VERSION ""

NS_ :

BS_:

BU_: PowertrainControlModule AtmosphericSensor SafetyRestraintSystem2 Aftertreatment_2_GasOutlet Aftertreatment_2_GasIntake DieselParticulateFilterControl Turbocharger SafetyRestraintSystem1 CabDisplay2 Aftertreatment_1_GasOutlet Aftertreatment_1_GasIntake OnBoardDataLogger OffBoardDiagnosticTool2 OffBoardDiagnosticTool1 FileServer ParkingBrakeController SeatController2 FanDriveController SteeringColumnUnit CommunicationUnitRadio CommunicationUnitSatellite CommunicationUnitCellular PropulsionBatteryCharger ChassisController2 ChassisController1 EngineValveControl AuxiliaryHeater2 AuxiliaryHeater1 ClutchUnit RampControl InformationSystem1 SuspensionSystemController2 OilSensor VehicleDynamicStability ExhaustEmissionController TransmissionDisplay2 TransmissionDisplay1 ClimateControl2 WaterPumpController RearAxleSteeringController LightingOperatorControl SeatController1 IgnitionController2 IgnitionController1 TirePressureController CabController2 CabController1 PneumaticSystemController SuspensionSystemController1 HydraulicPumpController EnduranceBrakingSystem RetarderExhaustEngine2 OnBoardDiagnosticUnit HeadwayController RetarderExhaustEngine1 CabDisplay1 ManagementComputer VirtualTerminal OffVehicleGateway PowerTakeOffFront HitchControl AuxiliaryValveControl BodyController TractorTrailerBridge1 StarterSystem ElectricalSystem VehicleSecurity VehicleNavigation AerodynamicControl ElectricalChargingSystem ClimateControl1 TripRecorder InstrumentCluster SuspensionDriveAxle2 SuspensionDriveAxle1 SuspensionSteerAxle SteeringController FuelSystem CruiseControl RetarderDriveline RetarderEngine BrakesDriveAxle2 BrakesDriveAxle1 BrakesSystemController BrakesSteerAxle AxleDrive2 AxleDrive1 AxleSteering PowerTakeOff ShiftConsoleSecondary ShiftConsolePrimary Transmission2 Transmission1 Engine2 Engine1

BO_ 2365402110 EJM6: 8 Vector__XXX
 SG_ Joystick6Button13PressedStatus : 62|2@1+ (1,0) [0|3] "" Vector__XXX
 SG_ Joystick6Button14PressedStatus : 60|2@1+ (1,0) [0|3] "" Vector__XXX
 SG_ Joystick6Button15PressedStatus : 58|2@1+ (1,0) [0|3] "" Vector__XXX
 SG_ Joystick6Button16PressedStatus : 56|2@1+ (1,0) [0|3] "" Vector__XXX
 SG_ Jystick6GripXAxisDetentPosStatus : 54|2@1+ (1,0) [0|3] "" Vector__XXX
 SG_ Jystick6GripYAxisDetentPosStatus : 52|2@1+ (1,0) [0|3] "" Vector__XXX
 SG_ Jystick6ThetaAxisDetentPosStatus : 50|2@1+ (1,0) [0|3] "" Vector__XXX
 SG_ Joystick6ThetaAxisPos : 38|10@1+ (0.1,0) [0|102] "%" Vector__XXX
 SG_ Jystck6ThtAxsClckwsPstvPosStatus : 36|2@1+ (1,0) [0|3] "" Vector__XXX
 SG_ Jystck6ThtAxsCntrClckwsNgtvPsStt : 34|2@1+ (1,0) [0|3] "" Vector__XXX
 SG_ Jystck6ThetaAxisNeutralPosStatus : 32|2@1+ (1,0) [0|3] "" Vector__XXX
 SG_ Joystick6GripYAxisPos : 22|10@1+ (0.1,0) [0|102] "%" Vector__XXX
 SG_ Jystck6GrpYAxsLvrFrwrdPstvPsStts : 20|2@1+ (1,0) [0|3] "" Vector__XXX
 SG_ Jystck6GrpYAxsLvrBckNgtvPsStatus : 18|2@1+ (1,0) [0|3] "" Vector__XXX
 SG_ Jystck6GripYAxisNeutralPosStatus : 16|2@1+ (1,0) [0|3] "" Vector__XXX
 SG_ Joystick6GripXAxisPos : 6|10@1+ (0.1,0) [0|102] "%" Vector__XXX
 SG_ Jystck6GrpXAxsLvrRghtPstvPsSttus : 4|2@1+ (1,0) [0|3] "" Vector__XXX
 SG_ Jystck6GrpXAxsLvrLftNgtvPsStatus : 2|2@1+ (1,0) [0|3] "" Vector__XXX
 SG_ Jystck6GripXAxisNeutralPosStatus : 0|2@1+ (1,0) [0|3] "" Vector__XXX

BO_ 2365402622 EJM5: 8 Vector__XXX
 SG_ Joystick5Button13PressedStatus : 62|2@1+ (1,0) [0|3] "" Vector__XXX
 SG_ Joystick5Button14PressedStatus : 60|2@1+ (1,0) [0|3] "" Vector__XXX
 SG_ Joystick5Button15PressedStatus : 58|2@1+ (1,0) [0|3] "" Vector__XXX
 SG_ Joystick5Button16PressedStatus : 56|2@1+ (1,0) [0|3] "" Vector__XXX
 SG_ Jystick5GripXAxisDetentPosStatus : 54|2@1+ (1,0) [0|3] "" Vector__XXX
 SG_ Jystick5GripYAxisDetentPosStatus : 52|2@1+ (1,0) [0|3] "" Vector__XXX
 SG_ Jystick5ThetaAxisDetentPosStatus : 50|2@1+ (1,0) [0|3] "" Vector__XXX
 SG_ Joystick5ThetaAxisPos : 38|10@1+ (0.1,0) [0|102] "%" Vector__XXX
 SG_ Jystck5ThtAxsClckwsPstvPosStatus : 36|2@1+ (1,0) [0|3] "" Vector__XXX
 SG_ Jystck5ThtAxsCntrClckwsNgtvPsStt : 34|2@1+ (1,0) [0|3] "" Vector__XXX
 SG_ Jystck5ThetaAxisNeutralPosStatus : 32|2@1+ (1,0) [0|3] "" Vector__XXX
 SG_ Joystick5GripYAxisPos : 22|10@1+ (0.1,0) [0|102] "%" Vector__XXX
 SG_ Jystck5GrpYAxsLvrFrwrdPstvPsStts : 20|2@1+ (1,0) [0|3] "" Vector__XXX
 SG_ Jystck5GrpYAxsLvrBckNgtvPsStatus : 18|2@1+ (1,0) [0|3] "" Vector__XXX
 SG_ Jystck5GripYAxisNeutralPosStatus : 16|2@1+ (1,0) [0|3] "" Vector__XXX
 SG_ Joystick5GripXAxisPos : 6|10@1+ (0.1,0) [0|102] "%" Vector__XXX
 SG_ Jystck5GrpXAxsLvrRghtPstvPsSttus : 4|2@1+ (1,0) [0|3] "" Vector__XXX
 SG_ Jystck5GrpXAxsLvrLftNgtvPsStatus : 2|2@1+ (1,0) [0|3] "" Vector__XXX
 SG_ Jystck5GripXAxisNeutralPosStatus : 0|2@1+ (1,0) [0|3] "" Vector__XXX

BO_ 2365403134 EJM4: 8 Vector__XXX
 SG_ Joystick4Button13PressedStatus : 62|2@1+ (1,0) [0|3] "" Vector__XXX
 SG_ Joystick4Button14PressedStatus : 60|2@1+ (1,0) [0|3] "" Vector__XXX
 SG_ Joystick4Button15PressedStatus : 58|2@1+ (1,0) [0|3] "" Vector__XXX
 SG_ Joystick4Button16PressedStatus : 56|2@1+ (1,0) [0|3] "" Vector__XXX
 SG_ Jystick4GripXAxisDetentPosStatus : 54|2@1+ (1,0) [0|3] "" Vector__XXX
 SG_ Jystick4GripYAxisDetentPosStatus : 52|2@1+ (1,0) [0|3] "" Vector__XXX
 SG_ Jystick4ThetaAxisDetentPosStatus : 50|2@1+ (1,0) [0|3] "" Vector__XXX
 SG_ Joystick4ThetaAxisPos : 38|10@1+ (0.1,0) [0|102] "%" Vector__XXX
 SG_ Jystck4ThtAxsClckwsPstvPosStatus : 36|2@1+ (1,0) [0|3] "" Vector__XXX
 SG_ Jystck4ThtAxsCntrClckwsNgtvPsStt : 34|2@1+ (1,0) [0|3] "" Vector__XXX
 SG_ Jystck4ThetaAxisNeutralPosStatus : 32|2@1+ (1,0) [0|3] "" Vector__XXX
 SG_ Joystick4GripYAxisPos : 22|10@1+ (0.1,0) [0|102] "%" Vector__XXX
 SG_ Jystck4GrpYAxsLvrFrwrdPstvPsStts : 20|2@1+ (1,0) [0|3] "" Vector__XXX
 SG_ Jystck4GrpYAxsLvrBckNgtvPsStatus : 18|2@1+ (1,0) [0|3] "" Vector__XXX
 SG_ Jystck4GripYAxisNeutralPosStatus : 16|2@1+ (1,0) [0|3] "" Vector__XXX
 SG_ Joystick4GripXAxisPos : 6|10@1+ (0.1,0) [0|102] "%" Vector__XXX
 SG_ Jystck4GrpXAxsLvrRghtPstvPsSttus : 4|2@1+ (1,0) [0|3] "" Vector__XXX
 SG_ Jystck4GrpXAxsLvrLftNgtvPsStatus : 2|2@1+ (1,0) [0|3] "" Vector__XXX
 SG_ Jystck4GripXAxisNeutralPosStatus : 0|2@1+ (1,0) [0|3] "" Vector__XXX

BO_ 2365400062 EJM10: 8 Vector__XXX
 SG_ Joystick10Button13PressedStatus : 62|2@1+ (1,0) [0|3] "" Vector__XXX
 SG_ Joystick10Button14PressedStatus : 60|2@1+ (1,0) [0|3] "" Vector__XXX
 SG_ Joystick10Button15PressedStatus : 58|2@1+ (1,0) [0|3] "" Vector__XXX
 SG_ Joystick10Button16PressedStatus : 56|2@1+ (1,0) [0|3] "" Vector__XXX
 SG_ Jystck10GripXAxisDetentPosStatus : 54|2@1+ (1,0) [0|3] "" Vector__XXX
 SG_ Jystck10GripYAxisDetentPosStatus : 52|2@1+ (1,0) [0|3] "" Vector__XXX
 SG_ Jystck10ThetaAxisDetentPosStatus : 50|2@1+ (1,0) [0|3] "" Vector__XXX
 SG_ Joystick10ThetaAxisPos : 38|10@1+ (0.1,0) [0|102] "%" Vector__XXX
 SG_ Jystck10ThtAxsClckwsPstvPsStatus : 36|2@1+ (1,0) [0|3] "" Vector__XXX
 SG_ Jystck10ThtAxsCntrClckwsNgtvPsSt : 34|2@1+ (1,0) [0|3] "" Vector__XXX
 SG_ Jystck10ThtaAxisNeutralPosStatus : 32|2@1+ (1,0) [0|3] "" Vector__XXX
 SG_ Joystick10GripYAxisPos : 22|10@1+ (0.1,0) [0|102] "%" Vector__XXX
 SG_ Jystck10GrpYAxsLvrFrwrdPstvPsStt : 20|2@1+ (1,0) [0|3] "" Vector__XXX
 SG_ Jystck10GrpYAxsLvrBckNgtvPsSttus : 18|2@1+ (1,0) [0|3] "" Vector__XXX
 SG_ Jystck10GrpYAxisNeutralPosStatus : 16|2@1+ (1,0) [0|3] "" Vector__XXX
 SG_ Joystick10GripXAxisPos : 6|10@1+ (0.1,0) [0|102] "%" Vector__XXX
 SG_ Jystck10GrpXAxsLvrRghtPstvPsStts : 4|2@1+ (1,0) [0|3] "" Vector__XXX
 SG_ Jystck10GrpXAxsLvrLftNgtvPsSttus : 2|2@1+ (1,0) [0|3] "" Vector__XXX
 SG_ Jystck10GrpXAxisNeutralPosStatus : 0|2@1+ (1,0) [0|3] "" Vector__XXX

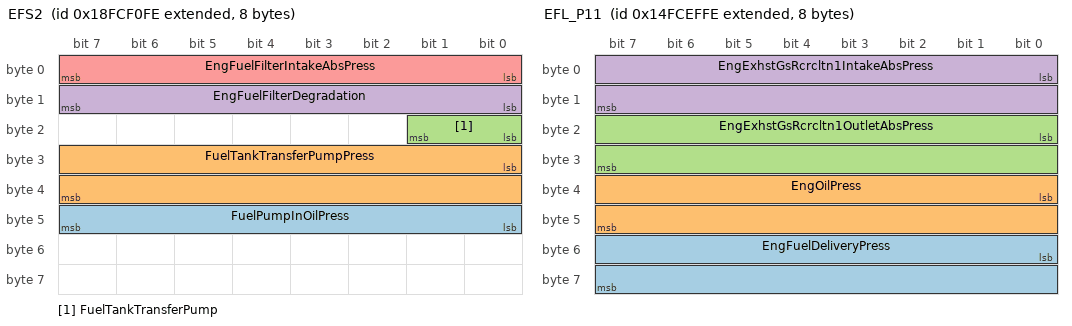
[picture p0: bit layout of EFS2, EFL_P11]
BO_ 2566713598 EFS2: 8 Vector__XXX
 SG_ FuelPumpInOilPress : 40|8@1+ (4,0) [0|1000] "kPa" Vector__XXX
 SG_ FuelTankTransferPumpPress : 24|16@1+ (0.1,0) [0|6425.5] "kPa" Vector__XXX
 SG_ FuelTankTransferPump : 16|2@1+ (1,0) [0|3] "" Vector__XXX
 SG_ EngFuelFilterDegradation : 8|8@1+ (1,0) [0|250] "%" Vector__XXX
 SG_ EngFuelFilterIntakeAbsPress : 0|8@1+ (2,0) [0|500] "kPa" Vector__XXX

BO_ 2499604478 EFL_P11: 8 Vector__XXX
 SG_ EngFuelDeliveryPress : 48|16@1+ (0.1,0) [0|6425.5] "kPa" Vector__XXX
 SG_ EngOilPress : 32|16@1+ (0.1,0) [0|6425.5] "kPa" Vector__XXX
 SG_ EngExhstGsRcrcltn1OutletAbsPress : 16|16@1+ (0.1,0) [0|6425.5] "kPa" Vector__XXX
 SG_ EngExhstGsRcrcltn1IntakeAbsPress : 0|16@1+ (0.1,0) [0|6425.5] "kPa" Vector__XXX

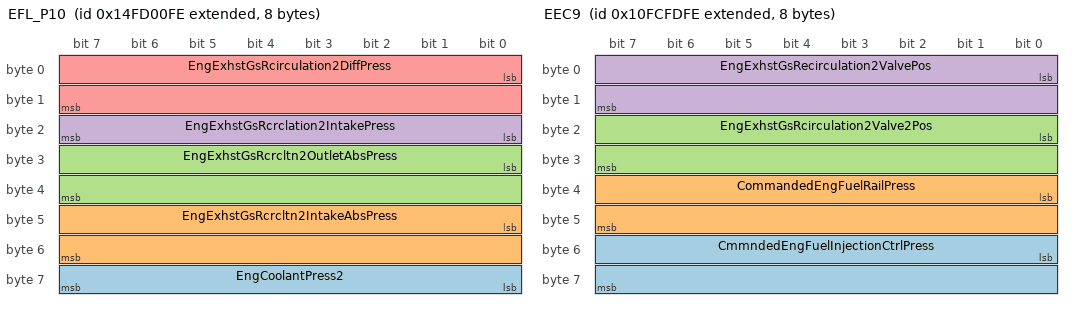
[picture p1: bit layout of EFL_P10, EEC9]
BO_ 2499608830 EFL_P10: 8 Vector__XXX
 SG_ EngCoolantPress2 : 56|8@1+ (2,0) [0|500] "kPa" Vector__XXX
 SG_ EngExhstGsRcrcltn2IntakeAbsPress : 40|16@1+ (0.1,0) [0|6425.5] "kPa" Vector__XXX
 SG_ EngExhstGsRcrcltn2OutletAbsPress : 24|16@1+ (0.1,0) [0|6425.5] "kPa" Vector__XXX
 SG_ EngExhstGsRcrclation2IntakePress : 16|8@1+ (2,0) [0|500] "kPa" Vector__XXX
 SG_ EngExhstGsRcirculation2DiffPress : 0|16@1+ (0.0078125,-250) [-250|251.99] "kPa" Vector__XXX

BO_ 2432499198 EEC9: 8 Vector__XXX
 SG_ CmmndedEngFuelInjectionCtrlPress : 48|16@1+ (0.00390625,0) [0|250.996] "MPa" Vector__XXX
 SG_ CommandedEngFuelRailPress : 32|16@1+ (0.00390625,0) [0|250.996] "MPa" Vector__XXX
 SG_ EngExhstGsRcirculation2Valve2Pos : 16|16@1+ (0.0025,0) [0|160.6375] "%" Vector__XXX
 SG_ EngExhstGsRecirculation2ValvePos : 0|16@1+ (0.0025,0) [0|160.6375] "%" Vector__XXX

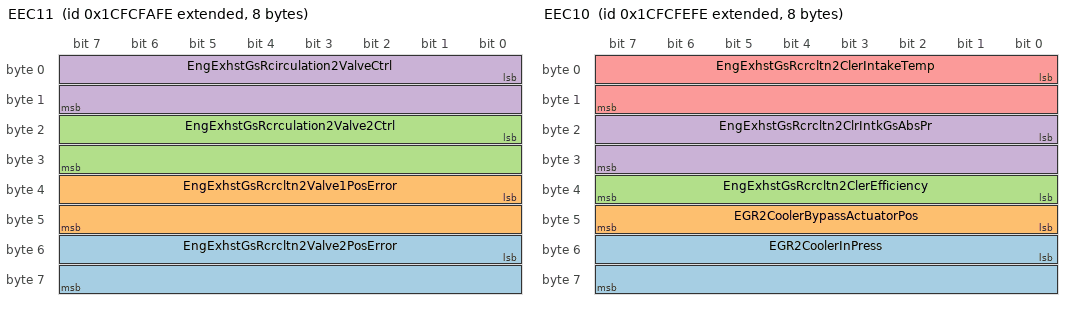
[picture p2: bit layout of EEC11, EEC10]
BO_ 2633825022 EEC11: 8 Vector__XXX
 SG_ EngExhstGsRcrcltn2Valve2PosError : 48|16@1+ (0.004,-125) [-125|132.02] "%" Vector__XXX
 SG_ EngExhstGsRcrcltn2Valve1PosError : 32|16@1+ (0.004,-125) [-125|132.02] "%" Vector__XXX
 SG_ EngExhstGsRcrculation2Valve2Ctrl : 16|16@1+ (0.0025,0) [0|160.6375] "%" Vector__XXX
 SG_ EngExhstGsRcirculation2ValveCtrl : 0|16@1+ (0.0025,0) [0|160.6375] "%" Vector__XXX

BO_ 2633826046 EEC10: 8 Vector__XXX
 SG_ EGR2CoolerInPress : 48|16@1+ (5,0) [0|321275] "kPa" Vector__XXX
 SG_ EGR2CoolerBypassActuatorPos : 40|8@1+ (0.4,0) [0|100] "%" Vector__XXX
 SG_ EngExhstGsRcrcltn2ClerEfficiency : 32|8@1+ (0.4,0) [0|100] "%" Vector__XXX
 SG_ EngExhstGsRcrcltn2ClrIntkGsAbsPr : 16|16@1+ (0.5,0) [0|32127.5] "kPa" Vector__XXX
 SG_ EngExhstGsRcrcltn2ClerIntakeTemp : 0|16@1+ (0.03125,-273) [-273|1734.96875] "캜" Vector__XXX

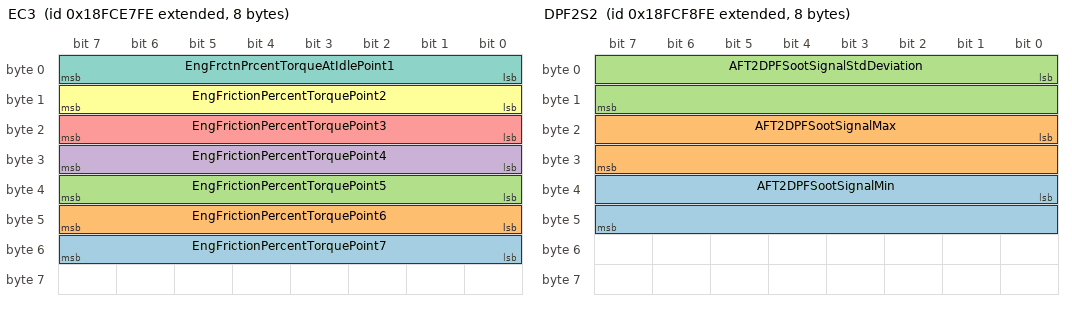
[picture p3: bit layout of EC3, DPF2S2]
BO_ 2566711294 EC3: 8 Vector__XXX
 SG_ EngFrictionPercentTorquePoint7 : 48|8@1+ (1,-125) [0|125] "%" Vector__XXX
 SG_ EngFrictionPercentTorquePoint6 : 40|8@1+ (1,-125) [0|125] "%" Vector__XXX
 SG_ EngFrictionPercentTorquePoint5 : 32|8@1+ (1,-125) [0|125] "%" Vector__XXX
 SG_ EngFrictionPercentTorquePoint4 : 24|8@1+ (1,-125) [0|125] "%" Vector__XXX
 SG_ EngFrictionPercentTorquePoint3 : 16|8@1+ (1,-125) [0|125] "%" Vector__XXX
 SG_ EngFrictionPercentTorquePoint2 : 8|8@1+ (1,-125) [0|125] "%" Vector__XXX
 SG_ EngFrctnPrcentTorqueAtIdlePoint1 : 0|8@1+ (1,-125) [0|125] "%" Vector__XXX

BO_ 2566749438 DPFC1: 8 Vector__XXX
 SG_ ActiveRegenAvailabilityStatus : 3|2@1+ (1,0) [0|3] "" Vector__XXX
 SG_ DslPrtcltFltrActvRgnrtnInhbt5629 : 58|2@1+ (1,0) [0|3] "" Vector__XXX
 SG_ AFT1DPFCondNotMetForActiveRegen : 60|2@1+ (1,0) [0|3] "" Vector__XXX
 SG_ HydrocarbonDoserPurgingEnable : 56|2@1+ (1,0) [0|3] "" Vector__XXX
 SG_ DslPrtcltFltrActvRgnrtnFrcdSttus : 53|3@1+ (1,0) [0|7] "" Vector__XXX
 SG_ ExhaustSystemHighTempLampCmd : 50|3@1+ (1,0) [0|7] "" Vector__XXX
 SG_ DslPrtcltFltrAtmtcActvRgnrtnIntt : 48|2@1+ (1,0) [0|3] "" Vector__XXX
 SG_ DslPrtcltFltrActvRgnrtnInhbt3717 : 46|2@1+ (1,0) [0|3] "" Vector__XXX
 SG_ DslPrtcltFltrActvRgnrtnInhbtdDTE : 44|2@1+ (1,0) [0|3] "" Vector__XXX
 SG_ DslPrtcltFltrActvRgnrtnInhbt3715 : 42|2@1+ (1,0) [0|3] "" Vector__XXX
 SG_ DslPrtcltFltrActvRgnrtnInhbtdDTT : 40|2@1+ (1,0) [0|3] "" Vector__XXX
 SG_ DslPrtcltFltrActvRgnrtnInhbt3713 : 38|2@1+ (1,0) [0|3] "" Vector__XXX
 SG_ DslPrtcltFltrActvRgnrtnInhbt3712 : 36|2@1+ (1,0) [0|3] "" Vector__XXX
 SG_ DslPrtcltFltrActvRgnrtnInhbtdDTL : 34|2@1+ (1,0) [0|3] "" Vector__XXX
 SG_ DslPrtcltFltrActvRgnrtnInhbt3710 : 32|2@1+ (1,0) [0|3] "" Vector__XXX
 SG_ DslPrtcltFltrActvRgnrtnInhbtdDTV : 30|2@1+ (1,0) [0|3] "" Vector__XXX
 SG_ DslPrtcltFltrActvRgnrtnInhbtdDTO : 28|2@1+ (1,0) [0|3] "" Vector__XXX
 SG_ DslPrtcltFltrActvRgnrtnInhbtdDTA : 26|2@1+ (1,0) [0|3] "" Vector__XXX
 SG_ DslPrtcltFltrActvRgnrtnInhbtdDTP : 24|2@1+ (1,0) [0|3] "" Vector__XXX
 SG_ DslPrtcltFltrActvRgnrtnInhbtdDTS : 22|2@1+ (1,0) [0|3] "" Vector__XXX
 SG_ DslPrtcltFltrActvRgnrtnInhbtdDTC : 20|2@1+ (1,0) [0|3] "" Vector__XXX
 SG_ DslPrtcltFltrActvRgnrtnInhbtdDTI : 18|2@1+ (1,0) [0|3] "" Vector__XXX
 SG_ DslPrtcltFltrActvRgnrtnInhbtdStt : 16|2@1+ (1,0) [0|3] "" Vector__XXX
 SG_ AFTDPFStatus : 12|3@1+ (1,0) [0|7] "" Vector__XXX
 SG_ AFTDPFActiveRegenStatus : 10|2@1+ (1,0) [0|3] "" Vector__XXX
 SG_ AFTDPFPassiveRegenStatus : 8|2@1+ (1,0) [0|3] "" Vector__XXX
 SG_ DieselParticulateFilterLampCmd : 0|3@1+ (1,0) [0|7] "" Vector__XXX

BO_ 2566715646 DPF2S2: 8 Vector__XXX
 SG_ AFT2DPFSootSignalMin : 32|16@1+ (0.0025,0) [0|160.6375] "%" Vector__XXX
 SG_ AFT2DPFSootSignalMax : 16|16@1+ (0.0025,0) [0|160.6375] "%" Vector__XXX
 SG_ AFT2DPFSootSignalStdDeviation : 0|16@1+ (0.0025,0) [0|160.6375] "%" Vector__XXX

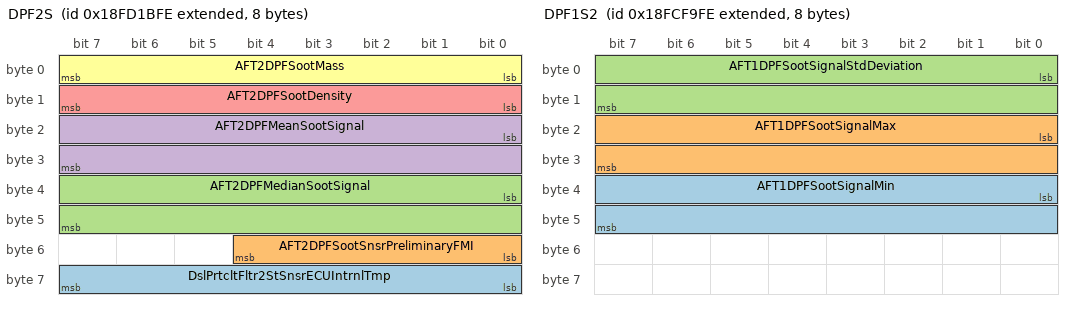
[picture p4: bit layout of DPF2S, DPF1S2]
BO_ 2566724606 DPF2S: 8 Vector__XXX
 SG_ DslPrtcltFltr2StSnsrECUIntrnlTmp : 56|8@1+ (1,-40) [-40|210] "캜" Vector__XXX
 SG_ AFT2DPFSootSnsrPreliminaryFMI : 48|5@1+ (1,0) [0|31] "" Vector__XXX
 SG_ AFT2DPFMedianSootSignal : 32|16@1+ (0.0025,0) [0|160.6375] "%" Vector__XXX
 SG_ AFT2DPFMeanSootSignal : 16|16@1+ (0.0025,0) [0|160.6375] "%" Vector__XXX
 SG_ AFT2DPFSootDensity : 8|8@1+ (0.08,0) [0|20] "g/L" Vector__XXX
 SG_ AFT2DPFSootMass : 0|8@1+ (4,0) [0|1000] "g" Vector__XXX

BO_ 2566715902 DPF1S2: 8 Vector__XXX
 SG_ AFT1DPFSootSignalMin : 32|16@1+ (0.0025,0) [0|160.6375] "%" Vector__XXX
 SG_ AFT1DPFSootSignalMax : 16|16@1+ (0.0025,0) [0|160.6375] "%" Vector__XXX
 SG_ AFT1DPFSootSignalStdDeviation : 0|16@1+ (0.0025,0) [0|160.6375] "%" Vector__XXX

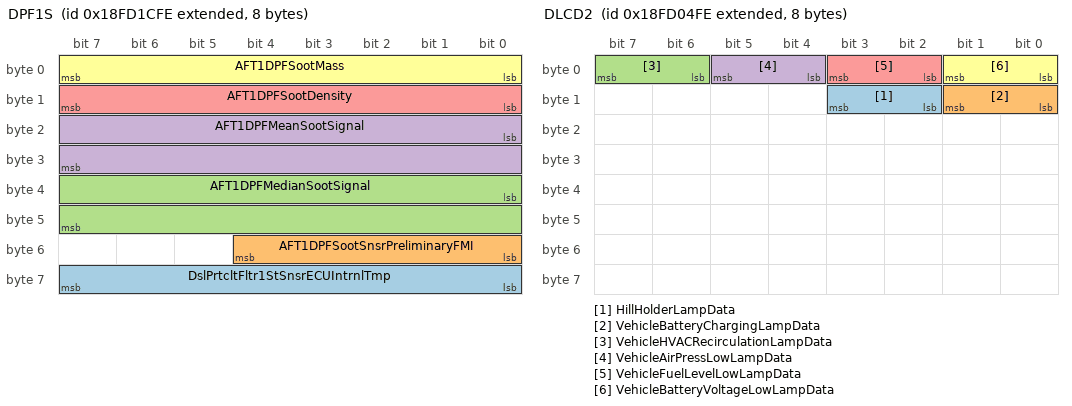
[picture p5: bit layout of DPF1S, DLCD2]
BO_ 2566724862 DPF1S: 8 Vector__XXX
 SG_ DslPrtcltFltr1StSnsrECUIntrnlTmp : 56|8@1+ (1,-40) [-40|210] "캜" Vector__XXX
 SG_ AFT1DPFSootSnsrPreliminaryFMI : 48|5@1+ (1,0) [0|31] "" Vector__XXX
 SG_ AFT1DPFMedianSootSignal : 32|16@1+ (0.0025,0) [0|160.6375] "%" Vector__XXX
 SG_ AFT1DPFMeanSootSignal : 16|16@1+ (0.0025,0) [0|160.6375] "%" Vector__XXX
 SG_ AFT1DPFSootDensity : 8|8@1+ (0.08,0) [0|20] "g/L" Vector__XXX
 SG_ AFT1DPFSootMass : 0|8@1+ (4,0) [0|1000] "g" Vector__XXX

BO_ 2566718718 DLCD2: 8 Vector__XXX
 SG_ HillHolderLampData : 10|2@1+ (1,0) [0|3] "" Vector__XXX
 SG_ VehicleBatteryChargingLampData : 8|2@1+ (1,0) [0|3] "" Vector__XXX
 SG_ VehicleHVACRecirculationLampData : 6|2@1+ (1,0) [0|3] "" Vector__XXX
 SG_ VehicleAirPressLowLampData : 4|2@1+ (1,0) [0|3] "" Vector__XXX
 SG_ VehicleFuelLevelLowLampData : 2|2@1+ (1,0) [0|3] "" Vector__XXX
 SG_ VehicleBatteryVoltageLowLampData : 0|2@1+ (1,0) [0|3] "" Vector__XXX

BO_ 2566718974 DLCD1: 8 Vector__XXX
 SG_ EngStopStartEnabledLamp : 42|2@1+ (1,0) [0|3] "" Vector__XXX
 SG_ EngStopStartAutoStartFailedLamp : 40|2@1+ (1,0) [0|3] "" Vector__XXX
 SG_ EngStopStartAutoStopActiveLamp : 38|2@1+ (1,0) [0|3] "" Vector__XXX
 SG_ VhclAcclerationRateLimitLampData : 34|2@1+ (1,0) [0|3] "" Vector__XXX
 SG_ EngSpeedVeryHighLampData : 32|2@1+ (1,0) [0|3] "" Vector__XXX
 SG_ EngSpeedHighLampData : 30|2@1+ (1,0) [0|3] "" Vector__XXX
 SG_ EngCtrlMdule3ReadyForUseLampData : 28|2@1+ (1,0) [0|3] "" Vector__XXX
 SG_ EngCtrlMdule2ReadyForUseLampData : 26|2@1+ (1,0) [0|3] "" Vector__XXX
 SG_ EngCtrlMdule1ReadyForUseLampData : 24|2@1+ (1,0) [0|3] "" Vector__XXX
 SG_ EngWaitToStartLampData : 62|2@1+ (1,0) [0|3] "" Vector__XXX
 SG_ EngFuelFilterRestrictedLampData : 22|2@1+ (1,0) [0|3] "" Vector__XXX
 SG_ EngAirFilterRestrictionLampData : 20|2@1+ (1,0) [0|3] "" Vector__XXX
 SG_ EngIdleManagementActiveLampData : 18|2@1+ (1,0) [0|3] "" Vector__XXX
 SG_ EngCoolantLevelLowLampData : 16|2@1+ (1,0) [0|3] "" Vector__XXX
 SG_ EngCoolantTempHighLampData : 14|2@1+ (1,0) [0|3] "" Vector__XXX
 SG_ EngOilPressLowLampData : 12|2@1+ (1,0) [0|3] "" Vector__XXX
 SG_ CmprssnBrkEnblSwtchIndctrLmpData : 10|2@1+ (1,0) [0|3] "" Vector__XXX
 SG_ EngBrakeActiveLampData : 8|2@1+ (1,0) [0|3] "" Vector__XXX
 SG_ OBDMalfunctionIndicatorLampData : 6|2@1+ (1,0) [0|3] "" Vector__XXX
 SG_ EngRedStopLampData : 4|2@1+ (1,0) [0|3] "" Vector__XXX
 SG_ EngAmberWarningLampData : 2|2@1+ (1,0) [0|3] "" Vector__XXX
 SG_ EngProtectLampData : 0|2@1+ (1,0) [0|3] "" Vector__XXX

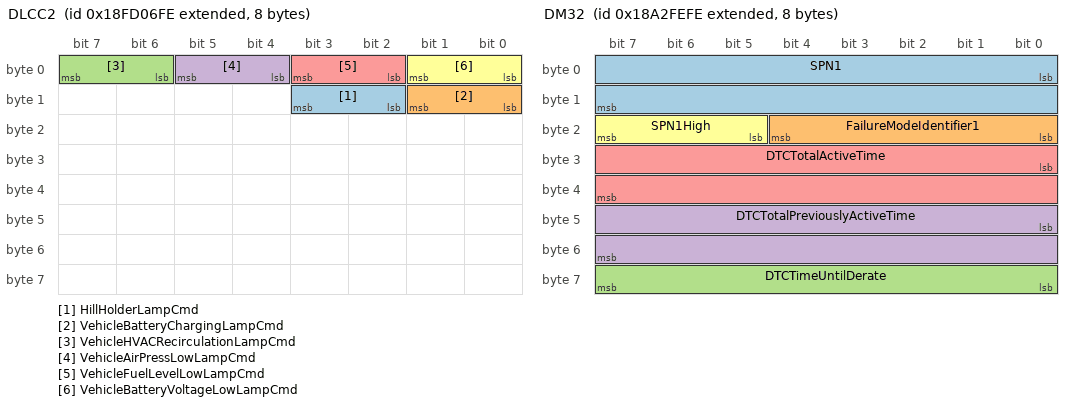
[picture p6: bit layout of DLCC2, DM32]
BO_ 2566719230 DLCC2: 8 Vector__XXX
 SG_ HillHolderLampCmd : 10|2@1+ (1,0) [0|3] "" Vector__XXX
 SG_ VehicleBatteryChargingLampCmd : 8|2@1+ (1,0) [0|3] "" Vector__XXX
 SG_ VehicleHVACRecirculationLampCmd : 6|2@1+ (1,0) [0|3] "" Vector__XXX
 SG_ VehicleAirPressLowLampCmd : 4|2@1+ (1,0) [0|3] "" Vector__XXX
 SG_ VehicleFuelLevelLowLampCmd : 2|2@1+ (1,0) [0|3] "" Vector__XXX
 SG_ VehicleBatteryVoltageLowLampCmd : 0|2@1+ (1,0) [0|3] "" Vector__XXX

BO_ 2560818942 DM32: 8 Vector__XXX
 SG_ SPN1 : 0|16@1+ (1,0) [0|65536] "" Vector__XXX
 SG_ FailureModeIdentifier1 : 16|5@1+ (1,0) [0|0] "" Vector__XXX
 SG_ DTCTimeUntilDerate : 56|8@1+ (0.25,0) [0|62.5] "hr" Vector__XXX
 SG_ DTCTotalPreviouslyActiveTime : 40|16@1+ (0.2,0) [0|12851] "hr" Vector__XXX
 SG_ DTCTotalActiveTime : 24|16@1+ (0.2,0) [0|12851] "hr" Vector__XXX
 SG_ SPN1High : 21|3@1+ (1,0) [0|7] "" Vector__XXX

BO_ 2561212158 DISP1: 8 Vector__XXX
 SG_ TextDisplayIndex : 16|8@1+ (1,0) [0|200] "" Vector__XXX
 SG_ TextDisplayInstructions : 0|4@1+ (1,0) [0|15] "" Vector__XXX

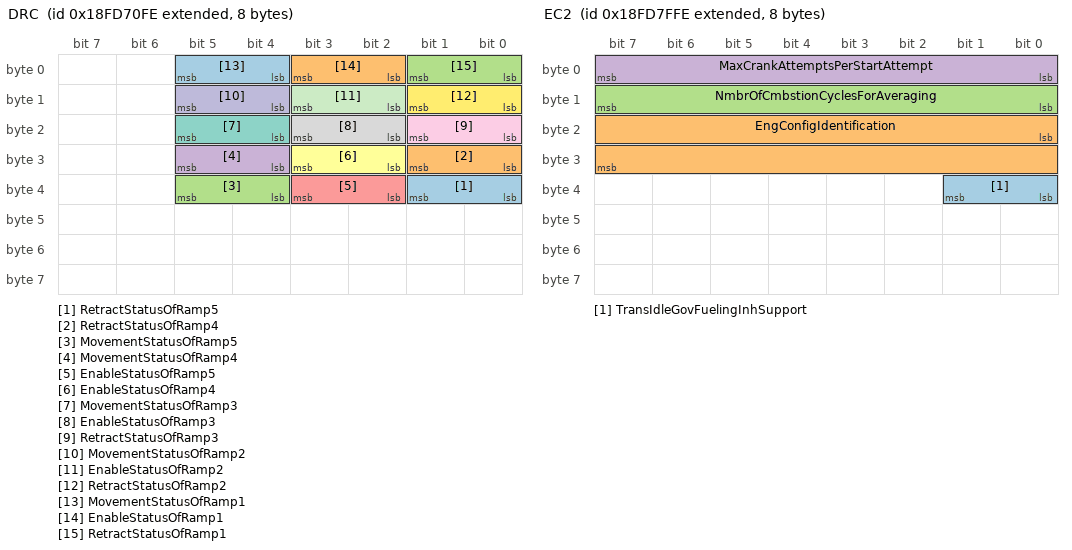
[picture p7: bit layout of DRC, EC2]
BO_ 2566746366 DRC: 8 Vector__XXX
 SG_ RetractStatusOfRamp5 : 32|2@1+ (1,0) [0|3] "" Vector__XXX
 SG_ RetractStatusOfRamp4 : 24|2@1+ (1,0) [0|3] "" Vector__XXX
 SG_ MovementStatusOfRamp5 : 36|2@1+ (1,0) [0|3] "" Vector__XXX
 SG_ MovementStatusOfRamp4 : 28|2@1+ (1,0) [0|3] "" Vector__XXX
 SG_ EnableStatusOfRamp5 : 34|2@1+ (1,0) [0|3] "" Vector__XXX
 SG_ EnableStatusOfRamp4 : 26|2@1+ (1,0) [0|3] "" Vector__XXX
 SG_ MovementStatusOfRamp3 : 20|2@1+ (1,0) [0|3] "" Vector__XXX
 SG_ EnableStatusOfRamp3 : 18|2@1+ (1,0) [0|3] "" Vector__XXX
 SG_ RetractStatusOfRamp3 : 16|2@1+ (1,0) [0|3] "" Vector__XXX
 SG_ MovementStatusOfRamp2 : 12|2@1+ (1,0) [0|3] "" Vector__XXX
 SG_ EnableStatusOfRamp2 : 10|2@1+ (1,0) [0|3] "" Vector__XXX
 SG_ RetractStatusOfRamp2 : 8|2@1+ (1,0) [0|3] "" Vector__XXX
 SG_ MovementStatusOfRamp1 : 4|2@1+ (1,0) [0|3] "" Vector__XXX
 SG_ EnableStatusOfRamp1 : 2|2@1+ (1,0) [0|3] "" Vector__XXX
 SG_ RetractStatusOfRamp1 : 0|2@1+ (1,0) [0|3] "" Vector__XXX

BO_ 2566750206 EC2: 8 Vector__XXX
 SG_ TransIdleGovFuelingInhSupport : 32|2@1+ (1,0) [0|3] "" Vector__XXX
 SG_ EngConfigIdentification : 16|16@1+ (1,0) [0|64255] "" Vector__XXX
 SG_ NmbrOfCmbstionCyclesForAveraging : 8|8@1+ (1,0) [1|250] "" Vector__XXX
 SG_ MaxCrankAttemptsPerStartAttempt : 0|8@1+ (1,0) [0|250] "" Vector__XXX

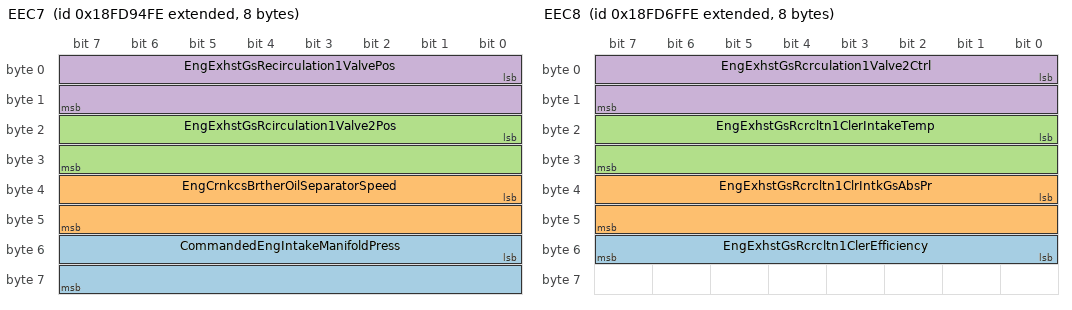
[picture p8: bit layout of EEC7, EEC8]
BO_ 2566755582 EEC7: 8 Vector__XXX
 SG_ CommandedEngIntakeManifoldPress : 48|16@1+ (0.125,0) [0|8031.875] "kPa" Vector__XXX
 SG_ EngCrnkcsBrtherOilSeparatorSpeed : 32|16@1+ (1,0) [0|64255] "rpm" Vector__XXX
 SG_ EngExhstGsRcirculation1Valve2Pos : 16|16@1+ (0.0025,0) [0|160.6375] "%" Vector__XXX
 SG_ EngExhstGsRecirculation1ValvePos : 0|16@1+ (0.0025,0) [0|160.6375] "%" Vector__XXX

BO_ 2566746110 EEC8: 8 Vector__XXX
 SG_ EngExhstGsRcrcltn1ClerEfficiency : 48|8@1+ (0.4,0) [0|100] "%" Vector__XXX
 SG_ EngExhstGsRcrcltn1ClrIntkGsAbsPr : 32|16@1+ (0.5,0) [0|32127.5] "kPa" Vector__XXX
 SG_ EngExhstGsRcrcltn1ClerIntakeTemp : 16|16@1+ (0.03125,-273) [-273|1734.96875] "캜" Vector__XXX
 SG_ EngExhstGsRcrculation1Valve2Ctrl : 0|16@1+ (0.0025,0) [0|160.6375] "%" Vector__XXX

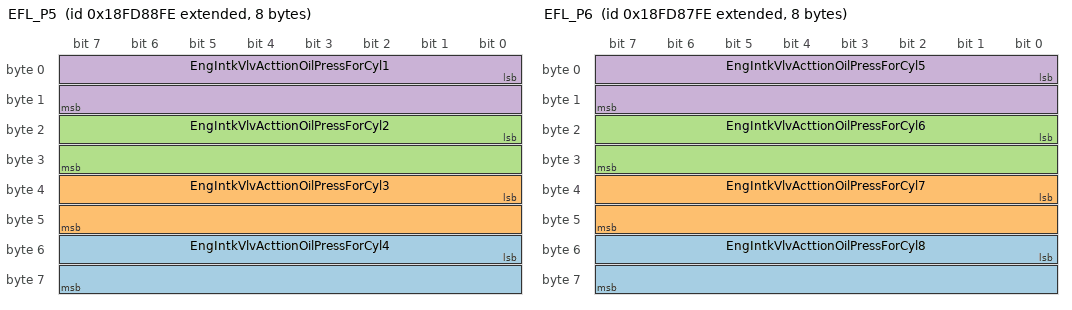
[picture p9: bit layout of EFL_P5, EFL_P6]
BO_ 2566752510 EFL_P5: 8 Vector__XXX
 SG_ EngIntkVlvActtionOilPressForCyl4 : 48|16@1+ (0.1,0) [0|6425.5] "kPa" Vector__XXX
 SG_ EngIntkVlvActtionOilPressForCyl3 : 32|16@1+ (0.1,0) [0|6425.5] "kPa" Vector__XXX
 SG_ EngIntkVlvActtionOilPressForCyl2 : 16|16@1+ (0.1,0) [0|6425.5] "kPa" Vector__XXX
 SG_ EngIntkVlvActtionOilPressForCyl1 : 0|16@1+ (0.1,0) [0|6425.5] "kPa" Vector__XXX

BO_ 2566752254 EFL_P6: 8 Vector__XXX
 SG_ EngIntkVlvActtionOilPressForCyl8 : 48|16@1+ (0.1,0) [0|6425.5] "kPa" Vector__XXX
 SG_ EngIntkVlvActtionOilPressForCyl7 : 32|16@1+ (0.1,0) [0|6425.5] "kPa" Vector__XXX
 SG_ EngIntkVlvActtionOilPressForCyl6 : 16|16@1+ (0.1,0) [0|6425.5] "kPa" Vector__XXX
 SG_ EngIntkVlvActtionOilPressForCyl5 : 0|16@1+ (0.1,0) [0|6425.5] "kPa" Vector__XXX

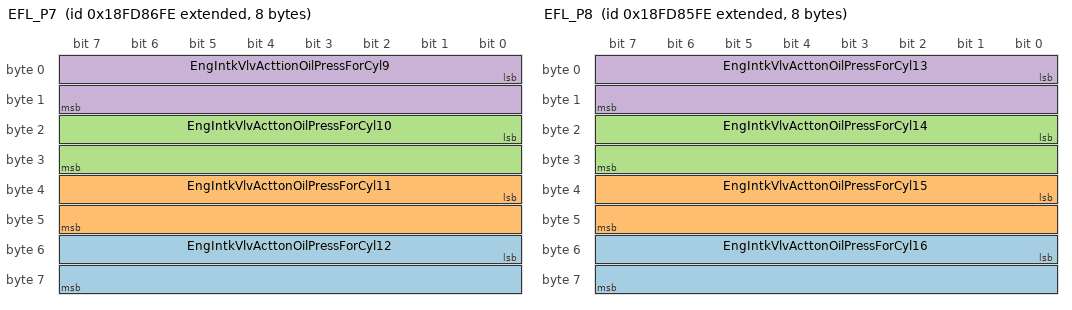
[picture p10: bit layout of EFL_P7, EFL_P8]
BO_ 2566751998 EFL_P7: 8 Vector__XXX
 SG_ EngIntkVlvActtonOilPressForCyl12 : 48|16@1+ (0.1,0) [0|6425.5] "kPa" Vector__XXX
 SG_ EngIntkVlvActtonOilPressForCyl11 : 32|16@1+ (0.1,0) [0|6425.5] "kPa" Vector__XXX
 SG_ EngIntkVlvActtonOilPressForCyl10 : 16|16@1+ (0.1,0) [0|6425.5] "kPa" Vector__XXX
 SG_ EngIntkVlvActtionOilPressForCyl9 : 0|16@1+ (0.1,0) [0|6425.5] "kPa" Vector__XXX

BO_ 2566751742 EFL_P8: 8 Vector__XXX
 SG_ EngIntkVlvActtonOilPressForCyl16 : 48|16@1+ (0.1,0) [0|6425.5] "kPa" Vector__XXX
 SG_ EngIntkVlvActtonOilPressForCyl15 : 32|16@1+ (0.1,0) [0|6425.5] "kPa" Vector__XXX
 SG_ EngIntkVlvActtonOilPressForCyl14 : 16|16@1+ (0.1,0) [0|6425.5] "kPa" Vector__XXX
 SG_ EngIntkVlvActtonOilPressForCyl13 : 0|16@1+ (0.1,0) [0|6425.5] "kPa" Vector__XXX

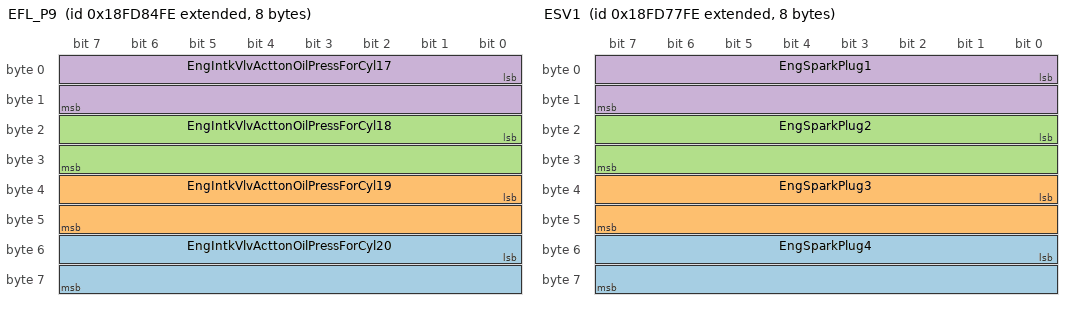
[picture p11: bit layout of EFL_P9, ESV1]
BO_ 2566751486 EFL_P9: 8 Vector__XXX
 SG_ EngIntkVlvActtonOilPressForCyl20 : 48|16@1+ (0.1,0) [0|6425.5] "kPa" Vector__XXX
 SG_ EngIntkVlvActtonOilPressForCyl19 : 32|16@1+ (0.1,0) [0|6425.5] "kPa" Vector__XXX
 SG_ EngIntkVlvActtonOilPressForCyl18 : 16|16@1+ (0.1,0) [0|6425.5] "kPa" Vector__XXX
 SG_ EngIntkVlvActtonOilPressForCyl17 : 0|16@1+ (0.1,0) [0|6425.5] "kPa" Vector__XXX

BO_ 2499641854 EGRBV: 8 Vector__XXX
 SG_ EGR1CoolerBypassActuatorPostion : 0|8@1+ (0.4,0) [0|100] "%" Vector__XXX

BO_ 2566748158 ESV1: 8 Vector__XXX
 SG_ EngSparkPlug4 : 48|16@1+ (1,0) [0|64255] "V" Vector__XXX
 SG_ EngSparkPlug3 : 32|16@1+ (1,0) [0|64255] "V" Vector__XXX
 SG_ EngSparkPlug2 : 16|16@1+ (1,0) [0|64255] "V" Vector__XXX
 SG_ EngSparkPlug1 : 0|16@1+ (1,0) [0|64255] "V" Vector__XXX

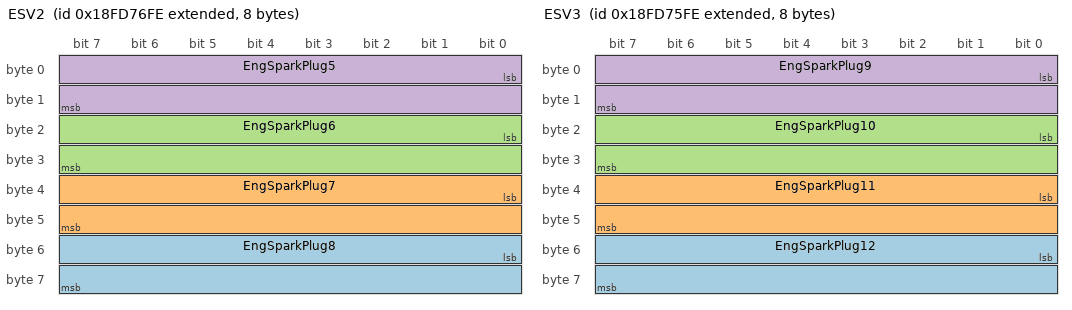
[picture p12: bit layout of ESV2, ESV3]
BO_ 2566747902 ESV2: 8 Vector__XXX
 SG_ EngSparkPlug8 : 48|16@1+ (1,0) [0|64255] "V" Vector__XXX
 SG_ EngSparkPlug7 : 32|16@1+ (1,0) [0|64255] "V" Vector__XXX
 SG_ EngSparkPlug6 : 16|16@1+ (1,0) [0|64255] "V" Vector__XXX
 SG_ EngSparkPlug5 : 0|16@1+ (1,0) [0|64255] "V" Vector__XXX

BO_ 2566747646 ESV3: 8 Vector__XXX
 SG_ EngSparkPlug12 : 48|16@1+ (1,0) [0|64255] "V" Vector__XXX
 SG_ EngSparkPlug11 : 32|16@1+ (1,0) [0|64255] "V" Vector__XXX
 SG_ EngSparkPlug10 : 16|16@1+ (1,0) [0|64255] "V" Vector__XXX
 SG_ EngSparkPlug9 : 0|16@1+ (1,0) [0|64255] "V" Vector__XXX

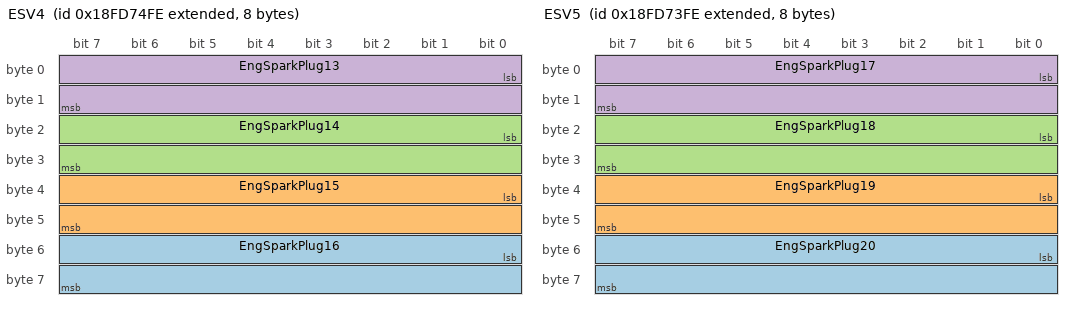
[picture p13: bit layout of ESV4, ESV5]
BO_ 2566747390 ESV4: 8 Vector__XXX
 SG_ EngSparkPlug16 : 48|16@1+ (1,0) [0|64255] "V" Vector__XXX
 SG_ EngSparkPlug15 : 32|16@1+ (1,0) [0|64255] "V" Vector__XXX
 SG_ EngSparkPlug14 : 16|16@1+ (1,0) [0|64255] "V" Vector__XXX
 SG_ EngSparkPlug13 : 0|16@1+ (1,0) [0|64255] "V" Vector__XXX

BO_ 2566747134 ESV5: 8 Vector__XXX
 SG_ EngSparkPlug20 : 48|16@1+ (1,0) [0|64255] "V" Vector__XXX
 SG_ EngSparkPlug19 : 32|16@1+ (1,0) [0|64255] "V" Vector__XXX
 SG_ EngSparkPlug18 : 16|16@1+ (1,0) [0|64255] "V" Vector__XXX
 SG_ EngSparkPlug17 : 0|16@1+ (1,0) [0|64255] "V" Vector__XXX

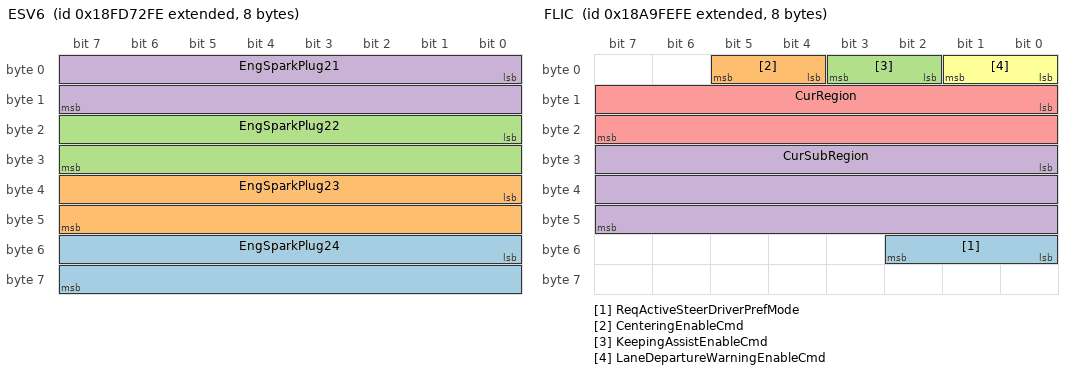
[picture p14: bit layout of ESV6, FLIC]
BO_ 2566746878 ESV6: 8 Vector__XXX
 SG_ EngSparkPlug24 : 48|16@1+ (1,0) [0|64255] "V" Vector__XXX
 SG_ EngSparkPlug23 : 32|16@1+ (1,0) [0|64255] "V" Vector__XXX
 SG_ EngSparkPlug22 : 16|16@1+ (1,0) [0|64255] "V" Vector__XXX
 SG_ EngSparkPlug21 : 0|16@1+ (1,0) [0|64255] "V" Vector__XXX

BO_ 2561277694 FLIC: 8 Vector__XXX
 SG_ ReqActiveSteerDriverPrefMode : 48|3@1+ (1,0) [0|7] "" Vector__XXX
 SG_ CenteringEnableCmd : 4|2@1+ (1,0) [0|3] "" Vector__XXX
 SG_ KeepingAssistEnableCmd : 2|2@1+ (1,0) [0|3] "" Vector__XXX
 SG_ CurSubRegion : 24|24@1+ (1,0) [0|255] "" Vector__XXX
 SG_ CurRegion : 8|16@1+ (1,0) [0|255] "" Vector__XXX
 SG_ LaneDepartureWarningEnableCmd : 0|2@1+ (1,0) [0|3] "" Vector__XXX

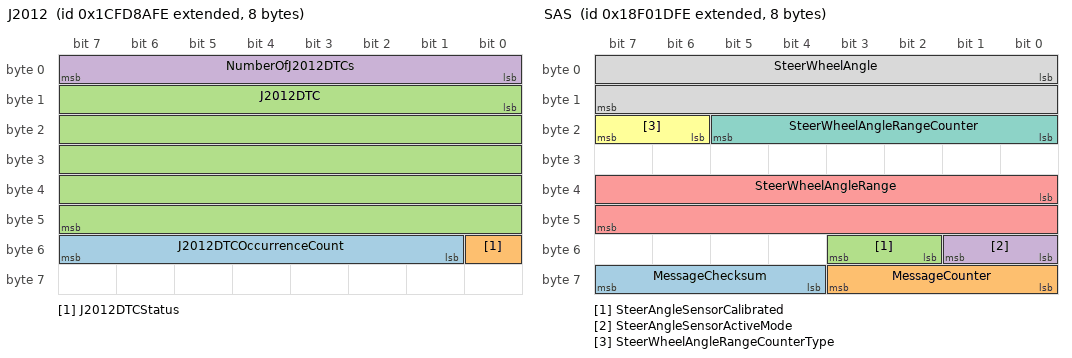
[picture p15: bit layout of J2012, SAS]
BO_ 2633861886 J2012: 8 Vector__XXX
 SG_ J2012DTCOccurrenceCount : 49|7@1+ (1,0) [0|126] "" Vector__XXX
 SG_ J2012DTCStatus : 48|1@1+ (1,0) [0|1] "" Vector__XXX
 SG_ J2012DTC : 8|40@1+ (1,0) [0|255] "" Vector__XXX
 SG_ NumberOfJ2012DTCs : 0|8@1+ (1,0) [0|250] "" Vector__XXX

BO_ 2565873150 SAS: 8 Vector__XXX
 SG_ MessageChecksum : 60|4@1+ (1,0) [0|15] "" Vector__XXX
 SG_ MessageCounter : 56|4@1+ (1,0) [0|15] "" Vector__XXX
 SG_ SteerAngleSensorCalibrated : 50|2@1+ (1,0) [0|3] "" Vector__XXX
 SG_ SteerAngleSensorActiveMode : 48|2@1+ (1,0) [0|3] "" Vector__XXX
 SG_ SteerWheelAngleRange : 32|16@1+ (0.0009765625,-31.374) [0|31.374] "rad" Vector__XXX
 SG_ SteerWheelAngleRangeCounterType : 22|2@1+ (1,0) [0|3] "" Vector__XXX
 SG_ SteerWheelAngleRangeCounter : 16|6@1+ (1,-32) [-32|29] "ranges" Vector__XXX
 SG_ SteerWheelAngle : 0|16@1+ (0.0009765625,-31.374) [-31.374|31.374] "rad" Vector__XXX

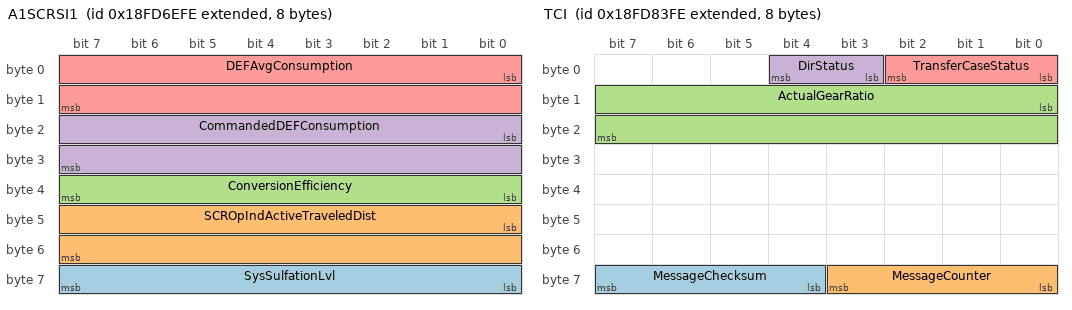
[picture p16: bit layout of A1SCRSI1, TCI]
BO_ 2566745854 A1SCRSI1: 8 Vector__XXX
 SG_ SysSulfationLvl : 56|8@1+ (1,0) [0|250] "%" Vector__XXX
 SG_ SCROpIndActiveTraveledDist : 40|16@1+ (1,0) [0|64255] "km" Vector__XXX
 SG_ ConversionEfficiency : 32|8@1+ (0.4,0) [0|100] "%" Vector__XXX
 SG_ CommandedDEFConsumption : 16|16@1+ (0.05,0) [0|3212.75] "l/h" Vector__XXX
 SG_ DEFAvgConsumption : 0|16@1+ (0.05,0) [0|3212.75] "l/h" Vector__XXX

BO_ 2566751230 TCI: 8 Vector__XXX
 SG_ MessageChecksum : 60|4@1+ (1,0) [0|15] "" Vector__XXX
 SG_ MessageCounter : 56|4@1+ (1,0) [0|15] "" Vector__XXX
 SG_ ActualGearRatio : 8|16@1+ (0.01,0) [0|642.55] "" Vector__XXX
 SG_ DirStatus : 3|2@1+ (1,0) [0|3] "" Vector__XXX
 SG_ TransferCaseStatus : 0|3@1+ (1,0) [0|7] "" Vector__XXX

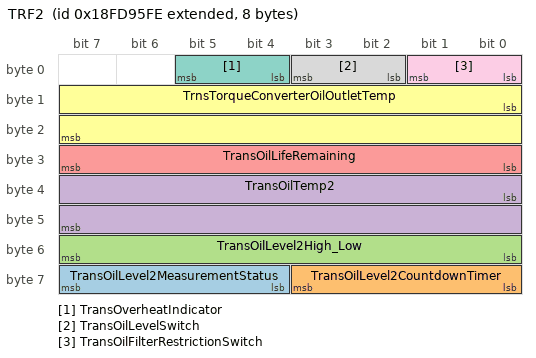
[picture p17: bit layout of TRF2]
BO_ 2566755838 TRF2: 8 Vector__XXX
 SG_ TransOilLevel2MeasurementStatus : 60|4@1+ (1,0) [0|15] "" Vector__XXX
 SG_ TransOilLevel2CountdownTimer : 56|4@1+ (1,0) [0|13] "" Vector__XXX
 SG_ TransOilLevel2High_Low : 48|8@1+ (0.5,-62.5) [-62.5|62.5] "l" Vector__XXX
 SG_ TransOilTemp2 : 32|16@1+ (0.03125,-273) [-273|1734.96875] "캜" Vector__XXX
 SG_ TransOilLifeRemaining : 24|8@1+ (0.4,0) [0|100] "%" Vector__XXX
 SG_ TrnsTorqueConverterOilOutletTemp : 8|16@1+ (0.03125,-273) [-273|1734.96875] "캜" Vector__XXX
 SG_ TransOverheatIndicator : 4|2@1+ (1,0) [0|3] "" Vector__XXX
 SG_ TransOilLevelSwitch : 2|2@1+ (1,0) [0|3] "" Vector__XXX
 SG_ TransOilFilterRestrictionSwitch : 0|2@1+ (1,0) [0|3] "" Vector__XXX

BO_ 2566752766 VDS2: 8 Vector__XXX
 SG_ VehicleRoll : 0|16@1+ (0.0078125,-200) [-90|90] "deg" Vector__XXX

BO_ 2633938942 LF: 10 Vector__XXX
 SG_ TotalEngCruiseTime : 48|32@1+ (0.05,0) [0|210554060.75] "h" Vector__XXX
 SG_ TotalDriveAverageLoadFactor : 40|8@1+ (0.4,0) [0|100] "%" Vector__XXX
 SG_ TripDriveAverageLoadFactor : 32|8@1+ (0.4,0) [0|100] "%" Vector__XXX
 SG_ TripAverageEngSpeed : 16|16@1+ (0.125,0) [0|8031.875] "rpm" Vector__XXX
 SG_ TripMaxEngSpeed : 0|16@1+ (0.125,0) [0|8031.875] "rpm" Vector__XXX

BO_ 2566799614 LD: 8 Vector__XXX
 SG_ ImplementRearWorkLight : 62|2@1+ (1,0) [0|3] "" Vector__XXX
 SG_ ImplementLeftFacingWorkLight : 60|2@1+ (1,0) [0|3] "" Vector__XXX
 SG_ ImplementRightForwardWorkLight : 58|2@1+ (1,0) [0|3] "" Vector__XXX
 SG_ ImplementLeftForwardWorkLight : 54|2@1+ (1,0) [0|3] "" Vector__XXX
 SG_ ImplementRightFacingWorkLight : 52|2@1+ (1,0) [0|3] "" Vector__XXX
 SG_ ImplementOEMOption1Light : 50|2@1+ (1,0) [0|3] "" Vector__XXX
 SG_ ImplementOEMOption2Light : 48|2@1+ (1,0) [0|3] "" Vector__XXX
 SG_ TrctorFrontHighMountedWorkLights : 46|2@1+ (1,0) [0|3] "" Vector__XXX
 SG_ TractorFrontLowMountedWorkLights : 44|2@1+ (1,0) [0|3] "" Vector__XXX
 SG_ TractorSideHighMountedWorkLights : 42|2@1+ (1,0) [0|3] "" Vector__XXX
 SG_ TractorSideLowMountedWorkLights : 40|2@1+ (1,0) [0|3] "" Vector__XXX
 SG_ TractorRearHighMountedWorkLights : 38|2@1+ (1,0) [0|3] "" Vector__XXX
 SG_ TractorRearLowMountedWorkLights : 36|2@1+ (1,0) [0|3] "" Vector__XXX
 SG_ TrctorUndersideMountedWorkLights : 34|2@1+ (1,0) [0|3] "" Vector__XXX
 SG_ RearFogLights : 32|2@1+ (1,0) [0|3] "" Vector__XXX
 SG_ TractorMarkerLight : 30|2@1+ (1,0) [0|3] "" Vector__XXX
 SG_ ImplementMarkerLight : 28|2@1+ (1,0) [0|3] "" Vector__XXX
 SG_ TractorClearanceLight : 26|2@1+ (1,0) [0|3] "" Vector__XXX
 SG_ ImplementClearanceLight : 24|2@1+ (1,0) [0|3] "" Vector__XXX
 SG_ LeftStopLight : 22|2@1+ (1,0) [0|3] "" Vector__XXX
 SG_ RightStopLight : 20|2@1+ (1,0) [0|3] "" Vector__XXX
 SG_ CenterStopLight : 18|2@1+ (1,0) [0|3] "" Vector__XXX
 SG_ BackUpLightAndAlarmHorn : 16|2@1+ (1,0) [0|3] "" Vector__XXX
 SG_ LeftTurnSignalLights : 14|2@1+ (1,0) [0|3] "" Vector__XXX
 SG_ RightTurnSignalLights : 12|2@1+ (1,0) [0|3] "" Vector__XXX
 SG_ RotatingBeaconLight : 10|2@1+ (1,0) [0|3] "" Vector__XXX
 SG_ TractorFrontFogLights : 8|2@1+ (1,0) [0|3] "" Vector__XXX
 SG_ HighBeamHeadLightData : 6|2@1+ (1,0) [0|3] "" Vector__XXX
 SG_ LowBeamHeadLightData : 4|2@1+ (1,0) [0|3] "" Vector__XXX
 SG_ AltBeamHeadLightData : 2|2@1+ (1,0) [0|3] "" Vector__XXX
 SG_ RunningLight : 0|2@1+ (1,0) [0|3] "" Vector__XXX

BO_ 2365473278 LCMD: 8 Vector__XXX
 SG_ ImplementRearWorkLightCmd : 62|2@1+ (1,0) [0|3] "" Vector__XXX
 SG_ ImplementLeftFacingWorkLightCmd : 60|2@1+ (1,0) [0|3] "" Vector__XXX
 SG_ ImplmentRightForwardWorkLightCmd : 58|2@1+ (1,0) [0|3] "" Vector__XXX
 SG_ LightingDataRqCmd : 56|2@1+ (1,0) [0|3] "" Vector__XXX
 SG_ ImplementLeftForwardWorkLightCmd : 54|2@1+ (1,0) [0|3] "" Vector__XXX
 SG_ ImplementRightFacingWorkLightCmd : 52|2@1+ (1,0) [0|3] "" Vector__XXX
 SG_ ImplementOEMOption1LightCmd : 50|2@1+ (1,0) [0|3] "" Vector__XXX
 SG_ ImplementOEMOption2LightCmd : 48|2@1+ (1,0) [0|3] "" Vector__XXX
 SG_ TrctrFrntHghMountedWorkLightsCmd : 46|2@1+ (1,0) [0|3] "" Vector__XXX
 SG_ TrctrFrntLowMountedWorkLightsCmd : 44|2@1+ (1,0) [0|3] "" Vector__XXX
 SG_ TrctrSdeHighMountedWorkLightsCmd : 42|2@1+ (1,0) [0|3] "" Vector__XXX
 SG_ TrctrSideLowMountedWorkLightsCmd : 40|2@1+ (1,0) [0|3] "" Vector__XXX
 SG_ TrctrRarHighMountedWorkLightsCmd : 38|2@1+ (1,0) [0|3] "" Vector__XXX
 SG_ TrctrRearLowMountedWorkLightsCmd : 36|2@1+ (1,0) [0|3] "" Vector__XXX
 SG_ TrctrUndrsdeMountedWorkLightsCmd : 34|2@1+ (1,0) [0|3] "" Vector__XXX
 SG_ RearFogLightCmd : 32|2@1+ (1,0) [0|3] "" Vector__XXX
 SG_ TractorMarkerLightCmd : 30|2@1+ (1,0) [0|3] "" Vector__XXX
 SG_ ImplementMarkerLightCmd : 28|2@1+ (1,0) [0|3] "" Vector__XXX
 SG_ TractorClearanceLightCmd : 26|2@1+ (1,0) [0|3] "" Vector__XXX
 SG_ ImplementClearanceLightCmd : 24|2@1+ (1,0) [0|3] "" Vector__XXX
 SG_ LeftStopLightCmd : 22|2@1+ (1,0) [0|3] "" Vector__XXX
 SG_ RightStopLightCmd : 20|2@1+ (1,0) [0|3] "" Vector__XXX
 SG_ CenterStopLightCmd : 18|2@1+ (1,0) [0|3] "" Vector__XXX
 SG_ BackUpLightAndAlarmHornCmd : 16|2@1+ (1,0) [0|3] "" Vector__XXX
 SG_ LeftTurnSignalLightsCmd : 14|2@1+ (1,0) [0|3] "" Vector__XXX
 SG_ RightTurnSignalLightsCmd : 12|2@1+ (1,0) [0|3] "" Vector__XXX
 SG_ RotatingBeaconLightCmd : 10|2@1+ (1,0) [0|3] "" Vector__XXX
 SG_ TractorFrontFogLightsCmd : 8|2@1+ (1,0) [0|3] "" Vector__XXX
 SG_ HighBeamHeadLightCmd : 6|2@1+ (1,0) [0|3] "" Vector__XXX
 SG_ LowBeamHeadLightCmd : 4|2@1+ (1,0) [0|3] "" Vector__XXX
 SG_ AltBeamHeadLightCmd : 2|2@1+ (1,0) [0|3] "" Vector__XXX
 SG_ RunningLightCmd : 0|2@1+ (1,0) [0|3] "" Vector__XXX

CM_ BO_ 2365402110 "Extended Joystick Message 6
Used to transfer information about the measured status of three additional axes of a joystick and switches of the joystick grip or handle.  The joystick axial motion information is available in the Basic Joystick ...";
CM_ SG_ 2365402110 Joystick6Button13PressedStatus "Reports when the joystick button has been pressed.

00 Button not pressed
01 Button pressed
10 Error Indicator
11 Not Available";
CM_ SG_ 2365402110 Joystick6Button14PressedStatus "Reports when the joystick button has been pressed.

00 Button not pressed
01 Button pressed
10 Error Indicator
11 Not Available";
CM_ SG_ 2365402110 Joystick6Button15PressedStatus "Reports when the joystick button has been pressed.

00 Button not pressed
01 Button pressed
10 Error Indicator
11 Not Available";
CM_ SG_ 2365402110 Joystick6Button16PressedStatus "Reports when the joystick button has been pressed.

00 Button not pressed
01 Button pressed
10 Error Indicator
11 Not Available";
CM_ SG_ 2365402110 Jystick6GripXAxisDetentPosStatus "Reports when the current joystick grip position is in the detent position for that axis of travel.

00 Not in the Detent Position
01 In the Detent Position
10 Error Indicator
11 Not Available";
CM_ SG_ 2365402110 Jystick6GripYAxisDetentPosStatus "Reports when the current joystick grip position is in the detent position for that axis of travel.

00 Not in the Detent Position
01 In the Detent Position
10 Error Indicator
11 Not Available";
CM_ SG_ 2365402110 Jystick6ThetaAxisDetentPosStatus "Reports when the current joystick position is in the detent position for that axis of travel.

00 Not in the Detent Position
01 In the Detent Position
10 Error Indicator
11 Not Available";
CM_ SG_ 2365402110 Joystick6ThetaAxisPos "The position of the joystick in the relative motion of travel from the neutral position.  Position value of 0 is Neutral and position value 1000 (100%) is the end of linear zone.  Value of 1022 indicates an error has occurred.";
CM_ SG_ 2365402110 Jystck6ThtAxsClckwsPstvPosStatus "Reports when the current joystick position is on the positive travel side (forward, right, clockwise, up) relative to the neutral position for that axis of travel.
00 Not on Positive side of Neutral
01 On positive side of Neutral
10 Error ...";
CM_ SG_ 2365402110 Jystck6ThtAxsCntrClckwsNgtvPsStt "Reports when the current joystick position is on the negative travel side (back, left, counterclockwise, down) relative to the neutral position for that axis of travel.
00 Not on negative side of Neutral
01 On negative side of Neutral
10 Error ...";
CM_ SG_ 2365402110 Jystck6ThetaAxisNeutralPosStatus "Reports when the current joystick position is in the neutral position for that axis of travel.  The neutral position measurement must be determined from some mechanism other than the axis position measurement device.
00 Not in Neutral Position
01 ...";
CM_ SG_ 2365402110 Joystick6GripYAxisPos "The position of the joystick grip in the relative motion of travel from the neutral position.  Position value of 0 is Neutral and position value 1000 (100%) is the end of linear zone.  Value of 1022 indicates an error has occurred.";
CM_ SG_ 2365402110 Jystck6GrpYAxsLvrFrwrdPstvPsStts "Reports when the current joystick grip position is on the positive travel side (forward, right, clockwise, up) relative to the neutral position for that axis of travel.
00 Not on Positive side of Neutral
01 On positive side of Neutral
10 Error ...";
CM_ SG_ 2365402110 Jystck6GrpYAxsLvrBckNgtvPsStatus "Reports when the current joystick grip position is on the negative travel side (back, left, counterclockwise, down) relative to the neutral position for that axis of travel.
00 Not on negative side of Neutral
01 On negative side of Neutral
10 ...";
CM_ SG_ 2365402110 Jystck6GripYAxisNeutralPosStatus "Reports when the current joystick grip position is in the neutral position for that axis of travel.  The neutral position measurement must be determined from some mechanism other than the axis position measurement device.
00 Not in Neutral Position
 ...";
CM_ SG_ 2365402110 Joystick6GripXAxisPos "The position of the joystick grip in the relative motion of travel from the neutral position.  Position value of 0 is Neutral and position value 1000 (100%) is the end of linear zone.  Value of 1022 indicates an error has occurred.";
CM_ SG_ 2365402110 Jystck6GrpXAxsLvrRghtPstvPsSttus "Reports when the current joystick grip position is on the positive travel side (forward, right, clockwise, up) relative to the neutral position for that axis of travel.
00 Not on Positive side of Neutral
01 On positive side of Neutral
10 Error ...";
CM_ SG_ 2365402110 Jystck6GrpXAxsLvrLftNgtvPsStatus "Reports when the current joystick grip position is on the negative travel side (back, left, counterclockwise, down) relative to the neutral position for that axis of travel.
00 Not on negative side of Neutral
01 On negative side of Neutral
10 ...";
CM_ SG_ 2365402110 Jystck6GripXAxisNeutralPosStatus "Reports when the current joystick grip position is in the neutral position for that axis of travel.  The neutral position measurement must be determined from some mechanism other than the axis position measurement device.
00 Not in Neutral Position
 ...";
CM_ BO_ 2365402622 "Extended Joystick Message 5
Used to transfer information about the measured status of three additional axes of a joystick and switches of the joystick grip or handle.  The joystick axial motion information is available in the Basic Joystick ...";
CM_ SG_ 2365402622 Joystick5Button13PressedStatus "Reports when the joystick button has been pressed.

00 Button not pressed
01 Button pressed
10 Error Indicator
11 Not Available";
CM_ SG_ 2365402622 Joystick5Button14PressedStatus "Reports when the joystick button has been pressed.

00 Button not pressed
01 Button pressed
10 Error Indicator
11 Not Available";
CM_ SG_ 2365402622 Joystick5Button15PressedStatus "Reports when the joystick button has been pressed.

00 Button not pressed
01 Button pressed
10 Error Indicator
11 Not Available";
CM_ SG_ 2365402622 Joystick5Button16PressedStatus "Reports when the joystick button has been pressed.

00 Button not pressed
01 Button pressed
10 Error Indicator
11 Not Available";
CM_ SG_ 2365402622 Jystick5GripXAxisDetentPosStatus "Reports when the current joystick grip position is in the detent position for that axis of travel.

00 Not in the Detent Position
01 In the Detent Position
10 Error Indicator
11 Not Available";
CM_ SG_ 2365402622 Jystick5GripYAxisDetentPosStatus "Reports when the current joystick grip position is in the detent position for that axis of travel.

00 Not in the Detent Position
01 In the Detent Position
10 Error Indicator
11 Not Available";
CM_ SG_ 2365402622 Jystick5ThetaAxisDetentPosStatus "Reports when the current joystick position is in the detent position for that axis of travel.

00 Not in the Detent Position
01 In the Detent Position
10 Error Indicator
11 Not Available";
CM_ SG_ 2365402622 Joystick5ThetaAxisPos "The position of the joystick in the relative motion of travel from the neutral position.  Position value of 0 is Neutral and position value 1000 (100%) is the end of linear zone.  Value of 1022 indicates an error has occurred.";
CM_ SG_ 2365402622 Jystck5ThtAxsClckwsPstvPosStatus "Reports when the current joystick position is on the positive travel side (forward, right, clockwise, up) relative to the neutral position for that axis of travel.
00 Not on Positive side of Neutral
01 On positive side of Neutral
10 Error ...";
CM_ SG_ 2365402622 Jystck5ThtAxsCntrClckwsNgtvPsStt "Reports when the current joystick position is on the negative travel side (back, left, counterclockwise, down) relative to the neutral position for that axis of travel.
00 Not on negative side of Neutral
01 On negative side of Neutral
10 Error ...";
CM_ SG_ 2365402622 Jystck5ThetaAxisNeutralPosStatus "Reports when the current joystick position is in the neutral position for that axis of travel.  The neutral position measurement must be determined from some mechanism other than the axis position measurement device.
00 Not in Neutral Position
01 ...";
CM_ SG_ 2365402622 Joystick5GripYAxisPos "The position of the joystick grip in the relative motion of travel from the neutral position.  Position value of 0 is Neutral and position value 1000 (100%) is the end of linear zone.  Value of 1022 indicates an error has occurred.";
CM_ SG_ 2365402622 Jystck5GrpYAxsLvrFrwrdPstvPsStts "Reports when the current joystick grip position is on the positive travel side (forward, right, clockwise, up) relative to the neutral position for that axis of travel.
00 Not on Positive side of Neutral
01 On positive side of Neutral
10 Error ...";
CM_ SG_ 2365402622 Jystck5GrpYAxsLvrBckNgtvPsStatus "Reports when the current joystick grip position is on the negative travel side (back, left, counterclockwise, down) relative to the neutral position for that axis of travel.
00 Not on negative side of Neutral
01 On negative side of Neutral
10 ...";
CM_ SG_ 2365402622 Jystck5GripYAxisNeutralPosStatus "Reports when the current joystick grip position is in the neutral position for that axis of travel.  The neutral position measurement must be determined from some mechanism other than the axis position measurement device.
00 Not in Neutral Position
 ...";
CM_ SG_ 2365402622 Joystick5GripXAxisPos "The position of the joystick grip in the relative motion of travel from the neutral position.  Position value of 0 is Neutral and position value 1000 (100%) is the end of linear zone.  Value of 1022 indicates an error has occurred.";
CM_ SG_ 2365402622 Jystck5GrpXAxsLvrRghtPstvPsSttus "Reports when the current joystick grip position is on the positive travel side (forward, right, clockwise, up) relative to the neutral position for that axis of travel.
00 Not on Positive side of Neutral
01 On positive side of Neutral
10 Error ...";
CM_ SG_ 2365402622 Jystck5GrpXAxsLvrLftNgtvPsStatus "Reports when the current joystick grip position is on the negative travel side (back, left, counterclockwise, down) relative to the neutral position for that axis of travel.
00 Not on negative side of Neutral
01 On negative side of Neutral
10 ...";
CM_ SG_ 2365402622 Jystck5GripXAxisNeutralPosStatus "Reports when the current joystick grip position is in the neutral position for that axis of travel.  The neutral position measurement must be determined from some mechanism other than the axis position measurement device.
00 Not in Neutral Position
 ...";
CM_ BO_ 2365403134 "Extended Joystick Message 4
Used to transfer information about the measured status of three additional axes of a joystick and switches of the joystick grip or handle.  The joystick axial motion information is available in the Basic Joystick ...";
CM_ SG_ 2365403134 Joystick4Button13PressedStatus "Reports when the joystick button has been pressed.

00 Button not pressed
01 Button pressed
10 Error Indicator
11 Not Available";
CM_ SG_ 2365403134 Joystick4Button14PressedStatus "Reports when the joystick button has been pressed.

00 Button not pressed
01 Button pressed
10 Error Indicator
11 Not Available";
CM_ SG_ 2365403134 Joystick4Button15PressedStatus "Reports when the joystick button has been pressed.

00 Button not pressed
01 Button pressed
10 Error Indicator
11 Not Available";
CM_ SG_ 2365403134 Joystick4Button16PressedStatus "Reports when the joystick button has been pressed.

00 Button not pressed
01 Button pressed
10 Error Indicator
11 Not Available";
CM_ SG_ 2365403134 Jystick4GripXAxisDetentPosStatus "Reports when the current joystick grip position is in the detent position for that axis of travel.

00 Not in the Detent Position
01 In the Detent Position
10 Error Indicator
11 Not Available";
CM_ SG_ 2365403134 Jystick4GripYAxisDetentPosStatus "Reports when the current joystick grip position is in the detent position for that axis of travel.

00 Not in the Detent Position
01 In the Detent Position
10 Error Indicator
11 Not Available";
CM_ SG_ 2365403134 Jystick4ThetaAxisDetentPosStatus "Reports when the current joystick position is in the detent position for that axis of travel.

00 Not in the Detent Position
01 In the Detent Position
10 Error Indicator
11 Not Available";
CM_ SG_ 2365403134 Joystick4ThetaAxisPos "The position of the joystick in the relative motion of travel from the neutral position.  Position value of 0 is Neutral and position value 1000 (100%) is the end of linear zone.  Value of 1022 indicates an error has occurred.";
CM_ SG_ 2365403134 Jystck4ThtAxsClckwsPstvPosStatus "Reports when the current joystick position is on the positive travel side (forward, right, clockwise, up) relative to the neutral position for that axis of travel.
00 Not on Positive side of Neutral
01 On positive side of Neutral
10 Error ...";
CM_ SG_ 2365403134 Jystck4ThtAxsCntrClckwsNgtvPsStt "Reports when the current joystick position is on the negative travel side (back, left, counterclockwise, down) relative to the neutral position for that axis of travel.
00 Not on negative side of Neutral
01 On negative side of Neutral
10 Error ...";
CM_ SG_ 2365403134 Jystck4ThetaAxisNeutralPosStatus "Reports when the current joystick position is in the neutral position for that axis of travel.  The neutral position measurement must be determined from some mechanism other than the axis position measurement device.
00 Not in Neutral Position
01 ...";
CM_ SG_ 2365403134 Joystick4GripYAxisPos "The position of the joystick grip in the relative motion of travel from the neutral position.  Position value of 0 is Neutral and position value 1000 (100%) is the end of linear zone.  Value of 1022 indicates an error has occurred.";
CM_ SG_ 2365403134 Jystck4GrpYAxsLvrFrwrdPstvPsStts "Reports when the current joystick grip position is on the positive travel side (forward, right, clockwise, up) relative to the neutral position for that axis of travel.
00 Not on Positive side of Neutral
01 On positive side of Neutral
10 Error ...";
CM_ SG_ 2365403134 Jystck4GrpYAxsLvrBckNgtvPsStatus "Reports when the current joystick grip position is on the negative travel side (back, left, counterclockwise, down) relative to the neutral position for that axis of travel.
00 Not on negative side of Neutral
01 On negative side of Neutral
10 ...";
CM_ SG_ 2365403134 Jystck4GripYAxisNeutralPosStatus "Reports when the current joystick grip position is in the neutral position for that axis of travel.  The neutral position measurement must be determined from some mechanism other than the axis position measurement device.
00 Not in Neutral Position
 ...";
CM_ SG_ 2365403134 Joystick4GripXAxisPos "The position of the joystick grip in the relative motion of travel from the neutral position.  Position value of 0 is Neutral and position value 1000 (100%) is the end of linear zone.  Value of 1022 indicates an error has occurred.";
CM_ SG_ 2365403134 Jystck4GrpXAxsLvrRghtPstvPsSttus "Reports when the current joystick grip position is on the positive travel side (forward, right, clockwise, up) relative to the neutral position for that axis of travel.
00 Not on Positive side of Neutral
01 On positive side of Neutral
10 Error ...";
CM_ SG_ 2365403134 Jystck4GrpXAxsLvrLftNgtvPsStatus "Reports when the current joystick grip position is on the negative travel side (back, left, counterclockwise, down) relative to the neutral position for that axis of travel.
00 Not on negative side of Neutral
01 On negative side of Neutral
10 ...";
CM_ SG_ 2365403134 Jystck4GripXAxisNeutralPosStatus "Reports when the current joystick grip position is in the neutral position for that axis of travel.  The neutral position measurement must be determined from some mechanism other than the axis position measurement device.
00 Not in Neutral Position
 ...";
CM_ BO_ 2365400062 "Extended Joystick Message 10
Used to transfer information about the measured status of three additional axes of a joystick and switches of the joystick grip or handle.  The joystick axial motion information is available in the Basic Joystick ...";
CM_ SG_ 2365400062 Joystick10Button13PressedStatus "Reports when the joystick button has been pressed.

00 Button not pressed
01 Button pressed
10 Error Indicator
11 Not Available";
CM_ SG_ 2365400062 Joystick10Button14PressedStatus "Reports when the joystick button has been pressed.

00 Button not pressed
01 Button pressed
10 Error Indicator
11 Not Available";
CM_ SG_ 2365400062 Joystick10Button15PressedStatus "Reports when the joystick button has been pressed.

00 Button not pressed
01 Button pressed
10 Error Indicator
11 Not Available";
CM_ SG_ 2365400062 Joystick10Button16PressedStatus "Reports when the joystick button has been pressed.

00 Button not pressed
01 Button pressed
10 Error Indicator
11 Not Available";
CM_ SG_ 2365400062 Jystck10GripXAxisDetentPosStatus "Reports when the current joystick grip position is in the detent position for that axis of travel.

00 Not in the Detent Position
01 In the Detent Position
10 Error Indicator
11 Not Available";
CM_ SG_ 2365400062 Jystck10GripYAxisDetentPosStatus "Reports when the current joystick grip position is in the detent position for that axis of travel.

00 Not in the Detent Position
01 In the Detent Position
10 Error Indicator
11 Not Available";
CM_ SG_ 2365400062 Jystck10ThetaAxisDetentPosStatus "Reports when the current joystick position is in the detent position for that axis of travel.

00 Not in the Detent Position
01 In the Detent Position
10 Error Indicator
11 Not Available";
CM_ SG_ 2365400062 Joystick10ThetaAxisPos "The position of the joystick in the relative motion of travel from the neutral position.  Position value of 0 is Neutral and position value 1000 (100%) is the end of linear zone.  Value of 1022 indicates an error has occurred.";
CM_ SG_ 2365400062 Jystck10ThtAxsClckwsPstvPsStatus "Reports when the current joystick position is on the positive travel side (forward, right, clockwise, up) relative to the neutral position for that axis of travel.
00 Not on Positive side of Neutral
01 On positive side of Neutral
10 Error ...";
CM_ SG_ 2365400062 Jystck10ThtAxsCntrClckwsNgtvPsSt "Reports when the current joystick position is on the negative travel side (back, left, counterclockwise, down) relative to the neutral position for that axis of travel.
00 Not on negative side of Neutral
01 On negative side of Neutral
10 Error ...";
CM_ SG_ 2365400062 Jystck10ThtaAxisNeutralPosStatus "Reports when the current joystick position is in the neutral position for that axis of travel.  The neutral position measurement must be determined from some mechanism other than the axis position measurement device.
00 Not in Neutral Position
01 ...";
CM_ SG_ 2365400062 Joystick10GripYAxisPos "The position of the joystick grip in the relative motion of travel from the neutral position.  Position value of 0 is Neutral and position value 1000 (100%) is the end of linear zone.  Value of 1022 indicates an error has occurred.";
CM_ SG_ 2365400062 Jystck10GrpYAxsLvrFrwrdPstvPsStt "Reports when the current joystick grip position is on the positive travel side (forward, right, clockwise, up) relative to the neutral position for that axis of travel.
00 Not on Positive side of Neutral
01 On positive side of Neutral
10 Error ...";
CM_ SG_ 2365400062 Jystck10GrpYAxsLvrBckNgtvPsSttus "Reports when the current joystick grip position is on the negative travel side (back, left, counterclockwise, down) relative to the neutral position for that axis of travel.
00 Not on negative side of Neutral
01 On negative side of Neutral
10 ...";
CM_ SG_ 2365400062 Jystck10GrpYAxisNeutralPosStatus "Reports when the current joystick grip position is in the neutral position for that axis of travel.  The neutral position measurement must be determined from some mechanism other than the axis position measurement device.
00 Not in Neutral Position
 ...";
CM_ SG_ 2365400062 Joystick10GripXAxisPos "The position of the joystick grip in the relative motion of travel from the neutral position.  Position value of 0 is Neutral and position value 1000 (100%) is the end of linear zone.  Value of 1022 indicates an error has occurred.";
CM_ SG_ 2365400062 Jystck10GrpXAxsLvrRghtPstvPsStts "Reports when the current joystick grip position is on the positive travel side (forward, right, clockwise, up) relative to the neutral position for that axis of travel.
00 Not on Positive side of Neutral
01 On positive side of Neutral
10 Error ...";
CM_ SG_ 2365400062 Jystck10GrpXAxsLvrLftNgtvPsSttus "Reports when the current joystick grip position is on the negative travel side (back, left, counterclockwise, down) relative to the neutral position for that axis of travel.
00 Not on negative side of Neutral
01 On negative side of Neutral
10 ...";
CM_ SG_ 2365400062 Jystck10GrpXAxisNeutralPosStatus "Reports when the current joystick grip position is in the neutral position for that axis of travel.  The neutral position measurement must be determined from some mechanism other than the axis position measurement device.
00 Not in Neutral Position
 ...";
CM_ BO_ 2566713598 "Engine Fuel/Lube 
Systems 2
Contains information on the engine fuel and lube system";
CM_ SG_ 2566713598 FuelPumpInOilPress "Oil pressure at the intake of the engine fuel pump.";
CM_ SG_ 2566713598 FuelTankTransferPumpPress "Gage pressure of the fuel in the system as delivered by the transfer pump.";
CM_ SG_ 2566713598 FuelTankTransferPump "Operating state of the fuel tank transfer pump. The fuel tank transfer pump transfers fuel from the secondary fuel tank to the primary fuel tank.

00 = Off
01 = On
10 = Error
11 = Not available";
CM_ SG_ 2566713598 EngFuelFilterDegradation "The estimated percentage relative to the useful life of the engine fuel filter on the suction side which is located betwee the fuel tank and the fuel supply pump.
Note:  This is not a calculation of the physical restriction of the filter. 0% is ...";
CM_ SG_ 2566713598 EngFuelFilterIntakeAbsPress "Absolute pressure of fuel at the intake of the fuel filter (suction side) located between the fuel tank and the fuel supply pump.  See Figures SPN16_A & SPN16_B.";
CM_ BO_ 2499604478 "Engine Fluid Level/Pressure 11
Engine related parameters.";
CM_ SG_ 2499604478 EngFuelDeliveryPress "Gage pressure of fuel in system as delivered from supply pump to the injection pump. See SPN 94 for alternate resolution.

See also SPN 5578 for Engine Fuel Delivery Absolute Pressure.";
CM_ SG_ 2499604478 EngOilPress "Gage pressure of oil in engine lubrication system as provided by oil pump. See SPN 100 for alternate resolution.";
CM_ SG_ 2499604478 EngExhstGsRcrcltn1OutletAbsPress "EGR outlet absolute pressure is measured after the EGR 1 valve. See SPN 5019 for 1 byte resolution.";
CM_ SG_ 2499604478 EngExhstGsRcrcltn1IntakeAbsPress "EGR intake absolute pressure measured before the EGR 1 valve.";
CM_ BO_ 2499608830 "Engine Fluid Level/Pressure 10
Engine related parameters";
CM_ SG_ 2499608830 EngCoolantPress2 "Gage pressure of liquid found in the engine coolant system - second instance.

See SPN 7313 for alternate range and resolution.";
CM_ SG_ 2499608830 EngExhstGsRcrcltn2IntakeAbsPress "EGR intake absolute pressure measured before the EGR 2 valve.";
CM_ SG_ 2499608830 EngExhstGsRcrcltn2OutletAbsPress "Absolute Pressure immediately after the EGR2 valve";
CM_ SG_ 2499608830 EngExhstGsRcrclation2IntakePress "EGR2 intake gauge pressure is measured after EGR2 cooler and before EGR2 valve";
CM_ SG_ 2499608830 EngExhstGsRcirculation2DiffPress "Differential Pressure across the Exhaust Gas Recirculation 2 (EGR2) system.";
CM_ BO_ 2432499198 "Electronic Engine Controller 9
Engine related parameters";
CM_ SG_ 2432499198 CmmndedEngFuelInjectionCtrlPress "Provides the commanded set point value for the engine fuel injection control pressure.";
CM_ SG_ 2432499198 CommandedEngFuelRailPress "Provides the commanded set point value for the engine fuel rail gage pressure";
CM_ SG_ 2432499198 EngExhstGsRcirculation2Valve2Pos "The position of the second exhaust gas recirculation valve of EGR 2 expressed as a percentage of full travel. 0% means the valve is closed and no exhaust gas is flowing into the air stream. 100% means the valve is fully opened.";
CM_ SG_ 2432499198 EngExhstGsRecirculation2ValvePos "Position of EGR2 valve expressed as a percentage of full travel. 0% means the valve is closed and no exhaust gas is flowing into the air stream. 100% means the valve is fully opened.";
CM_ BO_ 2633825022 "Electronic Engine Controller 11
Engine related parameters";
CM_ SG_ 2633825022 EngExhstGsRcrcltn2Valve2PosError "The position error of the Exhaust Gas Recirculation 2 valve 2, determined as the actual position (SPN 5265) minus the commanded position (SPN 5263).";
CM_ SG_ 2633825022 EngExhstGsRcrcltn2Valve1PosError "The position error of the Exhaust Gas Recirculation 2 valve, determined as the actual position (SPN 5264) minus the commanded position (SPN 5262).";
CM_ SG_ 2633825022 EngExhstGsRcrculation2Valve2Ctrl "Desired percentage of maximum Exhaust Gas Recirculation 2 (EGR2) valve 2 opening. 0% means the valve is closed. 100% means maximum opening (full gas flow).";
CM_ SG_ 2633825022 EngExhstGsRcirculation2ValveCtrl "Desired percentage of maximum Exhaust Gas Recirculation 2 (EGR2) valve opening. 0% means the valve is closed. 100% means maximum opening (full gas flow).";
CM_ BO_ 2633826046 "Electronic Engine Controller 10
Engine related parameters";
CM_ SG_ 2633826046 EGR2CoolerInPress "Exhaust gas recirculation 2 (EGR2) gage pressure is measured at the EGR2 cooler intake.";
CM_ SG_ 2633826046 EGR2CoolerBypassActuatorPos "EGR2 Cooler Bypass Actuator position, where 0% = Fully Closed (no gas flowing through the bypass), and 100% = Fully Open..";
CM_ SG_ 2633826046 EngExhstGsRcrcltn2ClerEfficiency "Exhaust Gas Recirculation 2 cooler efficiency is an indication of the cooler뭩 ability to reduce the temperature of the exhaust gas that is being recirculated back to the intake. 0% = no reduction in temperature, 100% = maximum cooling. The EGR 2 ...";
CM_ SG_ 2633826046 EngExhstGsRcrcltn2ClrIntkGsAbsPr "Exhaust Gas Recirculation 2 gas absolute pressure is measured at EGR2 cooler intake. See SPN 5253 for EGR2 pressure measured at the EGR2 cooler outlet before the valve.";
CM_ SG_ 2633826046 EngExhstGsRcrcltn2ClerIntakeTemp "Exhaust Gas Recirculation 2 (EGR2) Temperature measured at EGR2 cooler intake. See SPN 5255 for Engine EGR2 temperature.";
CM_ BO_ 2566711294 "Engine Configuration 3
The EC3 message contains a static engine friction torque map consisting of torque points that correspond to the speed points in the EC1 message.  A net brake torque map for the engine can be calculated by subtracting the ...";
CM_ SG_ 2566711294 EngFrictionPercentTorquePoint7 "The static portion of the friction torque at speed point 7 (SPN 533) of the engine torque map in the engine configuration message.  This parameter does not include Estimated Pumping - Percent Torque (SPN 5398) and is expected to change with ...";
CM_ SG_ 2566711294 EngFrictionPercentTorquePoint6 "For engine configuration map modes 1 and 2, this is the static portion of the friction torque at speed point 6 (SPN 532) of the engine torque map.  For engine configuration map mode 3, this parameter is the static portion of the friction torque at ...";
CM_ SG_ 2566711294 EngFrictionPercentTorquePoint5 "The static portion of the friction torque at speed point 5 (SPN 531) of the engine torque map in the engine configuration message.  This parameter does not include Estimated Pumping - Percent Torque (SPN 5398) and is expected to change with ...";
CM_ SG_ 2566711294 EngFrictionPercentTorquePoint4 "The static portion of the friction torque at speed point 4 (SPN 530) of the engine torque map in the engine configuration message.  This parameter does not include Estimated Pumping - Percent Torque (SPN 5398) and is expected to change with ...";
CM_ SG_ 2566711294 EngFrictionPercentTorquePoint3 "The static portion of the friction torque at speed point 3 (SPN 529) of the engine torque map in the engine configuration message.  This parameter does not include Estimated Pumping - Percent Torque (SPN 5398) and is expected to change with ...";
CM_ SG_ 2566711294 EngFrictionPercentTorquePoint2 "The static portion of the friction torque at speed point 2 (SPN 528) of the engine torque map in the engine configuration message.  This parameter does not include Estimated Pumping - Percent Torque (SPN 5398) and is expected to change with ...";
CM_ SG_ 2566711294 EngFrctnPrcentTorqueAtIdlePoint1 "The static portion of the friction torque at speed point 1 (SPN 188) of the engine torque map in the engine configuration message.  This parameter does not include Estimated Pumping - Percent Torque (SPN 5398) and is expected to change with ...";
CM_ BO_ 2566749438 "Diesel Particulate Filter Control 1
This PGN contains information about the diesel particulate filter regeneration control.
If there are aftertreatment systems on two banks, this PGN represents the composite information from both banks.
NOTE ...";
CM_ SG_ 2566749438 ActiveRegenAvailabilityStatus "Indicates that diesel particulate filter active regeneration is available for initiation through Aftertreatment Regeneration Force Switch (SPN 3696).

00 - Not ready for initiation
01 - Ready for initiation
10 - Reserved
11 - Not Available";
CM_ SG_ 2566749438 DslPrtcltFltrActvRgnrtnInhbt5629 "Indicates the state of diesel particulate filter active regeneration inhibition due to low exhaust pressure.
00 not inhibited
01 inhibited
10 reserved for SAE assignment
11 not available
This SPN indicates the reason for the diesel particulate ...";
CM_ SG_ 2566749438 AFT1DPFCondNotMetForActiveRegen "Indicates that diesel particulate filter 1 is not able to begin or continue an active regenerate event at the current engine operating conditions.
00 active DPF regeneration not inhibited
01 active DPF regeneration inhibited
10 reserved for SAE ...";
CM_ SG_ 2566749438 HydrocarbonDoserPurgingEnable "Purging enable of the Hydrocarbon Doser (HCD).

00 Purging not enabled
01 Purging enabled - less urgent
10 Purging enabled - urgent
11 Not available";
CM_ SG_ 2566749438 DslPrtcltFltrActvRgnrtnFrcdSttus "Indicates the forced execution status of diesel particulate filter regeneration.
000 Not Active
001 Active - Forced by Switch (See SPN 3696)
010 Active - Forced by Service Tool
011 Reserved for SAE Assignment
100 Reserved for SAE Assignment
 ...";
CM_ SG_ 2566749438 ExhaustSystemHighTempLampCmd "Command to control the exhaust system high temperature lamp.  This lamp indicates that the exhaust system temperature is high.
000 Off
001 On - solid
010 reserved for SAE assignment
011 reserved for SAE assignment
100 reserved for SAE ...";
CM_ SG_ 2566749438 DslPrtcltFltrAtmtcActvRgnrtnIntt "Indicates the configuration of diesel particulate filter active regeneration automatic initiation.

00 not enabled
01 enabled
10 reserved for SAE assignment
11 not available";
CM_ SG_ 2566749438 DslPrtcltFltrActvRgnrtnInhbt3717 "Indicates the state of diesel particulate filter active regeneration inhibition due to vehicle speed being less than the allowed vehicle speed.
00 not inhibited
01 inhibited
10 reserved for SAE assignment
11 not available
This SPN indicates the ...";
CM_ SG_ 2566749438 DslPrtcltFltrActvRgnrtnInhbtdDTE "Indicates the state of diesel particulate filter active regeneration inhibition due to the engine not being warmed up.
00 not inhibited
01 inhibited
10 reserved for SAE assignment
11 not available
This SPN indicates the reason for the diesel ...";
CM_ SG_ 2566749438 DslPrtcltFltrActvRgnrtnInhbt3715 "Indicates the state of diesel particulate filter active regeneration inhibition due to a permanent system lockout.
00 not inhibited
01 inhibited
10 reserved for SAE assignment
11 not available
This SPN indicates the reason for the diesel ...";
CM_ SG_ 2566749438 DslPrtcltFltrActvRgnrtnInhbtdDTT "Indicates the state of diesel particulate filter active regeneration inhibition due to a temporary system lockout.
00 not inhibited
01 inhibited
10 reserved for SAE assignment
11 not available
This SPN indicates the reason for the diesel ...";
CM_ SG_ 2566749438 DslPrtcltFltrActvRgnrtnInhbt3713 "Indicates the state of diesel particulate filter active regeneration inhibition due to a system timeout.
00 not inhibited
01 inhibited
10 reserved for SAE assignment
11 not available
This SPN indicates the reason for the diesel particulate ...";
CM_ SG_ 2566749438 DslPrtcltFltrActvRgnrtnInhbt3712 "Indicates the state of diesel particulate filter active regeneration inhibition due to a system fault being active.
00 not inhibited
01 inhibited
10 reserved for SAE assignment
11 not available
This SPN indicates the reason for the diesel ...";
CM_ SG_ 2566749438 DslPrtcltFltrActvRgnrtnInhbtdDTL "Indicates the state of diesel particulate filter active regeneration inhibition due to the exhaust temperature being too low.  This implies that the diesel particulate filter and/or oxidation catalyst are likewise too cold for active regeneration.
 ...";
CM_ SG_ 2566749438 DslPrtcltFltrActvRgnrtnInhbt3710 "Indicates the state of diesel particulate filter active regeneration inhibition due to the parking brake being not set.
00 not inhibited
01 inhibited
10 reserved for SAE assignment
11 not available
This SPN indicates the reason for the diesel ...";
CM_ SG_ 2566749438 DslPrtcltFltrActvRgnrtnInhbtdDTV "Indicates the state of diesel particulate filter active regeneration inhibition due to the vehicle speed being above an allowed limit.
00 not inhibited
01 inhibited
10 reserved for SAE assignment
11 not available
This SPN indicates the reason ...";
CM_ SG_ 2566749438 DslPrtcltFltrActvRgnrtnInhbtdDTO "Indicates the state of diesel particulate filter active regeneration inhibition due to the transmission being out of neutral.
00 not inhibited
01 inhibited
10 reserved for SAE assignment
11 not available
This SPN indicates the reason for the ...";
CM_ SG_ 2566749438 DslPrtcltFltrActvRgnrtnInhbtdDTA "Indicates the state of diesel particulate filter active regeneration inhibition due to the accelerator pedal being off idle.
00 not inhibited
01 inhibited
10 reserved for SAE assignment
11 not available
This SPN indicates the reason for the ...";
CM_ SG_ 2566749438 DslPrtcltFltrActvRgnrtnInhbtdDTP "Indicates the state of diesel particulate filter active regeneration inhibition due to the PTO being active.
00 not inhibited
01 inhibited
10 reserved for SAE assignment
11 not available
This SPN indicates the reason for the diesel particulate ...";
CM_ SG_ 2566749438 DslPrtcltFltrActvRgnrtnInhbtdDTS "Indicates the state of diesel particulate filter active regeneration inhibition due to the service brake being active.
00 not inhibited
01 inhibited
10 reserved for SAE assignment
11 not available
This SPN indicates the reason for the diesel ...";
CM_ SG_ 2566749438 DslPrtcltFltrActvRgnrtnInhbtdDTC "Indicates the state of diesel particulate filter active regeneration inhibition due to the clutch being disengaged.
00 not inhibited
01 inhibited
10 reserved for SAE assignment
11 not available
This SPN indicates the reason for the diesel ...";
CM_ SG_ 2566749438 DslPrtcltFltrActvRgnrtnInhbtdDTI "Indicates the state of diesel particulate filter active regeneration inhibition due to the Diesel Particulate Filter Regeneration Inhibit Switch.
00 not inhibited
01 inhibited
10 reserved for SAE assignment
11 not available
This SPN indicates ...";
CM_ SG_ 2566749438 DslPrtcltFltrActvRgnrtnInhbtdStt "Indicates the state of diesel particulate filter active regeneration inhibition.
00 not inhibited
01 inhibited
10 reserved for SAE assignment
11 not available
This SPN indicates the reason for the diesel particulate filter regeneration not ...";
CM_ SG_ 2566749438 AFTDPFStatus "Indicates the state of the diesel particulate filter regeneration need and urgency.  This is an aggregate of bank 1 and bank 2.  It is a system status and not individual bank status.
000 Regeneration not needed
001 Regeneration needed - lowest ...";
CM_ SG_ 2566749438 AFTDPFActiveRegenStatus "Indicates the state of diesel particulate filter active regeneration.  This is an aggregate of bank 1 and bank 2.  It is a system status and not individual bank status.
00 not active
01 active
10 regeneration needed - automatically initiated ...";
CM_ SG_ 2566749438 AFTDPFPassiveRegenStatus "Indicates the state of diesel particulate filter passive regeneration.  This is an aggregate of bank 1 and bank 2.  It is a system status and not individual bank status.


00 not active
01 active
10 reserved for SAE assignment
11 not available";
CM_ SG_ 2566749438 DieselParticulateFilterLampCmd "Command to control the diesel particulate filter lamp.
000 Off
001 On - solid
010 reserved for SAE assignment
011 reserved for SAE assignment
100 On - fast blink (1 HZ)
101 reserved for SAE assignment
110 reserved for SAE assignment
111 not ...";
CM_ BO_ 2566715646 "Diesel Particulate Filter 2 Soot 2
Additional diesel particulate filter soot parameters for diesel particulate filter 2.";
CM_ SG_ 2566715646 AFT2DPFSootSignalMin "Minimum output signal level of the current soot measurement from diesel particulate filter 2 soot sensor.  This is a statistical value, not the minimum sensing capability of the sensor.";
CM_ SG_ 2566715646 AFT2DPFSootSignalMax "Maximum output signal level of the current soot measurement from diesel particulate filter 2 soot sensor.  This is a statistical value, not the maximum sensing capability of the sensor.";
CM_ SG_ 2566715646 AFT2DPFSootSignalStdDeviation "Standard deviation of the soot measurement from diesel particulate filter 2 soot sensor.";
CM_ BO_ 2566724606 "Diesel Particulate Filter 2 Soot
Diesel particulate filter soot parameters for diesel particulate filter 2.";
CM_ SG_ 2566724606 DslPrtcltFltr2StSnsrECUIntrnlTmp "Internal temperature of the diesel particulate filter 2 soot sensor ECU.";
CM_ SG_ 2566724606 AFT2DPFSootSnsrPreliminaryFMI "Used to identify the applicable J1939-73 FMI detected in the soot sensor signal by the manufacturer뭩 sensor control software in diesel particulate filter 2.  In the case of multiple failures the most severe is communicated.
A value of 31 is sent ...";
CM_ SG_ 2566724606 AFT2DPFMedianSootSignal "Median output signal level from diesel particulate filter 2 soot sensor.";
CM_ SG_ 2566724606 AFT2DPFMeanSootSignal "Mean output signal level from diesel particulate filter 2 soot sensor.";
CM_ SG_ 2566724606 AFT2DPFSootDensity "Soot density in diesel particulate filter 2.";
CM_ SG_ 2566724606 AFT2DPFSootMass "Soot mass in diesel particulate filter 2.";
CM_ BO_ 2566715902 "Diesel Particulate Filter 1 Soot 2
Additional diesel particulate filter soot parameters for diesel particulate filter 1.";
CM_ SG_ 2566715902 AFT1DPFSootSignalMin "Minimum output signal level of the current soot measurement from diesel particulate filter 1 soot sensor.  This is a statistical value, not the minimum sensing capability of the sensor.";
CM_ SG_ 2566715902 AFT1DPFSootSignalMax "Maximum output signal level of the current soot measurement from diesel particulate filter 1 soot sensor.  This is a statistical value, not the maximum sensing capability of the sensor.";
CM_ SG_ 2566715902 AFT1DPFSootSignalStdDeviation "Standard deviation of the soot measurement from diesel particulate filter 1 soot sensor.";
CM_ BO_ 2566724862 "Diesel Particulate Filter 1 Soot
Diesel particulate filter soot parameters for diesel particulate filter 1.";
CM_ SG_ 2566724862 DslPrtcltFltr1StSnsrECUIntrnlTmp "Internal temperature of the diesel particulate filter 1 soot sensor ECU.";
CM_ SG_ 2566724862 AFT1DPFSootSnsrPreliminaryFMI "Used to identify the applicable J1939-73 FMI detected in the soot sensor signal by the manufacturer뭩 sensor control software in diesel particulate filter 1. In the case of multiple failures the most severe is communicated.
A value of 31 is sent to ...";
CM_ SG_ 2566724862 AFT1DPFMedianSootSignal "Median output signal level from diesel particulate filter 1 soot sensor.";
CM_ SG_ 2566724862 AFT1DPFMeanSootSignal "Mean output signal level from diesel particulate filter 1 soot sensor.";
CM_ SG_ 2566724862 AFT1DPFSootDensity "Soot density in diesel particulate filter 1.";
CM_ SG_ 2566724862 AFT1DPFSootMass "Soot mass in diesel particulate filter 1.";
CM_ BO_ 2566718718 "Direct Lamp Control Data 2
This message will be transmitted by the controller that is illuminating the lamps.

It is not required to be used with PGN 64774.";
CM_ SG_ 2566718718 HillHolderLampData "This message will be transmitted by the controller that is illuminating the lamps.

00 - Lamp deactivated (Off)
01 - Lamp activated (On)
10 - Error
11 - Not Available";
CM_ SG_ 2566718718 VehicleBatteryChargingLampData "This parameter provides measured data from the Vehicle Battery Charging Lamp.

00 - Lamp deactivated (Off)
01 - Lamp activated (On)
10 - Error
11 - Not available";
CM_ SG_ 2566718718 VehicleHVACRecirculationLampData "This parameter provides measured data from the Vehicle HVAC Recirculation Lamp.

00 - Lamp deactivated (Off)
01 - Lamp activated (On)
10 - Error
11 - Not available";
CM_ SG_ 2566718718 VehicleAirPressLowLampData "This parameter provides measured data from the Vehicle Air Pressure Low Lamp.

00 - Lamp deactivated (Off)
01 - Lamp activated (On)
10 - Error
11 - Not available";
CM_ SG_ 2566718718 VehicleFuelLevelLowLampData "This parameter provides measured data from the Vehicle Fuel Level Low Lamp.

00 - Lamp deactivated (Off)
01 - Lamp activated (On)
10 - Error
11 - Not available";
CM_ SG_ 2566718718 VehicleBatteryVoltageLowLampData "This parameter provides measured data from the Vehicle Battery Voltage Low Lamp.

00 - Lamp deactivated (Off)
01 - Lamp activated (On)
10 - Error
11 - Not available";
CM_ BO_ 2566718974 "Direct Lamp Control Data 1
This message will be transmitted by the controller that is illuminating the lamps.

It is not required to be used with PGN 64775.";
CM_ SG_ 2566718974 EngStopStartEnabledLamp "Provides measured data from the engine stop-start enabled lamp.

00b - Lamp deactivated (Off)
01b - Lamp activated (On)
10b - Error
11b - Not available";
CM_ SG_ 2566718974 EngStopStartAutoStartFailedLamp "Provides measured data from the engine stop-start automatic start failed lamp.

00b - Lamp deactivated (Off)
01b - Lamp activated (On)
10b - Error
11b - Not available";
CM_ SG_ 2566718974 EngStopStartAutoStopActiveLamp "Provides measured data from the engine stop-start automatic stop active lamp.

00b - Lamp deactivated (Off)
01b - Lamp activated (On)
10b - Error
11b - Not available";
CM_ SG_ 2566718974 VhclAcclerationRateLimitLampData "This parameter provides measured data from the Vehicle Acceleration Rate Limit Lamp.

00 - Lamp deactivated (Off)
01 - Lamp activated (On)
10 - Error
11 - Not available";
CM_ SG_ 2566718974 EngSpeedVeryHighLampData "This parameter provides measured data from the Engine Speed Very High Warning Lamp.

00 - Lamp Deactivated (Off)
01 - Lamp Activated (On)
10 - Error
11 - Not available";
CM_ SG_ 2566718974 EngSpeedHighLampData "This parameter provides measured data from the Engine Speed High Warning Lamp.

00 - Lamp Deactivated (Off)
01 - Lamp Activated (On)
10 - Error
11 - Not available";
CM_ SG_ 2566718974 EngCtrlMdule3ReadyForUseLampData "This parameter provides measured data from the Engine Control Module 3 Ready for Use Lamp.

00 - Lamp deactivated (Off)
01 - Lamp activated (On)
10 - Error
11 - Not Available";
CM_ SG_ 2566718974 EngCtrlMdule2ReadyForUseLampData "This parameter provides measured data from the Engine Control Module 2 Ready for Use Lamp.

00 - Lamp deactivated (Off)
01 - Lamp activated (On)
10 - Error
11 - Not Available";
CM_ SG_ 2566718974 EngCtrlMdule1ReadyForUseLampData "This parameter provides measured data from the Engine Control Module 1 Ready for Use Lamp.

00 - Lamp deactivated (Off)
01 - Lamp activated (On)
10 - Error
11 - Not Available";
CM_ SG_ 2566718974 EngWaitToStartLampData "This parameter provides measured data from the Engine Wait To Start Lamp.  See SPN 1081 for the command.

00 - Lamp deactived (off)
01 - Lamp actived (on)
10 - Error
11 - Not available";
CM_ SG_ 2566718974 EngFuelFilterRestrictedLampData "This parameter provides measured data from the Engine Fuel Filter Restricted Lamp.

00 - Lamp deactivated (Off)
01 - Lamp activated (On)
10 - Error
11 - Not available";
CM_ SG_ 2566718974 EngAirFilterRestrictionLampData "This parameter provides measured data from the Engine Air Filter Restriction Lamp.

00 - Lamp deactivated (Off)
01 - Lamp activated (On)
10 - Error
11 - Not available";
CM_ SG_ 2566718974 EngIdleManagementActiveLampData "This parameter provides measured data from the Engine Idle Management Active Lamp.

00 - Lamp deactivated (Off)
01 - Lamp activated (On)
10 - Error
11 - Not available";
CM_ SG_ 2566718974 EngCoolantLevelLowLampData "This parameter provides measured data from the Engine Coolant Level Low Lamp.

00 - Lamp deactivated (Off)
01 - Lamp activated (On)
10 - Error
11 - Not available";
CM_ SG_ 2566718974 EngCoolantTempHighLampData "This parameter provides measured data from the Engine Coolant Temperature High Lamp.

00 - Lamp deactivated (Off)
01 - Lamp activated (On)
10 - Error
11 - Not available";
CM_ SG_ 2566718974 EngOilPressLowLampData "This parameter provides measured data from the Engine Oil Pressure Low Lamp.

00 - Lamp deactivated (Off)
01 - Lamp activated (On)
10 - Error
11 - Not available";
CM_ SG_ 2566718974 CmprssnBrkEnblSwtchIndctrLmpData "This parameter provides measured data from the Compression Brake Enable Switch Indicator Lamp.

00 - Lamp deactivated (Off)
01 - Lamp activated (On)
10 - Error
11 - Not available";
CM_ SG_ 2566718974 EngBrakeActiveLampData "This parameter provides measured data from the Engine Brake Active Lamp.

00 - Lamp deactivated (Off)
01 - Lamp activated (On)
10 - Error
11 - Not available";
CM_ SG_ 2566718974 OBDMalfunctionIndicatorLampData "This parameter provides measured data from the OBD Malfunction Indicator Lamp.

00 - Lamp deactivated (Off)
01 - Lamp activated (On)
10 - Error
11 - Not available";
CM_ SG_ 2566718974 EngRedStopLampData "This parameter provides measured data from the Engine Red Stop Lamp.

00 - Lamp deactivated (Off)
01 - Lamp activated (On)
10 - Error
11 - Not available";
CM_ SG_ 2566718974 EngAmberWarningLampData "This parameter provides measured data from the Engine Amber Warning Lamp.

00 - Lamp deactivated (Off)
01 - Lamp activated (On)
10 - Error
11 - Not available";
CM_ SG_ 2566718974 EngProtectLampData "This parameter provides measured data from the Engine Protect Lamp.

00 - Lamp deactivated (Off)
01 - Lamp activated (On)
10 - Error
11 - Not available";
CM_ BO_ 2566719230 "Direct Lamp Control Command 2
Message that directly controls the driver indicator lamps.   See also PGN 64775 for additional lamps and PGN 64772 for the feedback information about these lamps.
Note: Since this message is direct lamp control, it is ...";
CM_ SG_ 2566719230 HillHolderLampCmd "Command signal directly controlling Hill Holder Lamp.

00 - Lamp Off
01 - Lamp On
10 - Lamp Flash (1 Hz)
11 - Not available";
CM_ SG_ 2566719230 VehicleBatteryChargingLampCmd "Command signal directly controlling the Vehicle Battery Charging Lamp.

00 - Lamp Off
01 - Lamp On
10 - Reserved
11 - Not available";
CM_ SG_ 2566719230 VehicleHVACRecirculationLampCmd "Command signal directly controlling the Vehicle HVAC Recirculation Lamp.

00 - Lamp Off
01 - Lamp On
10 - Reserved
11 - Not available";
CM_ SG_ 2566719230 VehicleAirPressLowLampCmd "Command signal directly controlling the Vehicle Air Pressure Low Lamp.

00 - Lamp Off
01 - Lamp On
10 - Reserved
11 - Not available";
CM_ SG_ 2566719230 VehicleFuelLevelLowLampCmd "Command signal directly controlling the Vehicle Fuel Level Low Lamp.

00 - Lamp Off
01 - Lamp On
10 - Reserved
11 - Not available";
CM_ SG_ 2566719230 VehicleBatteryVoltageLowLampCmd "Command signal directly controlling the Vehicle Battery Voltage Low Lamp.

00 - Lamp Off
01 - Lamp On
10 - Reserved
11 - Not available";
CM_ BO_ 2560818942 "Regulated Exhaust Emission Level Exceedance
Provides the DTCs and associated timers related to a regulated exhaust emission level exceedance due to an emission control system malfunction.";
CM_ SG_ 2560818942 SPN1 "This 19-bit number is used to identify the item for which diagnostics are being reported.";
CM_ SG_ 2560818942 FailureModeIdentifier1 "The FMI defines the type of failure detected in the subsystem identified by an SPN.";
CM_ SG_ 2560818942 DTCTimeUntilDerate "This timer provides the number of hours the malfunction has until the OBD required derate will occur";
CM_ SG_ 2560818942 DTCTotalPreviouslyActiveTime "This timer provides the number of hours the NOx malfunction has been confirmed and previously active";
CM_ SG_ 2560818942 DTCTotalActiveTime "This timer provides the total number of hours the DTC has been confirmed and active";
CM_ SG_ 2560818942 SPN1High "SPN #1 (Conversion Version 4)";
CM_ BO_ 2561212158 "Text Display
This provides ASCII text information, for example to an display instrument.  Broadcast rate should be on event and 1-5 seconds due to variable character length.  This message is to convey information from an ecu to a display.  In its ...";
CM_ SG_ 2561212158 TextDisplayIndex "Used for overwriting consecutive bytes of a displayed string when byte 1 \"Text Display Instructions\" state is set for \"overwrite substring\" mode.  When used, this byte declares where in the text string that the new text will start overwriting, this ...";
CM_ SG_ 2561212158 TextDisplayInstructions "This parameter describes the status for the display how to show the information.
0000 Clear display - The displayed information should be deleted or not displayed any more.
0001 Hold display - The presently displayed information should be retained
 ...";
CM_ BO_ 2566746366 "Door ramp control
This message reports the current status of door ramps";
CM_ SG_ 2566746366 RetractStatusOfRamp5 "Retract status of ramp at doorway 5, counting from front to back on the vehicle.
 
00 ramp retracted
01 ramp extended
10 error
11 not available";
CM_ SG_ 2566746366 RetractStatusOfRamp4 "Retract status of ramp at doorway 4, counting from front to back on the vehicle.
 
00 ramp retracted
01 ramp extended
10 error
11 not available";
CM_ SG_ 2566746366 MovementStatusOfRamp5 "Movement status of ramp at doorway 5, counting from front to back on the vehicle.

00 ramp not being moved
01 ramp being moved
10 error
11 not available";
CM_ SG_ 2566746366 MovementStatusOfRamp4 "Movement status of ramp at doorway 4, counting from front to back on the vehicle.

00 ramp not being moved
01 ramp being moved
10 error
11 not available";
CM_ SG_ 2566746366 EnableStatusOfRamp5 "Enable status of ramp at doorway 5, counting from front to back on the vehicle.

00 ramp disabled
01 ramp enabled 
10 error 
11 not available";
CM_ SG_ 2566746366 EnableStatusOfRamp4 "Enable status of ramp at doorway 4, counting from front to back on the vehicle.

00 ramp disabled
01 ramp enabled 
10 error 
11 not available";
CM_ SG_ 2566746366 MovementStatusOfRamp3 "Movement status of ramp at doorway 3, counting from front to back on the vehicle.

00 ramp not being moved
01 ramp being moved
10 error
11 not available";
CM_ SG_ 2566746366 EnableStatusOfRamp3 "Enable status of ramp at doorway 3, counting from front to back on the vehicle.

00 ramp disabled
01 ramp enabled 
10 error 
11 not available";
CM_ SG_ 2566746366 RetractStatusOfRamp3 "Retract status of ramp at doorway 3, counting from front to back on the vehicle.

00 ramp retracted
01 ramp extended
10 error
11 not available";
CM_ SG_ 2566746366 MovementStatusOfRamp2 "Movement status of ramp at doorway 2, counting from front to back on the vehicle.

00 ramp not being moved
01 ramp being moved
10 error
11 not available";
CM_ SG_ 2566746366 EnableStatusOfRamp2 "Enable status of ramp at doorway 2, counting from front to back on the vehicle.

00 ramp disabled
01 ramp enabled 
10 error 
11 not available";
CM_ SG_ 2566746366 RetractStatusOfRamp2 "Retract status of ramp at doorway 2, counting from front to back on the vehicle.

00 ramp retracted
01 ramp extended
10 error
11 not available";
CM_ SG_ 2566746366 MovementStatusOfRamp1 "Movement status of ramp at doorway 1, counting from front to back on the vehicle.

00 ramp not being moved
01 ramp being moved
10 error
11 not available";
CM_ SG_ 2566746366 EnableStatusOfRamp1 "Enable status of ramp at doorway 1, counting from front to back on the vehicle.

        00 ramp disabled
        01 ramp enabled 
       10 error 
       11 not available";
CM_ SG_ 2566746366 RetractStatusOfRamp1 "Retract status of ramp at doorway 1, counting from front to back on the vehicle.
 
00 ramp retracted
01 ramp extended
10 error
11 not available";
CM_ BO_ 2566750206 "Engine Configuration 2
Contains static information about the engine.  To be used with data that will not change during vehicle operation.
.";
CM_ SG_ 2566750206 TransIdleGovFuelingInhSupport "Companion parameter to 밫ransmission Idle Governor Fueling Inhibit� (SPN 7829). This 밹onfiguration� parameter provides confirmation to the Transmission that the engine supports the 밫ransmission Idle Governor Fueling Inhibit� feature.
00 - ...";
CM_ SG_ 2566750206 EngConfigIdentification "Used to identify the hardware configuration of engine family. Each number will have a reference to set of parameters such as, but not limited to, number of cylinders, piston displacement, bore size and firing angles.";
CM_ SG_ 2566750206 NmbrOfCmbstionCyclesForAveraging "Defined number of combustion cycles used for calculating average parameters of combustion in each cylinder.";
CM_ SG_ 2566750206 MaxCrankAttemptsPerStartAttempt "The number of cranking cycles that will be performed before ending the start attempt.  This is intended to be used in conjunction with Crank Attempt Count on Present Start Attempt, in order to give a FMI 0 diagnostic on the latter.";
CM_ BO_ 2566755582 "Electronic Engine Controller 7
Engine related parameters";
CM_ SG_ 2566755582 CommandedEngIntakeManifoldPress "Provides the commanded set point value for the engine intake manifold pressure.";
CM_ SG_ 2566755582 EngCrnkcsBrtherOilSeparatorSpeed "The speed of a rotating (centrifugal) crankcase oil separator.";
CM_ SG_ 2566755582 EngExhstGsRcirculation1Valve2Pos "The position of the second exhaust gas recirculation valve expressed as a percentage of full travel. Zero percent means the valve is closed and no exhaust gas is flowing into the intake air stream. One hundred percent means the valve is fully ...";
CM_ SG_ 2566755582 EngExhstGsRecirculation1ValvePos "The position of the exhaust gas recirculation valve expressed as a percentage of full travel. Zero percent means the valve is closed and no exhaust gas is flowing into the intake air stream. One hundred percent means the valve is fully opened.";
CM_ BO_ 2566746110 "Electronic Engine Controller 8
Engine related parameters";
CM_ SG_ 2566746110 EngExhstGsRcrcltn1ClerEfficiency "Exhaust Gas Recirculation cooler efficiency is an indication of the cooler뭩 ability to reduce the temperature of the exhaust gas that is being recirculated back to the intake. 0% = no reduction in temperature, 100% = maximum cooling.  The EGR ...";
CM_ SG_ 2566746110 EngExhstGsRcrcltn1ClrIntkGsAbsPr "Exhaust gas recirculation absolute pressure is measured at the EGR cooler intake. See SPN 3358 for EGR pressure measured at the EGR cooler outlet before the valve.";
CM_ SG_ 2566746110 EngExhstGsRcrcltn1ClerIntakeTemp "Exhaust Gas Recirculation (EGR) Temperature measured at the EGR cooler intake.  See SPN 412 for Engine EGR temperature which is typically measured at the EGR cooler outlet.";
CM_ SG_ 2566746110 EngExhstGsRcrculation1Valve2Ctrl "Desired percentage of maximum Exhaust Gas Recirculation (EGR) valve opening for valve 2.  0% means valve is closed. 100% means maximum valve opening (full gas flow).";
CM_ BO_ 2566752510 "Engine Fluid Level/Pressure 5
This message contains Engine Intake Valve Actuation Oil Pressure information.";
CM_ SG_ 2566752510 EngIntkVlvActtionOilPressForCyl4 "The gage pressure of the oil in the hydraulic accumulator that powers the engine intake valve for cylinder #4.";
CM_ SG_ 2566752510 EngIntkVlvActtionOilPressForCyl3 "The gage pressure of the oil in the hydraulic accumulator that powers the engine intake valve for cylinder #3.";
CM_ SG_ 2566752510 EngIntkVlvActtionOilPressForCyl2 "The gage pressure of the oil in the hydraulic accumulator that powers the engine intake valve for cylinder #2.";
CM_ SG_ 2566752510 EngIntkVlvActtionOilPressForCyl1 "The gage pressure of the oil in the hydraulic accumulator that powers the engine intake valve for cylinder #1.
This intake valve pressure is at the first cylinder in the engine, while SPN 2948 reflects the intake valve pressure of the entire engine ...";
CM_ BO_ 2566752254 "Engine Fluid Level/Pressure 6
This message contains Engine Intake Valve Actuation Oil Pressure information.";
CM_ SG_ 2566752254 EngIntkVlvActtionOilPressForCyl8 "The gage pressure of the oil in the hydraulic accumulator that powers the engine intake valve for cylinder #8.";
CM_ SG_ 2566752254 EngIntkVlvActtionOilPressForCyl7 "The gage pressure of the oil in the hydraulic accumulator that powers the engine intake valve for cylinder #7.";
CM_ SG_ 2566752254 EngIntkVlvActtionOilPressForCyl6 "The gage pressure of the oil in the hydraulic accumulator that powers the engine intake valve for cylinder #6.";
CM_ SG_ 2566752254 EngIntkVlvActtionOilPressForCyl5 "The gage pressure of the oil in the hydraulic accumulator that powers the engine intake valve for cylinder #5.";
CM_ BO_ 2566751998 "Engine Fluid Level/Pressure 7
This message contains Engine Intake Valve Actuation Oil Pressure information.";
CM_ SG_ 2566751998 EngIntkVlvActtonOilPressForCyl12 "The gage pressure of the oil in the hydraulic accumulator that powers the engine intake valve for cylinder #12.";
CM_ SG_ 2566751998 EngIntkVlvActtonOilPressForCyl11 "The gage pressure of the oil in the hydraulic accumulator that powers the engine intake valve for cylinder #11.";
CM_ SG_ 2566751998 EngIntkVlvActtonOilPressForCyl10 "The gage pressure of the oil in the hydraulic accumulator that powers the engine intake valve for cylinder #10.";
CM_ SG_ 2566751998 EngIntkVlvActtionOilPressForCyl9 "The gage pressure of the oil in the hydraulic accumulator that powers the engine intake valve for cylinder #9.";
CM_ BO_ 2566751742 "Engine Fluid Level/Pressure 8
This message contains Engine Intake Valve Actuation Oil Pressure information.";
CM_ SG_ 2566751742 EngIntkVlvActtonOilPressForCyl16 "The gage pressure of the oil in the hydraulic accumulator that powers the engine intake valve for cylinder #16.";
CM_ SG_ 2566751742 EngIntkVlvActtonOilPressForCyl15 "The gage pressure of the oil in the hydraulic accumulator that powers the engine intake valve for cylinder #15.";
CM_ SG_ 2566751742 EngIntkVlvActtonOilPressForCyl14 "The gage pressure of the oil in the hydraulic accumulator that powers the engine intake valve for cylinder #14.";
CM_ SG_ 2566751742 EngIntkVlvActtonOilPressForCyl13 "The gage pressure of the oil in the hydraulic accumulator that powers the engine intake valve for cylinder #13.";
CM_ BO_ 2566751486 "Engine Fluid Level/Pressure 9
This message contains Engine Intake Valve Actuation Oil Pressure information.";
CM_ SG_ 2566751486 EngIntkVlvActtonOilPressForCyl20 "The gage pressure of the oil in the hydraulic accumulator that powers the engine intake valve for cylinder #20.";
CM_ SG_ 2566751486 EngIntkVlvActtonOilPressForCyl19 "The gage pressure of the oil in the hydraulic accumulator that powers the engine intake valve for cylinder #19.";
CM_ SG_ 2566751486 EngIntkVlvActtonOilPressForCyl18 "The gage pressure of the oil in the hydraulic accumulator that powers the engine intake valve for cylinder #18.";
CM_ SG_ 2566751486 EngIntkVlvActtonOilPressForCyl17 "The gage pressure of the oil in the hydraulic accumulator that powers the engine intake valve for cylinder #17.";
CM_ BO_ 2499641854 "EGR Cooler Bypass
Contains information about the EGR Cooler Bypass";
CM_ SG_ 2499641854 EGR1CoolerBypassActuatorPostion "The parameter gives the % open of the exhaust gas recirculation cooler bypass actuator, where 0% = Fully Closed (no gas flowing through the bypass), and 100% = Fully Open.";
CM_ BO_ 2566748158 "Engine Spark Voltage 1
The PGN contains information about spark voltage values for cylinders 1 through 4.  This is the secondary voltage of the combustion event.";
CM_ SG_ 2566748158 EngSparkPlug4 "The measured voltage of the spark event on Cylinder #4";
CM_ SG_ 2566748158 EngSparkPlug3 "The measured voltage of the spark event on Cylinder #3";
CM_ SG_ 2566748158 EngSparkPlug2 "The measured voltage of the spark event on Cylinder #2";
CM_ SG_ 2566748158 EngSparkPlug1 "The measured voltage of the spark event on Cylinder #1";
CM_ BO_ 2566747902 "Engine Spark Voltage 2
The PGN contains information about spark voltage values for cylinders 5 through 8.  This is the secondary voltage of the combustion event.";
CM_ SG_ 2566747902 EngSparkPlug8 "The measured voltage of the spark event on Cylinder #8";
CM_ SG_ 2566747902 EngSparkPlug7 "The measured voltage of the spark event on Cylinder #7";
CM_ SG_ 2566747902 EngSparkPlug6 "The measured voltage of the spark event on Cylinder #6";
CM_ SG_ 2566747902 EngSparkPlug5 "The measured voltage of the spark event on Cylinder #5";
CM_ BO_ 2566747646 "Engine Spark Voltage 3
The PGN contains information about spark voltage values for cylinders 9 through 12.  This is the secondary voltage of the combustion event.";
CM_ SG_ 2566747646 EngSparkPlug12 "The measured voltage of the spark event on Cylinder #12";
CM_ SG_ 2566747646 EngSparkPlug11 "The measured voltage of the spark event on Cylinder #11";
CM_ SG_ 2566747646 EngSparkPlug10 "The measured voltage of the spark event on Cylinder #10";
CM_ SG_ 2566747646 EngSparkPlug9 "The measured voltage of the spark event on Cylinder #9";
CM_ BO_ 2566747390 "Engine Spark Voltage 4
The PGN contains information about spark voltage values for cylinders 13 through 16.  This is the secondary voltage of the combustion event.";
CM_ SG_ 2566747390 EngSparkPlug16 "The measured voltage of the spark event on Cylinder #16";
CM_ SG_ 2566747390 EngSparkPlug15 "The measured voltage of the spark event on Cylinder #15";
CM_ SG_ 2566747390 EngSparkPlug14 "The measured voltage of the spark event on Cylinder #14";
CM_ SG_ 2566747390 EngSparkPlug13 "The measured voltage of the spark event on Cylinder #13";
CM_ BO_ 2566747134 "Engine Spark Voltage 5
The PGN contains information about spark voltage values for cylinders 17 through 20.  This is the secondary voltage of the combustion event.";
CM_ SG_ 2566747134 EngSparkPlug20 "The measured voltage of the spark event on Cylinder #20";
CM_ SG_ 2566747134 EngSparkPlug19 "The measured voltage of the spark event on Cylinder #19";
CM_ SG_ 2566747134 EngSparkPlug18 "The measured voltage of the spark event on Cylinder #18";
CM_ SG_ 2566747134 EngSparkPlug17 "The measured voltage of the spark event on Cylinder #17";
CM_ BO_ 2566746878 "Engine Spark Voltage 6
The PGN contains information about spark voltage values for cylinders 21 through 24.  This is the secondary voltage of the combustion event.";
CM_ SG_ 2566746878 EngSparkPlug24 "The measured voltage of the spark event on Cylinder #24";
CM_ SG_ 2566746878 EngSparkPlug23 "The measured voltage of the spark event on Cylinder #23";
CM_ SG_ 2566746878 EngSparkPlug22 "The measured voltage of the spark event on Cylinder #22";
CM_ SG_ 2566746878 EngSparkPlug21 "The measured voltage of the spark event on Cylinder #21";
CM_ BO_ 2561277694 "Forward Lane Image Command
Message containing commands, sent to the forward image controller";
CM_ SG_ 2561277694 ReqActiveSteerDriverPrefMode "The requested active steering mode to the active steering system from the operators interface. This parameter is the driver's request, the state is shown in SPN 9757.
000b - Requested Active Steering Mode #1
001b - Requested Active Steering Mode ...";
CM_ SG_ 2561277694 CenteringEnableCmd "Command to enable/disable lane centering system.

00b - Disable lane centering
01b - Enable lane centering
10b - Reserved
11b - Don큧 care";
CM_ SG_ 2561277694 KeepingAssistEnableCmd "Command to enable/disable lane keeping assist system.

00b - Disable lane keeping assist
01b - Enable lane keeping assist
10b - Reserved
11b - Don큧 care";
CM_ SG_ 2561277694 CurSubRegion "Command sent to all Forward Imager which specifies the operator뭩 desired sub-region to assist with object recognition.
This signal will be dependent on Current Region and shall use the 3-character string subdivision codes in ISO 3166-2 standard.
 ...";
CM_ SG_ 2561277694 CurRegion "Command sent to forward imager which specifies the operator뭩 desired region to assist with object recognition.
Message shall use the 2-character string country codes in ISO 3166-1 alpha-2.
Typical examples from ISO 3166-1 alpha-2 are:
France: FR
 ...";
CM_ SG_ 2561277694 LaneDepartureWarningEnableCmd "Command to enable/disable Lane Departure Indication

00   Disable Lane Departure Warning
01   Enable Lane Departure Warning
10   Reserved
11   Don큧 care";
CM_ BO_ 2633861886 "SAE J2012 DTC Display
Conveys basic SAE J2012 DTC information for on-board or service tool displays.
If PGN 64906 is requested and a supporting device has no active or inactive J2012 DTCs, PGN 64906 shall be sent with the first data byte ( Number ...";
CM_ SG_ 2633861886 J2012DTCOccurrenceCount "Number of occurrences of the respective SAE J2012 DTC being conveyed.
If more than 126 occurrences happen the value shall be set to 126.
If the occurrence count is not available to be sent then this value shall be set to 127.";
CM_ SG_ 2633861886 J2012DTCStatus "Indicates if the respective SAE J2012 DTC is active or previously active.

0 - DTC is previously active
1 - DTC is active";
CM_ SG_ 2633861886 J2012DTC "Five character ASCII SAE J2012 DTC, sent most significant byte first.";
CM_ SG_ 2633861886 NumberOfJ2012DTCs "The number J2012 DTCs being conveyed in PGN 64906.  If the value of this parameter is zero, the device broadcasting PGN 64906 has no active or previously active J2012 DTCs.";
CM_ BO_ 2565873150 "Steering Angle Sensor Information
Contains information which relates to a steering angle sensor.";
CM_ SG_ 2565873150 MessageChecksum "The message checksum is used to verify the signal path from the demanding device to the steering controller.  The support of this parameter is mandatory if PGN 61469 is supported as there is no means to indicate 뱊ot available�.
The 4 bit checksum ...";
CM_ SG_ 2565873150 MessageCounter "The message counter is to verify the signal path from the demanding device to the steering controller.  The support of this parameter is mandatory.
Note:  The initial value of the 4 bit message counter for the first message during a driving cycle ...";
CM_ SG_ 2565873150 SteerAngleSensorCalibrated "This signal indicates the calibration status of the steering angle sensor.

00 - SAS not calibrated
01 - SAS calibrated
10 - Reserved
11 - Not available";
CM_ SG_ 2565873150 SteerAngleSensorActiveMode "This signal indicates the operational mode of the steering angle sensor.

00 - Programming mode active
01 - Normal mode active
10 - Reserved
11 - Not available";
CM_ SG_ 2565873150 SteerWheelAngleRange "The signal indicates the range of  the steering wheel angle the sensor element is capable to measure. The steering wheel angle signal ranges between the negative and the positive value of the steering wheel angle range.
For example, a steering ...";
CM_ SG_ 2565873150 SteerWheelAngleRangeCounterType "The signal indicates whether the steering wheel angle sensor is capable of absolute measuring of the number of steering wheel angle ranges or not.  Absolute measuring means that the steering wheel angle range counter signal indicates the real ...";
CM_ SG_ 2565873150 SteerWheelAngleRangeCounter "The signal indicates the number of steering wheel angle range overflows if the operating range of steering wheel is greater than the measuring range of sensor element. Positive values indicate left turns (counterclockwise). If the steering wheel ...";
CM_ SG_ 2565873150 SteerWheelAngle "The main operator`s steering wheel angle (on the steering column, not the actual wheel angle). The vehicle being steered to the left (counterclockwise) results in a positive steering wheel angle.  This is the yaw angle of the steering wheel with the ...";
CM_ BO_ 2566745854 "Aftertreatment 1 SCR Service Information 1
This message contains SCR service information for aftertreatment system 1 (or bank 1).";
CM_ SG_ 2566745854 SysSulfationLvl "Indicates the sulfur level in the SCR system for aftertreatment 1.
.
100% level could be the regeneration trigger level (and if conditions are not favorable for regeneration, sulfation loading can continue beyond 100%). During normal operation and ...";
CM_ SG_ 2566745854 SCROpIndActiveTraveledDist "The distance traveled while SCR inducement (SPN 5246 is equal to level 1 to 5) is active.  Distance is reset once inducement is no longer active for SCR (SPN 5246 = 0).
Emission Control System Operator Inducement Severity, SPN 5826, may be active ...";
CM_ SG_ 2566745854 ConversionEfficiency "The SCR conversion efficiency percentage.  Calculated as 100 times the catalyst intake NOx minus the catalyst outlet NOx divided by the catalyst intake NOx.  The catalyst conversion efficiency number in itself does not imply emissions compliance or ...";
CM_ SG_ 2566745854 CommandedDEFConsumption "This parameter transmits the amount of diesel exhaust fluid that the emissions control system has requested to be used, averaged over the past 15 hours of engine operation.
Used to determine whether the SCR system is using an appropriate amount of ...";
CM_ SG_ 2566745854 DEFAvgConsumption "Measured use of diesel exhaust fluid by a Selective Catalytic Reduction system for exhaust emission control, averaged over the previous 15 hours of engine operation.
Used to determine whether the SCR system is using an appropriate amount of diesel ...";
CM_ BO_ 2566751230 "Transfer Case Information
Transfer Case Information";
CM_ SG_ 2566751230 MessageChecksum "The message checksum is used to verify the signal path from the transmitting device to the receiving device.
The message checksum is calculated using the first 7 data bytes, the message counter and the bytes of the message identifier. It is ...";
CM_ SG_ 2566751230 MessageCounter "The message counter is used to detect situations where the transmitting ECU malfunction repeats the same frame all the time.  The receiver of the information may use the counter parameter to detect this situation.  The transmitting device will ...";
CM_ SG_ 2566751230 ActualGearRatio "Actual ratio of input shaft speed to output shaft speed of the transfer case.";
CM_ SG_ 2566751230 DirStatus "Indicates the vehicle direction capability based on the current transfer case or 뱎ower shuttle� state.  Such devices are typically downstream of the traditional powertrain, and simply change the rotational direction of the powertrain output. They ...";
CM_ SG_ 2566751230 TransferCaseStatus "This parameter describes the feedback from the  transfer case controller . Used by instrument clusters,  tachographs, PTOs , etc.
000 2 wheel high (normal or `'On Highway' Range)
001 4 wheel high (normal or  'On Highway' Range
010 neutral
011 2 ...";
CM_ BO_ 2566755838 "Transmission Fluids 2";
CM_ SG_ 2566755838 TransOilLevel2MeasurementStatus "Measurement status for the second instance of a transmission oil level indicator. Indicates if conditions are acceptable to obtain a valid transmission oil level measurement as conveyed in SPN 5914 Transmission Oil Level 2 High / Low. If conditions ...";
CM_ SG_ 2566755838 TransOilLevel2CountdownTimer "Countdown timer for the second instance of a transmission oil level indicator. Once all vehicle conditions (such as vehicle stopped, etc) are met, some transmissions may require a 몊ettling time� to allow the fluid level to normalize. This parameter ...";
CM_ SG_ 2566755838 TransOilLevel2High_Low "Second instance of a transmission oil level indicator. Conveys the current volume of transmission sump oil compared to recommended volume. Positive values indicate overfill. Zero means the transmission fluid is filled to the recommended level. If ...";
CM_ SG_ 2566755838 TransOilTemp2 "Second instance of transmission lubricant temperature. This parameter may reflect the temperature of a second sump or oil supply. If only one instance of transmission lubricant temperature measurement exists, SPN 177 Transmission Oil Temperature 1 ...";
CM_ SG_ 2566755838 TransOilLifeRemaining "Signal which indicates the actual oil life remaining in percent.  100% means the transmission oil is brand new, and 0% means the transmission oil is at the end of its life.";
CM_ SG_ 2566755838 TrnsTorqueConverterOilOutletTemp "Temperature of transmission torque converter outlet oil.";
CM_ SG_ 2566755838 TransOverheatIndicator "Signal from transmission indicating that its fluid temperature is above normal acceptable limits, and as a result, transmission operation may be altered or restricted.  The indicator is typically a lamp.  Distinctions in meaning between the ...";
CM_ SG_ 2566755838 TransOilLevelSwitch "This switch indicates whether transmission oil level is full or empty.

00 - Empty
01 - Full or not empty
10 - Error
11 - Not available";
CM_ SG_ 2566755838 TransOilFilterRestrictionSwitch "This switch indicates whether the transmission oil filter is clogged.

00 - No restriction
01 - Restriction exists on oil filter
10 - Error
11 - Not available";
CM_ BO_ 2566752766 "Vehicle Direction/Speed 2
Vehicle Direction/Speed 2 PGN contains the vehicle roll data.";
CM_ SG_ 2566752766 VehicleRoll "This parameter indicates the roll in degrees from level.  Facing the direction of travel a tip to the left would be indicated by a negative number and a tip to the right would be indicated by a positive number.";
CM_ BO_ 2633938942 "Engine Speed/Load Factor Information";
CM_ SG_ 2633938942 TotalEngCruiseTime "Total time that the engine has operated in the cruise hold state, excluding time in accelerator override, over the life of the engine.";
CM_ SG_ 2633938942 TotalDriveAverageLoadFactor "Average engine load factor while engine speed is greater than zero, vehicle speed is greater than or equal to 2 km/h, and both the PTO (moving/non-moving) and remote PTO governors are not in the hold state, over the life of the engine.  Engine ...";
CM_ SG_ 2633938942 TripDriveAverageLoadFactor "Average engine load factor while engine speed is greater than zero, vehicle speed is greater than or equal to 2 km/h, and both the PTO (moving/non-moving) and remote PTO governors are not in the hold state, since the last trip reset.  Engine ...";
CM_ SG_ 2633938942 TripAverageEngSpeed "Average speed of the engine since the last trip reset.

NOTE � Excludes ignition-on time without the engine speed above zero.  Includes idle, engine PTO governor (moving and non-moving), and drive operation.";
CM_ SG_ 2633938942 TripMaxEngSpeed "Maximum engine speed achieved since the last trip reset.";
CM_ BO_ 2566799614 "Lighting Data
This lighting message is a response to the request for lighting data in the lighting command message.  Each lighting controller on the tractor and attached implements must transmit this message to the Tractor ECU when requested.  The ...";
CM_ SG_ 2566799614 ImplementRearWorkLight "This parameter provides measured data from the implement rear work lamps.

00 De-activated
01 Activated
10 Fault Detected
11 Not Available";
CM_ SG_ 2566799614 ImplementLeftFacingWorkLight "This parameter provides measured data from the left facing work lights toward the left end of the implement.

00 De-activated
01 Activated
10 Fault Detected
11 Not Available";
CM_ SG_ 2566799614 ImplementRightForwardWorkLight "This parameter provides measured data from the forward facing work lights toward the right end of the implement.

00 De-activated
01 Activated
10 Fault Detected
11 Not Available";
CM_ SG_ 2566799614 ImplementLeftForwardWorkLight "This parameter provides measured data from the work lights mounted on an implement to illuminate the forward left end of the implement.

00 De-activate
01 Activate
10 Fault Detected
11 Not Available";
CM_ SG_ 2566799614 ImplementRightFacingWorkLight "This parameter provides measured data from the work lights mounted on an implement to illuminate beyond right end of the implement.

00 De-activated
01 Activated
10 Fault Detected
11 Not Available";
CM_ SG_ 2566799614 ImplementOEMOption1Light "This parameter provides measured data from the implement OEM option 1 light.

00 De-activated
01 Activated
10 Fault Detected
11 Not Available";
CM_ SG_ 2566799614 ImplementOEMOption2Light "This parameter provides measured data from the implement OEM option 2 light.

00 De-activated
01 Activated
10 Fault Detected
11 Not Available";
CM_ SG_ 2566799614 TrctorFrontHighMountedWorkLights "This parameter provides measured data from the tractor front high mounted work lights. 

00 De-activated
01 Activated
10 Fault Detected
11 Not Available";
CM_ SG_ 2566799614 TractorFrontLowMountedWorkLights "This parameter provides measured data from the tractor front low mounted work lights. 

00 De-activated
01 Activated
10 Fault Detected
11 Not Available";
CM_ SG_ 2566799614 TractorSideHighMountedWorkLights "This parameter provides measured data from the tractor side high mounted work lights. 

00 De-activated
01 Activated
10 Fault Detected
11 Not Available";
CM_ SG_ 2566799614 TractorSideLowMountedWorkLights "This parameter provides measured data from the tractor side low mounted work lights. 

00 De-activated
01 Activated
10 Fault Detected
11 Not Available";
CM_ SG_ 2566799614 TractorRearHighMountedWorkLights "This parameter provides measured data from the tractor rear high mounted work lights. 

00 De-activated
01 Activated
10 Fault Detected
11 Not Available";
CM_ SG_ 2566799614 TractorRearLowMountedWorkLights "This parameter provides measured data from the tractor rear low mounted work lights.

00 De-activated
01 Activated
10 Fault Detected
11 Not Available";
CM_ SG_ 2566799614 TrctorUndersideMountedWorkLights "This parameter provides measured data from the tractor underside mounted work lights. 

00 De-activated
01 Activated
10 Fault Detected
11 Not Available";
CM_ SG_ 2566799614 RearFogLights "This parameter provides measured data from the tractor and/or implement rear fog lights.

00 De-activated
01 Activated
10 Fault Detected
11 Not Available";
CM_ SG_ 2566799614 TractorMarkerLight "This parameter provides measured data from the tractor and attached implement marker lights, including front position lights, rear tail lights, side running lights, license plate lights and instruments and switch back lights.
00 De-activated
01 ...";
CM_ SG_ 2566799614 ImplementMarkerLight "This parameter provides measured data from an attached implement marker lights, including front position lights, rear tail lights, side running lights, license plate lights and instruments and switch back lights.
00 De-activated
01 Activated
10 ...";
CM_ SG_ 2566799614 TractorClearanceLight "This parameter provides measured data from the tractor high mounted clearance and center ID lights.

00 De-activated
01 Activated
10 Fault Detected
11 Not Available";
CM_ SG_ 2566799614 ImplementClearanceLight "This parameter provides measured data from an attached implement high mounted clearance lights.

00 De-activated
01 Activated
10 Fault Detected
11 Not Available";
CM_ SG_ 2566799614 LeftStopLight "This parameter provides measured data from the tractor and attached implement left stop lights.

00 De-activated
01 Activated
10 Fault Detected
11 Not Available";
CM_ SG_ 2566799614 RightStopLight "This parameter provides measured data from the tractor and attached implement right stop lights.

00 De-activated
01 Activated
10 Fault Detected
11 Not Available";
CM_ SG_ 2566799614 CenterStopLight "This parameter provides measured data from the tractor and attached implement center stop lights.

00 De-activated
01 Activated
10 Fault Detected
11 Not Available";
CM_ SG_ 2566799614 BackUpLightAndAlarmHorn "This parameter provides measured data from the back up lights and/ or associated alarm.

00 De-activated
01 Activated
10 Fault Detected
11 Not Available";
CM_ SG_ 2566799614 LeftTurnSignalLights "This parameter provides measured data from the tractor and attached implement left turn signal lights.

00 De-activated
01 Activated
10 Fault Detected
11 Not Available";
CM_ SG_ 2566799614 RightTurnSignalLights "This parameter provides measured data from the tractor and attached implement right turn signal lights.

00 De-activated
01 Activated
10 Fault Detected
11 Not Available";
CM_ SG_ 2566799614 RotatingBeaconLight "This parameter provides measured data from the beacon light on tractor or attached implements.

00 De-activated
01 Activated
10 Fault Detected
11 Not Available";
CM_ SG_ 2566799614 TractorFrontFogLights "This parameter provides measured data from the tractor front fog lights.

00 De-activated
01 Activated
10 Fault Detected
11 Not Available";
CM_ SG_ 2566799614 HighBeamHeadLightData "This parameter provides measured data from the tractor high beam head light lamps. 

00 De-activated
01 Activated
10 Fault Detected
11 Not Available";
CM_ SG_ 2566799614 LowBeamHeadLightData "This parameter provides measured data from the tractor low beam head light lamps. 

00 De-activated
01 Activated
10 Fault Detected
11 Not Available";
CM_ SG_ 2566799614 AltBeamHeadLightData "This parameter provides measured data from the tractor alternate beam head light lamps. 

00 De-activated
01 Activated
10 Fault Detected
11 Not Available";
CM_ SG_ 2566799614 RunningLight "This parameter provides measured data from the vehicle뭩 running lights.

00 De-activated
01 Activated
10 Fault Detected
11 Not Available";
CM_ BO_ 2365473278 "Lighting Command
The lighting command message has been defined as a global message from the tractor to all lighting controllers on the tractor and attached implements.  Separate messages are provided for tractor and implement work and driving ...";
CM_ SG_ 2365473278 ImplementRearWorkLightCmd "Command to activate or de-activate implement rear work lights.  (This is also the same as Reversing Lights for truck applications.)  

00 De-activate
01 Activate
10 Reserved
11 Don뭪 Care";
CM_ SG_ 2365473278 ImplementLeftFacingWorkLightCmd "Command to activate or de-activate the left facing work lights toward the left end of the implement.

00 De-activate
01 Activate
10 Reserved
11 Don뭪 Care";
CM_ SG_ 2365473278 ImplmentRightForwardWorkLightCmd "Command to activate or de-activate the forward facing work lights toward the right end of the implement.

00 De-activate
01 Activate
10 Reserved
11 Don뭪 Care";
CM_ SG_ 2365473278 LightingDataRqCmd "Command to provide a response of the light state

00 De-activate
01 Activate
10 Reserved
11 Don뭪 Care";
CM_ SG_ 2365473278 ImplementLeftForwardWorkLightCmd "Command to activate or de-activate work lights mounted on an implement to illuminate beyond left end of the implement.

00 De-activate
01 Activate
10 Reserved
11 Don뭪 Care";
CM_ SG_ 2365473278 ImplementRightFacingWorkLightCmd "Command to activate or de-activate work lights mounted on an implement to illuminate beyond right end of the implement.

00 De-activate
01 Activate
10 Reserved
11 Don뭪 Care";
CM_ SG_ 2365473278 ImplementOEMOption1LightCmd "Command to activate or de-activate an implement OEM option 1 light.  This is provided to meet special needs on implements, such as tank inspection or filling lights.

00 De-activate
01 Activate
10 Reserved
11 Don뭪 Care";
CM_ SG_ 2365473278 ImplementOEMOption2LightCmd "Command to activate or de-activate an implement OEM option 2 light.  This is provided to meet special needs on implements, such as tank inspection or filling lights.

00 De-activate
01 Activate
10 Reserved
11 Don뭪 Care";
CM_ SG_ 2365473278 TrctrFrntHghMountedWorkLightsCmd "Command to activate or de-activate the tractor front high mounted work lights.

00 De-activate
01 Activate
10 Reserved
11 Don뭪 Care";
CM_ SG_ 2365473278 TrctrFrntLowMountedWorkLightsCmd "Command to activate or de-activate the tractor front low mounted work lights.

00 De-activate
01 Activate
10 Reserved
11 Don뭪 Care";
CM_ SG_ 2365473278 TrctrSdeHighMountedWorkLightsCmd "Command to activate or de-activate the tractor side high mounted work lights.

00 De-activate
01 Activate
10 Reserved
11 Don뭪 Care";
CM_ SG_ 2365473278 TrctrSideLowMountedWorkLightsCmd "Command to activate or de-activate the tractor side low mounted work lights.

00 De-activate
01 Activate
10 Reserved
11 Don뭪 Care";
CM_ SG_ 2365473278 TrctrRarHighMountedWorkLightsCmd "Command to activate or de-activate the tractor rear high  mounted work lights.

00 De-activate
01 Activate
10 Reserved
11 Don뭪 Care";
CM_ SG_ 2365473278 TrctrRearLowMountedWorkLightsCmd "Command to activate or de-activate the tractor rear low  mounted work lights.

00 De-activate
01 Activate
10 Reserved
11 Don뭪 Care";
CM_ SG_ 2365473278 TrctrUndrsdeMountedWorkLightsCmd "Command to activate or de-activate the tractor underside mounted work lights.

00 De-activate
01 Activate
10 Reserved
11 Don뭪 Care";
CM_ SG_ 2365473278 RearFogLightCmd "Command to activate or de-activate tractor or implement rear fog lights.  

00 De-activate
01 Activate
10 Reserved
11 Don뭪 Care";
CM_ SG_ 2365473278 TractorMarkerLightCmd "Command to activate or de-activate tractor and implement front position lights, rear red tail lights, side amber running lights, license plate lights and instrument and switch back lights.  

00 De-activate
01 Activate
10 Reserved
11 Don뭪 Care";
CM_ SG_ 2365473278 ImplementMarkerLightCmd "Command to activate or de-activate implement front position lights, rear red tail lights, side amber running lights, license plate lights and instrument and switch back lights.  

00 De-activate
01 Activate
10 Reserved
11 Don뭪 Care";
CM_ SG_ 2365473278 TractorClearanceLightCmd "Command to activate or de-activate the tractor high mounted clearance and center ID lights

00 De-activate
01 Activate
10 Reserved
11 Don뭪 Care";
CM_ SG_ 2365473278 ImplementClearanceLightCmd "Command to activate or de-activate the implement high mounted clearance and lights.  

00 De-activate
01 Activate
10 Reserved
11 Don뭪 Care";
CM_ SG_ 2365473278 LeftStopLightCmd "Command to activate or de-activate the tractor and implement left stop lights

00 De-activate
01 Activate
10 Reserved
11 Don뭪 Care";
CM_ SG_ 2365473278 RightStopLightCmd "Command to activate or de-activate the tractor and implement right stop light

00 De-activate
01 Activate
10 Reserved
11 Don뭪 Care";
CM_ SG_ 2365473278 CenterStopLightCmd "Command to activate or de-activate the tractor and implement center stop light

00 De-activate
01 Activate
10 Reserved
11 Don뭪 Care";
CM_ SG_ 2365473278 BackUpLightAndAlarmHornCmd "Command to activate or de-activate the back up lights and/ or associated alarm if required

00 De-activate
01 Activate
10 Reserved
11 Don뭪 Care";
CM_ SG_ 2365473278 LeftTurnSignalLightsCmd "Command to activate or de-activate left turn signal lights on the tractor and all connected implements

00 De-activate
01 Activate
10 Reserved
11 Don뭪 Care";
CM_ SG_ 2365473278 RightTurnSignalLightsCmd "Command to activate or de-activate right turn signal lights on the tractor and all connected implements

00 De-activate
01 Activate
10 Reserved
11 Don뭪 Care";
CM_ SG_ 2365473278 RotatingBeaconLightCmd "Command to activate or de-activate slow moving vehicle indicator lights on tractor and/or implements.  Activation of the slow moving vehicle lights implies that the controller should manipulate the lighting as appropriate to provide the slow moving ...";
CM_ SG_ 2365473278 TractorFrontFogLightsCmd "Command to activate or de-activate tractor front fog lights.

00 De-activate
01 Activate
10 Reserved
11 Don뭪 Care";
CM_ SG_ 2365473278 HighBeamHeadLightCmd "Command to activate or de-activate the tractor high beam head light lamps. 

00 De-activate
01 Activate
10 Reserved
11 Don뭪 Care";
CM_ SG_ 2365473278 LowBeamHeadLightCmd "Command to activate or de-activate the tractor low beam head light lamps. 

00 De-activate
01 Activate
10 Reserved
11 Don뭪 Care";
CM_ SG_ 2365473278 AltBeamHeadLightCmd "Command to activate or de-activate the tractor alternate head lights (only low beam is available on alternate head lights).  The alternate position lights are intended for use with loader and snow plows that tend to block the primary head lights.
 ...";
CM_ SG_ 2365473278 RunningLightCmd "Command to activate or de-activate the tractor or powered vehicle running lights.  Usually only used for on road vehicles.

00 De-activate
01 Activate
10 Reserved
11 Don뭪 Care";
BA_DEF_ SG_  "SigType" ENUM  "Default","Range","RangeSigned","ASCII","Discrete","Control","ReferencePGN","DTC","StringDelimiter","StringLength","StringLengthControl","MessageCounter","MessageChecksum";
BA_DEF_ SG_  "GenSigStartValue" INT 0 2147483647;
BA_DEF_ SG_  "GenSigSendType" ENUM  "Cyclic","OnWrite","OnWriteWithRepetition","OnChange","OnChangeWithRepetition","IfActive","IfActiveWithRepetition","NoSigSendType";
BA_DEF_ SG_  "GenSigILSupport" ENUM  "No","Yes";
BA_DEF_ SG_  "GenSigEVName" STRING ;
BA_DEF_ SG_  "SPN" INT 0 524287;
BA_DEF_ BO_  "TpJ1939VarDlc" ENUM  "No","Yes";
BA_DEF_ BO_  "GenMsgStartDelayTime" INT 0 100000;
BA_DEF_ BO_  "GenMsgILSupport" ENUM  "No","Yes";
BA_DEF_ BO_  "GenMsgDelayTime" INT 0 1000;
BA_DEF_ BO_  "GenMsgRequestable" INT 0 1;
BA_DEF_ BO_  "GenMsgSendType" ENUM  "cyclic","NotUsed","NotUsed","NotUsed","NotUsed","NotUsed","NotUsed","IfActive","noMsgSendType";
BA_DEF_ BO_  "VFrameFormat" ENUM  "StandardCAN","ExtendedCAN","reserved","J1939PG";
BA_DEF_ BO_  "GenMsgCycleTime" INT 0 3600000;
BA_DEF_ SG_  "SystemSignalLongSymbol" STRING ;
BA_DEF_DEF_  "SigType" "Default";
BA_DEF_DEF_  "GenSigStartValue" 0;
BA_DEF_DEF_  "GenSigSendType" "NoSigSendType";
BA_DEF_DEF_  "GenSigILSupport" "Yes";
BA_DEF_DEF_  "GenSigEVName" "Env@Nodename_@Signame";
BA_DEF_DEF_  "SPN" 0;
BA_DEF_DEF_  "TpJ1939VarDlc" "No";
BA_DEF_DEF_  "GenMsgStartDelayTime" 0;
BA_DEF_DEF_  "GenMsgILSupport" "Yes";
BA_DEF_DEF_  "GenMsgDelayTime" 0;
BA_DEF_DEF_  "GenMsgRequestable" 1;
BA_DEF_DEF_  "GenMsgSendType" "noMsgSendType";
BA_DEF_DEF_  "VFrameFormat" "J1939PG";
BA_DEF_DEF_  "GenMsgCycleTime" 0;
BA_DEF_DEF_  "SystemSignalLongSymbol" "";
BA_ "GenMsgCycleTime" BO_ 2365402110 100;
BA_ "GenMsgSendType" BO_ 2365402110 0;
BA_ "GenMsgDelayTime" BO_ 2365402110 20;
BA_ "GenMsgCycleTime" BO_ 2365402622 100;
BA_ "GenMsgSendType" BO_ 2365402622 0;
BA_ "GenMsgDelayTime" BO_ 2365402622 20;
BA_ "GenMsgCycleTime" BO_ 2365403134 100;
BA_ "GenMsgSendType" BO_ 2365403134 0;
BA_ "GenMsgDelayTime" BO_ 2365403134 20;
BA_ "GenMsgCycleTime" BO_ 2365400062 100;
BA_ "GenMsgSendType" BO_ 2365400062 0;
BA_ "GenMsgDelayTime" BO_ 2365400062 20;
BA_ "GenMsgCycleTime" BO_ 2566713598 500;
BA_ "GenMsgSendType" BO_ 2566713598 0;
BA_ "GenMsgCycleTime" BO_ 2499604478 500;
BA_ "GenMsgSendType" BO_ 2499604478 0;
BA_ "GenMsgCycleTime" BO_ 2499608830 500;
BA_ "GenMsgSendType" BO_ 2499608830 0;
BA_ "GenMsgCycleTime" BO_ 2432499198 100;
BA_ "GenMsgSendType" BO_ 2432499198 0;
BA_ "GenMsgCycleTime" BO_ 2566711294 5000;
BA_ "GenMsgSendType" BO_ 2566711294 0;
BA_ "GenMsgDelayTime" BO_ 2566711294 500;
BA_ "GenMsgCycleTime" BO_ 2566749438 1000;
BA_ "GenMsgSendType" BO_ 2566749438 0;
BA_ "GenMsgDelayTime" BO_ 2566749438 100;
BA_ "GenMsgCycleTime" BO_ 2566715646 1000;
BA_ "GenMsgSendType" BO_ 2566715646 0;
BA_ "GenMsgCycleTime" BO_ 2566724606 1000;
BA_ "GenMsgSendType" BO_ 2566724606 0;
BA_ "GenMsgCycleTime" BO_ 2566715902 1000;
BA_ "GenMsgSendType" BO_ 2566715902 0;
BA_ "GenMsgCycleTime" BO_ 2566724862 1000;
BA_ "GenMsgSendType" BO_ 2566724862 0;
BA_ "GenMsgCycleTime" BO_ 2566718718 1000;
BA_ "GenMsgSendType" BO_ 2566718718 0;
BA_ "GenMsgCycleTime" BO_ 2566718974 1000;
BA_ "GenMsgSendType" BO_ 2566718974 0;
BA_ "GenMsgCycleTime" BO_ 2566719230 1000;
BA_ "GenMsgSendType" BO_ 2566719230 0;
BA_ "GenMsgDelayTime" BO_ 2566719230 100;
BA_ "TpJ1939VarDlc" BO_ 2560818942 1;
BA_ "GenMsgCycleTime" BO_ 2566746366 1000;
BA_ "GenMsgDelayTime" BO_ 2566746366 100;
BA_ "GenMsgCycleTime" BO_ 2566755582 100;
BA_ "GenMsgSendType" BO_ 2566755582 0;
BA_ "GenMsgCycleTime" BO_ 2566752510 500;
BA_ "GenMsgSendType" BO_ 2566752510 0;
BA_ "GenMsgCycleTime" BO_ 2566752254 500;
BA_ "GenMsgSendType" BO_ 2566752254 0;
BA_ "GenMsgCycleTime" BO_ 2566751998 500;
BA_ "GenMsgSendType" BO_ 2566751998 0;
BA_ "GenMsgCycleTime" BO_ 2566751742 500;
BA_ "GenMsgSendType" BO_ 2566751742 0;
BA_ "GenMsgCycleTime" BO_ 2566751486 500;
BA_ "GenMsgSendType" BO_ 2566751486 0;
BA_ "GenMsgCycleTime" BO_ 2499641854 500;
BA_ "GenMsgSendType" BO_ 2499641854 0;
BA_ "GenMsgCycleTime" BO_ 2565873150 10;
BA_ "GenMsgSendType" BO_ 2565873150 0;
BA_ "GenMsgCycleTime" BO_ 2566751230 1000;
BA_ "GenMsgSendType" BO_ 2566751230 0;
BA_ "GenMsgDelayTime" BO_ 2566751230 100;
BA_ "GenMsgCycleTime" BO_ 2566755838 1000;
BA_ "GenMsgSendType" BO_ 2566755838 0;
BA_ "GenMsgCycleTime" BO_ 2365473278 1000;
BA_ "GenMsgSendType" BO_ 2365473278 0;
BA_ "GenMsgDelayTime" BO_ 2365473278 100;
BA_ "SPN" SG_ 2365402110 Joystick6Button13PressedStatus 6751;
BA_ "SigType" SG_ 2365402110 Joystick6Button13PressedStatus 4;
BA_ "SPN" SG_ 2365402110 Joystick6Button14PressedStatus 6752;
BA_ "SigType" SG_ 2365402110 Joystick6Button14PressedStatus 4;
BA_ "SPN" SG_ 2365402110 Joystick6Button15PressedStatus 6753;
BA_ "SigType" SG_ 2365402110 Joystick6Button15PressedStatus 4;
BA_ "SPN" SG_ 2365402110 Joystick6Button16PressedStatus 6754;
BA_ "SigType" SG_ 2365402110 Joystick6Button16PressedStatus 4;
BA_ "SPN" SG_ 2365402110 Jystick6GripXAxisDetentPosStatus 4601;
BA_ "SigType" SG_ 2365402110 Jystick6GripXAxisDetentPosStatus 4;
BA_ "SPN" SG_ 2365402110 Jystick6GripYAxisDetentPosStatus 4600;
BA_ "SigType" SG_ 2365402110 Jystick6GripYAxisDetentPosStatus 4;
BA_ "SPN" SG_ 2365402110 Jystick6ThetaAxisDetentPosStatus 4599;
BA_ "SigType" SG_ 2365402110 Jystick6ThetaAxisDetentPosStatus 4;
BA_ "SPN" SG_ 2365402110 Joystick6ThetaAxisPos 4598;
BA_ "SPN" SG_ 2365402110 Jystck6ThtAxsClckwsPstvPosStatus 4597;
BA_ "SigType" SG_ 2365402110 Jystck6ThtAxsClckwsPstvPosStatus 4;
BA_ "SPN" SG_ 2365402110 Jystck6ThtAxsCntrClckwsNgtvPsStt 4596;
BA_ "SigType" SG_ 2365402110 Jystck6ThtAxsCntrClckwsNgtvPsStt 4;
BA_ "SPN" SG_ 2365402110 Jystck6ThetaAxisNeutralPosStatus 4595;
BA_ "SigType" SG_ 2365402110 Jystck6ThetaAxisNeutralPosStatus 4;
BA_ "SPN" SG_ 2365402110 Joystick6GripYAxisPos 4594;
BA_ "SPN" SG_ 2365402110 Jystck6GrpYAxsLvrFrwrdPstvPsStts 4593;
BA_ "SigType" SG_ 2365402110 Jystck6GrpYAxsLvrFrwrdPstvPsStts 4;
BA_ "SPN" SG_ 2365402110 Jystck6GrpYAxsLvrBckNgtvPsStatus 4592;
BA_ "SigType" SG_ 2365402110 Jystck6GrpYAxsLvrBckNgtvPsStatus 4;
BA_ "SPN" SG_ 2365402110 Jystck6GripYAxisNeutralPosStatus 4591;
BA_ "SigType" SG_ 2365402110 Jystck6GripYAxisNeutralPosStatus 4;
BA_ "SPN" SG_ 2365402110 Joystick6GripXAxisPos 4590;
BA_ "SPN" SG_ 2365402110 Jystck6GrpXAxsLvrRghtPstvPsSttus 4589;
BA_ "SigType" SG_ 2365402110 Jystck6GrpXAxsLvrRghtPstvPsSttus 4;
BA_ "SPN" SG_ 2365402110 Jystck6GrpXAxsLvrLftNgtvPsStatus 4588;
BA_ "SigType" SG_ 2365402110 Jystck6GrpXAxsLvrLftNgtvPsStatus 4;
BA_ "SPN" SG_ 2365402110 Jystck6GripXAxisNeutralPosStatus 4587;
BA_ "SigType" SG_ 2365402110 Jystck6GripXAxisNeutralPosStatus 4;
BA_ "SPN" SG_ 2365402622 Joystick5Button13PressedStatus 6747;
BA_ "SigType" SG_ 2365402622 Joystick5Button13PressedStatus 4;
BA_ "SPN" SG_ 2365402622 Joystick5Button14PressedStatus 6748;
BA_ "SigType" SG_ 2365402622 Joystick5Button14PressedStatus 4;
BA_ "SPN" SG_ 2365402622 Joystick5Button15PressedStatus 6749;
BA_ "SigType" SG_ 2365402622 Joystick5Button15PressedStatus 4;
BA_ "SPN" SG_ 2365402622 Joystick5Button16PressedStatus 6750;
BA_ "SigType" SG_ 2365402622 Joystick5Button16PressedStatus 4;
BA_ "SPN" SG_ 2365402622 Jystick5GripXAxisDetentPosStatus 4564;
BA_ "SigType" SG_ 2365402622 Jystick5GripXAxisDetentPosStatus 4;
BA_ "SPN" SG_ 2365402622 Jystick5GripYAxisDetentPosStatus 4563;
BA_ "SigType" SG_ 2365402622 Jystick5GripYAxisDetentPosStatus 4;
BA_ "SPN" SG_ 2365402622 Jystick5ThetaAxisDetentPosStatus 4562;
BA_ "SigType" SG_ 2365402622 Jystick5ThetaAxisDetentPosStatus 4;
BA_ "SPN" SG_ 2365402622 Joystick5ThetaAxisPos 4561;
BA_ "SPN" SG_ 2365402622 Jystck5ThtAxsClckwsPstvPosStatus 4560;
BA_ "SigType" SG_ 2365402622 Jystck5ThtAxsClckwsPstvPosStatus 4;
BA_ "SPN" SG_ 2365402622 Jystck5ThtAxsCntrClckwsNgtvPsStt 4559;
BA_ "SigType" SG_ 2365402622 Jystck5ThtAxsCntrClckwsNgtvPsStt 4;
BA_ "SPN" SG_ 2365402622 Jystck5ThetaAxisNeutralPosStatus 4558;
BA_ "SigType" SG_ 2365402622 Jystck5ThetaAxisNeutralPosStatus 4;
BA_ "SPN" SG_ 2365402622 Joystick5GripYAxisPos 4557;
BA_ "SPN" SG_ 2365402622 Jystck5GrpYAxsLvrFrwrdPstvPsStts 4556;
BA_ "SigType" SG_ 2365402622 Jystck5GrpYAxsLvrFrwrdPstvPsStts 4;
BA_ "SPN" SG_ 2365402622 Jystck5GrpYAxsLvrBckNgtvPsStatus 4555;
BA_ "SigType" SG_ 2365402622 Jystck5GrpYAxsLvrBckNgtvPsStatus 4;
BA_ "SPN" SG_ 2365402622 Jystck5GripYAxisNeutralPosStatus 4554;
BA_ "SigType" SG_ 2365402622 Jystck5GripYAxisNeutralPosStatus 4;
BA_ "SPN" SG_ 2365402622 Joystick5GripXAxisPos 4553;
BA_ "SPN" SG_ 2365402622 Jystck5GrpXAxsLvrRghtPstvPsSttus 4552;
BA_ "SigType" SG_ 2365402622 Jystck5GrpXAxsLvrRghtPstvPsSttus 4;
BA_ "SPN" SG_ 2365402622 Jystck5GrpXAxsLvrLftNgtvPsStatus 4551;
BA_ "SigType" SG_ 2365402622 Jystck5GrpXAxsLvrLftNgtvPsStatus 4;
BA_ "SPN" SG_ 2365402622 Jystck5GripXAxisNeutralPosStatus 4550;
BA_ "SigType" SG_ 2365402622 Jystck5GripXAxisNeutralPosStatus 4;
BA_ "SPN" SG_ 2365403134 Joystick4Button13PressedStatus 6743;
BA_ "SigType" SG_ 2365403134 Joystick4Button13PressedStatus 4;
BA_ "SPN" SG_ 2365403134 Joystick4Button14PressedStatus 6744;
BA_ "SigType" SG_ 2365403134 Joystick4Button14PressedStatus 4;
BA_ "SPN" SG_ 2365403134 Joystick4Button15PressedStatus 6745;
BA_ "SigType" SG_ 2365403134 Joystick4Button15PressedStatus 4;
BA_ "SPN" SG_ 2365403134 Joystick4Button16PressedStatus 6746;
BA_ "SigType" SG_ 2365403134 Joystick4Button16PressedStatus 4;
BA_ "SPN" SG_ 2365403134 Jystick4GripXAxisDetentPosStatus 4527;
BA_ "SigType" SG_ 2365403134 Jystick4GripXAxisDetentPosStatus 4;
BA_ "SPN" SG_ 2365403134 Jystick4GripYAxisDetentPosStatus 4526;
BA_ "SigType" SG_ 2365403134 Jystick4GripYAxisDetentPosStatus 4;
BA_ "SPN" SG_ 2365403134 Jystick4ThetaAxisDetentPosStatus 4525;
BA_ "SigType" SG_ 2365403134 Jystick4ThetaAxisDetentPosStatus 4;
BA_ "SPN" SG_ 2365403134 Joystick4ThetaAxisPos 4524;
BA_ "SPN" SG_ 2365403134 Jystck4ThtAxsClckwsPstvPosStatus 4523;
BA_ "SigType" SG_ 2365403134 Jystck4ThtAxsClckwsPstvPosStatus 4;
BA_ "SPN" SG_ 2365403134 Jystck4ThtAxsCntrClckwsNgtvPsStt 4522;
BA_ "SigType" SG_ 2365403134 Jystck4ThtAxsCntrClckwsNgtvPsStt 4;
BA_ "SPN" SG_ 2365403134 Jystck4ThetaAxisNeutralPosStatus 4521;
BA_ "SigType" SG_ 2365403134 Jystck4ThetaAxisNeutralPosStatus 4;
BA_ "SPN" SG_ 2365403134 Joystick4GripYAxisPos 4520;
BA_ "SPN" SG_ 2365403134 Jystck4GrpYAxsLvrFrwrdPstvPsStts 4519;
BA_ "SigType" SG_ 2365403134 Jystck4GrpYAxsLvrFrwrdPstvPsStts 4;
BA_ "SPN" SG_ 2365403134 Jystck4GrpYAxsLvrBckNgtvPsStatus 4518;
BA_ "SigType" SG_ 2365403134 Jystck4GrpYAxsLvrBckNgtvPsStatus 4;
BA_ "SPN" SG_ 2365403134 Jystck4GripYAxisNeutralPosStatus 4517;
BA_ "SigType" SG_ 2365403134 Jystck4GripYAxisNeutralPosStatus 4;
BA_ "SPN" SG_ 2365403134 Joystick4GripXAxisPos 4516;
BA_ "SPN" SG_ 2365403134 Jystck4GrpXAxsLvrRghtPstvPsSttus 4515;
BA_ "SigType" SG_ 2365403134 Jystck4GrpXAxsLvrRghtPstvPsSttus 4;
BA_ "SPN" SG_ 2365403134 Jystck4GrpXAxsLvrLftNgtvPsStatus 4514;
BA_ "SigType" SG_ 2365403134 Jystck4GrpXAxsLvrLftNgtvPsStatus 4;
BA_ "SPN" SG_ 2365403134 Jystck4GripXAxisNeutralPosStatus 4513;
BA_ "SigType" SG_ 2365403134 Jystck4GripXAxisNeutralPosStatus 4;
BA_ "SPN" SG_ 2365400062 Joystick10Button13PressedStatus 6767;
BA_ "SigType" SG_ 2365400062 Joystick10Button13PressedStatus 4;
BA_ "SPN" SG_ 2365400062 Joystick10Button14PressedStatus 6768;
BA_ "SigType" SG_ 2365400062 Joystick10Button14PressedStatus 4;
BA_ "SPN" SG_ 2365400062 Joystick10Button15PressedStatus 6769;
BA_ "SigType" SG_ 2365400062 Joystick10Button15PressedStatus 4;
BA_ "SPN" SG_ 2365400062 Joystick10Button16PressedStatus 6770;
BA_ "SigType" SG_ 2365400062 Joystick10Button16PressedStatus 4;
BA_ "SPN" SG_ 2365400062 Jystck10GripXAxisDetentPosStatus 4749;
BA_ "SigType" SG_ 2365400062 Jystck10GripXAxisDetentPosStatus 4;
BA_ "SPN" SG_ 2365400062 Jystck10GripYAxisDetentPosStatus 4748;
BA_ "SigType" SG_ 2365400062 Jystck10GripYAxisDetentPosStatus 4;
BA_ "SPN" SG_ 2365400062 Jystck10ThetaAxisDetentPosStatus 4747;
BA_ "SigType" SG_ 2365400062 Jystck10ThetaAxisDetentPosStatus 4;
BA_ "SPN" SG_ 2365400062 Joystick10ThetaAxisPos 4746;
BA_ "SPN" SG_ 2365400062 Jystck10ThtAxsClckwsPstvPsStatus 4745;
BA_ "SigType" SG_ 2365400062 Jystck10ThtAxsClckwsPstvPsStatus 4;
BA_ "SPN" SG_ 2365400062 Jystck10ThtAxsCntrClckwsNgtvPsSt 4744;
BA_ "SigType" SG_ 2365400062 Jystck10ThtAxsCntrClckwsNgtvPsSt 4;
BA_ "SPN" SG_ 2365400062 Jystck10ThtaAxisNeutralPosStatus 4743;
BA_ "SigType" SG_ 2365400062 Jystck10ThtaAxisNeutralPosStatus 4;
BA_ "SPN" SG_ 2365400062 Joystick10GripYAxisPos 4742;
BA_ "SPN" SG_ 2365400062 Jystck10GrpYAxsLvrFrwrdPstvPsStt 4741;
BA_ "SigType" SG_ 2365400062 Jystck10GrpYAxsLvrFrwrdPstvPsStt 4;
BA_ "SPN" SG_ 2365400062 Jystck10GrpYAxsLvrBckNgtvPsSttus 4740;
BA_ "SigType" SG_ 2365400062 Jystck10GrpYAxsLvrBckNgtvPsSttus 4;
BA_ "SPN" SG_ 2365400062 Jystck10GrpYAxisNeutralPosStatus 4739;
BA_ "SigType" SG_ 2365400062 Jystck10GrpYAxisNeutralPosStatus 4;
BA_ "SPN" SG_ 2365400062 Joystick10GripXAxisPos 4738;
BA_ "SPN" SG_ 2365400062 Jystck10GrpXAxsLvrRghtPstvPsStts 4737;
BA_ "SigType" SG_ 2365400062 Jystck10GrpXAxsLvrRghtPstvPsStts 4;
BA_ "SPN" SG_ 2365400062 Jystck10GrpXAxsLvrLftNgtvPsSttus 4736;
BA_ "SigType" SG_ 2365400062 Jystck10GrpXAxsLvrLftNgtvPsSttus 4;
BA_ "SPN" SG_ 2365400062 Jystck10GrpXAxisNeutralPosStatus 4735;
BA_ "SigType" SG_ 2365400062 Jystck10GrpXAxisNeutralPosStatus 4;
BA_ "SPN" SG_ 2566713598 FuelPumpInOilPress 9648;
BA_ "SigType" SG_ 2566713598 FuelPumpInOilPress 1;
BA_ "SPN" SG_ 2566713598 FuelTankTransferPumpPress 7395;
BA_ "SigType" SG_ 2566713598 FuelTankTransferPumpPress 1;
BA_ "SPN" SG_ 2566713598 FuelTankTransferPump 4010;
BA_ "SigType" SG_ 2566713598 FuelTankTransferPump 4;
BA_ "SPN" SG_ 2566713598 EngFuelFilterDegradation 6716;
BA_ "SigType" SG_ 2566713598 EngFuelFilterDegradation 1;
BA_ "SPN" SG_ 2566713598 EngFuelFilterIntakeAbsPress 5417;
BA_ "SigType" SG_ 2566713598 EngFuelFilterIntakeAbsPress 1;
BA_ "SPN" SG_ 2499604478 EngFuelDeliveryPress 7469;
BA_ "SigType" SG_ 2499604478 EngFuelDeliveryPress 1;
BA_ "SPN" SG_ 2499604478 EngOilPress 7468;
BA_ "SigType" SG_ 2499604478 EngOilPress 1;
BA_ "SPN" SG_ 2499604478 EngExhstGsRcrcltn1OutletAbsPress 5431;
BA_ "SigType" SG_ 2499604478 EngExhstGsRcrcltn1OutletAbsPress 1;
BA_ "SPN" SG_ 2499604478 EngExhstGsRcrcltn1IntakeAbsPress 5430;
BA_ "SigType" SG_ 2499604478 EngExhstGsRcrcltn1IntakeAbsPress 1;
BA_ "SPN" SG_ 2499608830 EngCoolantPress2 5708;
BA_ "SigType" SG_ 2499608830 EngCoolantPress2 1;
BA_ "SPN" SG_ 2499608830 EngExhstGsRcrcltn2IntakeAbsPress 5429;
BA_ "SigType" SG_ 2499608830 EngExhstGsRcrcltn2IntakeAbsPress 1;
BA_ "SPN" SG_ 2499608830 EngExhstGsRcrcltn2OutletAbsPress 5254;
BA_ "SigType" SG_ 2499608830 EngExhstGsRcrcltn2OutletAbsPress 1;
BA_ "SPN" SG_ 2499608830 EngExhstGsRcrclation2IntakePress 5253;
BA_ "SigType" SG_ 2499608830 EngExhstGsRcrclation2IntakePress 1;
BA_ "SPN" SG_ 2499608830 EngExhstGsRcirculation2DiffPress 5252;
BA_ "SigType" SG_ 2499608830 EngExhstGsRcirculation2DiffPress 1;
BA_ "SPN" SG_ 2432499198 CmmndedEngFuelInjectionCtrlPress 5314;
BA_ "SigType" SG_ 2432499198 CmmndedEngFuelInjectionCtrlPress 1;
BA_ "SPN" SG_ 2432499198 CommandedEngFuelRailPress 5313;
BA_ "SigType" SG_ 2432499198 CommandedEngFuelRailPress 1;
BA_ "SPN" SG_ 2432499198 EngExhstGsRcirculation2Valve2Pos 5263;
BA_ "SigType" SG_ 2432499198 EngExhstGsRcirculation2Valve2Pos 1;
BA_ "SPN" SG_ 2432499198 EngExhstGsRecirculation2ValvePos 5262;
BA_ "SigType" SG_ 2432499198 EngExhstGsRecirculation2ValvePos 1;
BA_ "SPN" SG_ 2633825022 EngExhstGsRcrcltn2Valve2PosError 5832;
BA_ "SigType" SG_ 2633825022 EngExhstGsRcrcltn2Valve2PosError 1;
BA_ "SPN" SG_ 2633825022 EngExhstGsRcrcltn2Valve1PosError 5831;
BA_ "SigType" SG_ 2633825022 EngExhstGsRcrcltn2Valve1PosError 1;
BA_ "SPN" SG_ 2633825022 EngExhstGsRcrculation2Valve2Ctrl 5265;
BA_ "SigType" SG_ 2633825022 EngExhstGsRcrculation2Valve2Ctrl 1;
BA_ "SPN" SG_ 2633825022 EngExhstGsRcirculation2ValveCtrl 5264;
BA_ "SigType" SG_ 2633825022 EngExhstGsRcirculation2ValveCtrl 1;
BA_ "SPN" SG_ 2633826046 EGR2CoolerInPress 9380;
BA_ "SigType" SG_ 2633826046 EGR2CoolerInPress 1;
BA_ "SPN" SG_ 2633826046 EGR2CoolerBypassActuatorPos 5261;
BA_ "SigType" SG_ 2633826046 EGR2CoolerBypassActuatorPos 1;
BA_ "SPN" SG_ 2633826046 EngExhstGsRcrcltn2ClerEfficiency 5260;
BA_ "SigType" SG_ 2633826046 EngExhstGsRcrcltn2ClerEfficiency 1;
BA_ "SPN" SG_ 2633826046 EngExhstGsRcrcltn2ClrIntkGsAbsPr 5259;
BA_ "SigType" SG_ 2633826046 EngExhstGsRcrcltn2ClrIntkGsAbsPr 1;
BA_ "SPN" SG_ 2633826046 EngExhstGsRcrcltn2ClerIntakeTemp 5258;
BA_ "SigType" SG_ 2633826046 EngExhstGsRcrcltn2ClerIntakeTemp 1;
BA_ "SPN" SG_ 2566711294 EngFrictionPercentTorquePoint7 5477;
BA_ "GenSigStartValue" SG_ 2566711294 EngFrictionPercentTorquePoint7 125;
BA_ "SigType" SG_ 2566711294 EngFrictionPercentTorquePoint7 1;
BA_ "SPN" SG_ 2566711294 EngFrictionPercentTorquePoint6 5476;
BA_ "GenSigStartValue" SG_ 2566711294 EngFrictionPercentTorquePoint6 125;
BA_ "SigType" SG_ 2566711294 EngFrictionPercentTorquePoint6 1;
BA_ "SPN" SG_ 2566711294 EngFrictionPercentTorquePoint5 5475;
BA_ "GenSigStartValue" SG_ 2566711294 EngFrictionPercentTorquePoint5 125;
BA_ "SigType" SG_ 2566711294 EngFrictionPercentTorquePoint5 1;
BA_ "SPN" SG_ 2566711294 EngFrictionPercentTorquePoint4 5474;
BA_ "GenSigStartValue" SG_ 2566711294 EngFrictionPercentTorquePoint4 125;
BA_ "SigType" SG_ 2566711294 EngFrictionPercentTorquePoint4 1;
BA_ "SPN" SG_ 2566711294 EngFrictionPercentTorquePoint3 5473;
BA_ "GenSigStartValue" SG_ 2566711294 EngFrictionPercentTorquePoint3 125;
BA_ "SigType" SG_ 2566711294 EngFrictionPercentTorquePoint3 1;
BA_ "SPN" SG_ 2566711294 EngFrictionPercentTorquePoint2 5472;
BA_ "GenSigStartValue" SG_ 2566711294 EngFrictionPercentTorquePoint2 125;
BA_ "SigType" SG_ 2566711294 EngFrictionPercentTorquePoint2 1;
BA_ "SPN" SG_ 2566711294 EngFrctnPrcentTorqueAtIdlePoint1 5471;
BA_ "GenSigStartValue" SG_ 2566711294 EngFrctnPrcentTorqueAtIdlePoint1 125;
BA_ "SigType" SG_ 2566711294 EngFrctnPrcentTorqueAtIdlePoint1 1;
BA_ "SPN" SG_ 2566749438 ActiveRegenAvailabilityStatus 8857;
BA_ "SigType" SG_ 2566749438 ActiveRegenAvailabilityStatus 5;
BA_ "SPN" SG_ 2566749438 DslPrtcltFltrActvRgnrtnInhbt5629 5629;
BA_ "SigType" SG_ 2566749438 DslPrtcltFltrActvRgnrtnInhbt5629 5;
BA_ "SPN" SG_ 2566749438 AFT1DPFCondNotMetForActiveRegen 3750;
BA_ "SigType" SG_ 2566749438 AFT1DPFCondNotMetForActiveRegen 5;
BA_ "SPN" SG_ 2566749438 HydrocarbonDoserPurgingEnable 5504;
BA_ "SigType" SG_ 2566749438 HydrocarbonDoserPurgingEnable 5;
BA_ "SPN" SG_ 2566749438 DslPrtcltFltrActvRgnrtnFrcdSttus 4175;
BA_ "SPN" SG_ 2566749438 ExhaustSystemHighTempLampCmd 3698;
BA_ "SPN" SG_ 2566749438 DslPrtcltFltrAtmtcActvRgnrtnIntt 3718;
BA_ "SigType" SG_ 2566749438 DslPrtcltFltrAtmtcActvRgnrtnIntt 5;
BA_ "SPN" SG_ 2566749438 DslPrtcltFltrActvRgnrtnInhbt3717 3717;
BA_ "SigType" SG_ 2566749438 DslPrtcltFltrActvRgnrtnInhbt3717 5;
BA_ "SPN" SG_ 2566749438 DslPrtcltFltrActvRgnrtnInhbtdDTE 3716;
BA_ "SigType" SG_ 2566749438 DslPrtcltFltrActvRgnrtnInhbtdDTE 5;
BA_ "SPN" SG_ 2566749438 DslPrtcltFltrActvRgnrtnInhbt3715 3715;
BA_ "SigType" SG_ 2566749438 DslPrtcltFltrActvRgnrtnInhbt3715 4;
BA_ "SPN" SG_ 2566749438 DslPrtcltFltrActvRgnrtnInhbtdDTT 3714;
BA_ "SigType" SG_ 2566749438 DslPrtcltFltrActvRgnrtnInhbtdDTT 5;
BA_ "SPN" SG_ 2566749438 DslPrtcltFltrActvRgnrtnInhbt3713 3713;
BA_ "SigType" SG_ 2566749438 DslPrtcltFltrActvRgnrtnInhbt3713 5;
BA_ "SPN" SG_ 2566749438 DslPrtcltFltrActvRgnrtnInhbt3712 3712;
BA_ "SigType" SG_ 2566749438 DslPrtcltFltrActvRgnrtnInhbt3712 5;
BA_ "SPN" SG_ 2566749438 DslPrtcltFltrActvRgnrtnInhbtdDTL 3711;
BA_ "SigType" SG_ 2566749438 DslPrtcltFltrActvRgnrtnInhbtdDTL 4;
BA_ "SPN" SG_ 2566749438 DslPrtcltFltrActvRgnrtnInhbt3710 3710;
BA_ "SigType" SG_ 2566749438 DslPrtcltFltrActvRgnrtnInhbt3710 5;
BA_ "SPN" SG_ 2566749438 DslPrtcltFltrActvRgnrtnInhbtdDTV 3709;
BA_ "SigType" SG_ 2566749438 DslPrtcltFltrActvRgnrtnInhbtdDTV 5;
BA_ "SPN" SG_ 2566749438 DslPrtcltFltrActvRgnrtnInhbtdDTO 3708;
BA_ "SigType" SG_ 2566749438 DslPrtcltFltrActvRgnrtnInhbtdDTO 5;
BA_ "SPN" SG_ 2566749438 DslPrtcltFltrActvRgnrtnInhbtdDTA 3707;
BA_ "SigType" SG_ 2566749438 DslPrtcltFltrActvRgnrtnInhbtdDTA 5;
BA_ "SPN" SG_ 2566749438 DslPrtcltFltrActvRgnrtnInhbtdDTP 3706;
BA_ "SigType" SG_ 2566749438 DslPrtcltFltrActvRgnrtnInhbtdDTP 5;
BA_ "SPN" SG_ 2566749438 DslPrtcltFltrActvRgnrtnInhbtdDTS 3705;
BA_ "SigType" SG_ 2566749438 DslPrtcltFltrActvRgnrtnInhbtdDTS 5;
BA_ "SPN" SG_ 2566749438 DslPrtcltFltrActvRgnrtnInhbtdDTC 3704;
BA_ "SigType" SG_ 2566749438 DslPrtcltFltrActvRgnrtnInhbtdDTC 5;
BA_ "SPN" SG_ 2566749438 DslPrtcltFltrActvRgnrtnInhbtdDTI 3703;
BA_ "SigType" SG_ 2566749438 DslPrtcltFltrActvRgnrtnInhbtdDTI 5;
BA_ "SPN" SG_ 2566749438 DslPrtcltFltrActvRgnrtnInhbtdStt 3702;
BA_ "SigType" SG_ 2566749438 DslPrtcltFltrActvRgnrtnInhbtdStt 5;
BA_ "SPN" SG_ 2566749438 AFTDPFStatus 3701;
BA_ "SPN" SG_ 2566749438 AFTDPFActiveRegenStatus 3700;
BA_ "SigType" SG_ 2566749438 AFTDPFActiveRegenStatus 5;
BA_ "SPN" SG_ 2566749438 AFTDPFPassiveRegenStatus 3699;
BA_ "SigType" SG_ 2566749438 AFTDPFPassiveRegenStatus 5;
BA_ "SPN" SG_ 2566749438 DieselParticulateFilterLampCmd 3697;
BA_ "SPN" SG_ 2566715646 AFT2DPFSootSignalMin 5271;
BA_ "SigType" SG_ 2566715646 AFT2DPFSootSignalMin 1;
BA_ "SPN" SG_ 2566715646 AFT2DPFSootSignalMax 5270;
BA_ "SigType" SG_ 2566715646 AFT2DPFSootSignalMax 1;
BA_ "SPN" SG_ 2566715646 AFT2DPFSootSignalStdDeviation 5269;
BA_ "SigType" SG_ 2566715646 AFT2DPFSootSignalStdDeviation 1;
BA_ "SPN" SG_ 2566724606 DslPrtcltFltr2StSnsrECUIntrnlTmp 5570;
BA_ "SigType" SG_ 2566724606 DslPrtcltFltr2StSnsrECUIntrnlTmp 1;
BA_ "SPN" SG_ 2566724606 AFT2DPFSootSnsrPreliminaryFMI 4790;
BA_ "SPN" SG_ 2566724606 AFT2DPFMedianSootSignal 4789;
BA_ "SigType" SG_ 2566724606 AFT2DPFMedianSootSignal 1;
BA_ "SPN" SG_ 2566724606 AFT2DPFMeanSootSignal 4788;
BA_ "SigType" SG_ 2566724606 AFT2DPFMeanSootSignal 1;
BA_ "SPN" SG_ 2566724606 AFT2DPFSootDensity 4787;
BA_ "SigType" SG_ 2566724606 AFT2DPFSootDensity 1;
BA_ "SPN" SG_ 2566724606 AFT2DPFSootMass 4786;
BA_ "SigType" SG_ 2566724606 AFT2DPFSootMass 1;
BA_ "SPN" SG_ 2566715902 AFT1DPFSootSignalMin 5268;
BA_ "SigType" SG_ 2566715902 AFT1DPFSootSignalMin 1;
BA_ "SPN" SG_ 2566715902 AFT1DPFSootSignalMax 5267;
BA_ "SigType" SG_ 2566715902 AFT1DPFSootSignalMax 1;
BA_ "SPN" SG_ 2566715902 AFT1DPFSootSignalStdDeviation 5266;
BA_ "SigType" SG_ 2566715902 AFT1DPFSootSignalStdDeviation 1;
BA_ "SPN" SG_ 2566724862 DslPrtcltFltr1StSnsrECUIntrnlTmp 5569;
BA_ "SigType" SG_ 2566724862 DslPrtcltFltr1StSnsrECUIntrnlTmp 1;
BA_ "SPN" SG_ 2566724862 AFT1DPFSootSnsrPreliminaryFMI 4785;
BA_ "SPN" SG_ 2566724862 AFT1DPFMedianSootSignal 4784;
BA_ "SigType" SG_ 2566724862 AFT1DPFMedianSootSignal 1;
BA_ "SPN" SG_ 2566724862 AFT1DPFMeanSootSignal 4783;
BA_ "SigType" SG_ 2566724862 AFT1DPFMeanSootSignal 1;
BA_ "SPN" SG_ 2566724862 AFT1DPFSootDensity 4782;
BA_ "SigType" SG_ 2566724862 AFT1DPFSootDensity 1;
BA_ "SPN" SG_ 2566724862 AFT1DPFSootMass 4781;
BA_ "SigType" SG_ 2566724862 AFT1DPFSootMass 1;
BA_ "SPN" SG_ 2566718718 HillHolderLampData 1848;
BA_ "SigType" SG_ 2566718718 HillHolderLampData 5;
BA_ "SPN" SG_ 2566718718 VehicleBatteryChargingLampData 5108;
BA_ "SigType" SG_ 2566718718 VehicleBatteryChargingLampData 4;
BA_ "SPN" SG_ 2566718718 VehicleHVACRecirculationLampData 5107;
BA_ "SigType" SG_ 2566718718 VehicleHVACRecirculationLampData 4;
BA_ "SPN" SG_ 2566718718 VehicleAirPressLowLampData 5106;
BA_ "SigType" SG_ 2566718718 VehicleAirPressLowLampData 4;
BA_ "SPN" SG_ 2566718718 VehicleFuelLevelLowLampData 5105;
BA_ "SigType" SG_ 2566718718 VehicleFuelLevelLowLampData 4;
BA_ "SPN" SG_ 2566718718 VehicleBatteryVoltageLowLampData 5104;
BA_ "SigType" SG_ 2566718718 VehicleBatteryVoltageLowLampData 4;
BA_ "SPN" SG_ 2566718974 EngStopStartEnabledLamp 9682;
BA_ "SigType" SG_ 2566718974 EngStopStartEnabledLamp 4;
BA_ "SPN" SG_ 2566718974 EngStopStartAutoStartFailedLamp 9681;
BA_ "SigType" SG_ 2566718974 EngStopStartAutoStartFailedLamp 4;
BA_ "SPN" SG_ 2566718974 EngStopStartAutoStopActiveLamp 9680;
BA_ "SigType" SG_ 2566718974 EngStopStartAutoStopActiveLamp 4;
BA_ "SPN" SG_ 2566718974 VhclAcclerationRateLimitLampData 6900;
BA_ "SigType" SG_ 2566718974 VhclAcclerationRateLimitLampData 4;
BA_ "SPN" SG_ 2566718974 EngSpeedVeryHighLampData 6712;
BA_ "SigType" SG_ 2566718974 EngSpeedVeryHighLampData 5;
BA_ "SPN" SG_ 2566718974 EngSpeedHighLampData 6711;
BA_ "SigType" SG_ 2566718974 EngSpeedHighLampData 5;
BA_ "SPN" SG_ 2566718974 EngCtrlMdule3ReadyForUseLampData 6204;
BA_ "SigType" SG_ 2566718974 EngCtrlMdule3ReadyForUseLampData 4;
BA_ "SPN" SG_ 2566718974 EngCtrlMdule2ReadyForUseLampData 6203;
BA_ "SigType" SG_ 2566718974 EngCtrlMdule2ReadyForUseLampData 4;
BA_ "SPN" SG_ 2566718974 EngCtrlMdule1ReadyForUseLampData 6202;
BA_ "SigType" SG_ 2566718974 EngCtrlMdule1ReadyForUseLampData 4;
BA_ "SPN" SG_ 2566718974 EngWaitToStartLampData 5416;
BA_ "SigType" SG_ 2566718974 EngWaitToStartLampData 4;
BA_ "SPN" SG_ 2566718974 EngFuelFilterRestrictedLampData 5470;
BA_ "SigType" SG_ 2566718974 EngFuelFilterRestrictedLampData 5;
BA_ "SPN" SG_ 2566718974 EngAirFilterRestrictionLampData 5103;
BA_ "SigType" SG_ 2566718974 EngAirFilterRestrictionLampData 4;
BA_ "SPN" SG_ 2566718974 EngIdleManagementActiveLampData 5102;
BA_ "SigType" SG_ 2566718974 EngIdleManagementActiveLampData 4;
BA_ "SPN" SG_ 2566718974 EngCoolantLevelLowLampData 5101;
BA_ "SigType" SG_ 2566718974 EngCoolantLevelLowLampData 4;
BA_ "SPN" SG_ 2566718974 EngCoolantTempHighLampData 5100;
BA_ "SigType" SG_ 2566718974 EngCoolantTempHighLampData 4;
BA_ "SPN" SG_ 2566718974 EngOilPressLowLampData 5099;
BA_ "SigType" SG_ 2566718974 EngOilPressLowLampData 4;
BA_ "SPN" SG_ 2566718974 CmprssnBrkEnblSwtchIndctrLmpData 5098;
BA_ "SigType" SG_ 2566718974 CmprssnBrkEnblSwtchIndctrLmpData 4;
BA_ "SPN" SG_ 2566718974 EngBrakeActiveLampData 5097;
BA_ "SigType" SG_ 2566718974 EngBrakeActiveLampData 4;
BA_ "SPN" SG_ 2566718974 OBDMalfunctionIndicatorLampData 5096;
BA_ "SigType" SG_ 2566718974 OBDMalfunctionIndicatorLampData 4;
BA_ "SPN" SG_ 2566718974 EngRedStopLampData 5095;
BA_ "SigType" SG_ 2566718974 EngRedStopLampData 4;
BA_ "SPN" SG_ 2566718974 EngAmberWarningLampData 5094;
BA_ "SigType" SG_ 2566718974 EngAmberWarningLampData 4;
BA_ "SPN" SG_ 2566718974 EngProtectLampData 5093;
BA_ "SigType" SG_ 2566718974 EngProtectLampData 4;
BA_ "SPN" SG_ 2566719230 HillHolderLampCmd 1847;
BA_ "SigType" SG_ 2566719230 HillHolderLampCmd 5;
BA_ "SPN" SG_ 2566719230 VehicleBatteryChargingLampCmd 5091;
BA_ "SigType" SG_ 2566719230 VehicleBatteryChargingLampCmd 5;
BA_ "SPN" SG_ 2566719230 VehicleHVACRecirculationLampCmd 5090;
BA_ "SigType" SG_ 2566719230 VehicleHVACRecirculationLampCmd 5;
BA_ "SPN" SG_ 2566719230 VehicleAirPressLowLampCmd 5089;
BA_ "SigType" SG_ 2566719230 VehicleAirPressLowLampCmd 5;
BA_ "SPN" SG_ 2566719230 VehicleFuelLevelLowLampCmd 5088;
BA_ "SigType" SG_ 2566719230 VehicleFuelLevelLowLampCmd 5;
BA_ "SPN" SG_ 2566719230 VehicleBatteryVoltageLowLampCmd 5087;
BA_ "SigType" SG_ 2566719230 VehicleBatteryVoltageLowLampCmd 5;
BA_ "SPN" SG_ 2560818942 SPN1 1214;
BA_ "SPN" SG_ 2560818942 FailureModeIdentifier1 1215;
BA_ "SPN" SG_ 2560818942 DTCTimeUntilDerate 4123;
BA_ "SigType" SG_ 2560818942 DTCTimeUntilDerate 1;
BA_ "SPN" SG_ 2560818942 DTCTotalPreviouslyActiveTime 4122;
BA_ "SigType" SG_ 2560818942 DTCTotalPreviouslyActiveTime 1;
BA_ "SPN" SG_ 2560818942 DTCTotalActiveTime 4121;
BA_ "SigType" SG_ 2560818942 DTCTotalActiveTime 1;
BA_ "SPN" SG_ 2561212158 TextDisplayIndex 3614;
BA_ "SigType" SG_ 2561212158 TextDisplayIndex 1;
BA_ "SPN" SG_ 2561212158 TextDisplayInstructions 3613;
BA_ "SPN" SG_ 2566746366 RetractStatusOfRamp5 4457;
BA_ "SigType" SG_ 2566746366 RetractStatusOfRamp5 5;
BA_ "SPN" SG_ 2566746366 RetractStatusOfRamp4 4454;
BA_ "SigType" SG_ 2566746366 RetractStatusOfRamp4 5;
BA_ "SPN" SG_ 2566746366 MovementStatusOfRamp5 4459;
BA_ "SigType" SG_ 2566746366 MovementStatusOfRamp5 5;
BA_ "SPN" SG_ 2566746366 MovementStatusOfRamp4 4456;
BA_ "SigType" SG_ 2566746366 MovementStatusOfRamp4 5;
BA_ "SPN" SG_ 2566746366 EnableStatusOfRamp5 4458;
BA_ "SigType" SG_ 2566746366 EnableStatusOfRamp5 5;
BA_ "SPN" SG_ 2566746366 EnableStatusOfRamp4 4455;
BA_ "SigType" SG_ 2566746366 EnableStatusOfRamp4 5;
BA_ "SPN" SG_ 2566746366 MovementStatusOfRamp3 3818;
BA_ "SigType" SG_ 2566746366 MovementStatusOfRamp3 5;
BA_ "SPN" SG_ 2566746366 EnableStatusOfRamp3 3817;
BA_ "SigType" SG_ 2566746366 EnableStatusOfRamp3 5;
BA_ "SPN" SG_ 2566746366 RetractStatusOfRamp3 3816;
BA_ "SigType" SG_ 2566746366 RetractStatusOfRamp3 5;
BA_ "SPN" SG_ 2566746366 MovementStatusOfRamp2 3815;
BA_ "SigType" SG_ 2566746366 MovementStatusOfRamp2 5;
BA_ "SPN" SG_ 2566746366 EnableStatusOfRamp2 3814;
BA_ "SigType" SG_ 2566746366 EnableStatusOfRamp2 5;
BA_ "SPN" SG_ 2566746366 RetractStatusOfRamp2 3813;
BA_ "SigType" SG_ 2566746366 RetractStatusOfRamp2 5;
BA_ "SPN" SG_ 2566746366 MovementStatusOfRamp1 3812;
BA_ "SigType" SG_ 2566746366 MovementStatusOfRamp1 5;
BA_ "SPN" SG_ 2566746366 EnableStatusOfRamp1 3811;
BA_ "SigType" SG_ 2566746366 EnableStatusOfRamp1 5;
BA_ "SPN" SG_ 2566746366 RetractStatusOfRamp1 3810;
BA_ "SigType" SG_ 2566746366 RetractStatusOfRamp1 5;
BA_ "SPN" SG_ 2566750206 TransIdleGovFuelingInhSupport 7830;
BA_ "SigType" SG_ 2566750206 TransIdleGovFuelingInhSupport 4;
BA_ "SPN" SG_ 2566750206 EngConfigIdentification 6395;
BA_ "SigType" SG_ 2566750206 EngConfigIdentification 1;
BA_ "SPN" SG_ 2566750206 NmbrOfCmbstionCyclesForAveraging 6394;
BA_ "GenSigStartValue" SG_ 2566750206 NmbrOfCmbstionCyclesForAveraging 1;
BA_ "SigType" SG_ 2566750206 NmbrOfCmbstionCyclesForAveraging 1;
BA_ "SPN" SG_ 2566750206 MaxCrankAttemptsPerStartAttempt 3670;
BA_ "SigType" SG_ 2566750206 MaxCrankAttemptsPerStartAttempt 1;
BA_ "SPN" SG_ 2566755582 CommandedEngIntakeManifoldPress 5312;
BA_ "SigType" SG_ 2566755582 CommandedEngIntakeManifoldPress 1;
BA_ "SPN" SG_ 2566755582 EngCrnkcsBrtherOilSeparatorSpeed 5444;
BA_ "SigType" SG_ 2566755582 EngCrnkcsBrtherOilSeparatorSpeed 1;
BA_ "SPN" SG_ 2566755582 EngExhstGsRcirculation1Valve2Pos 3822;
BA_ "SigType" SG_ 2566755582 EngExhstGsRcirculation1Valve2Pos 1;
BA_ "SPN" SG_ 2566755582 EngExhstGsRecirculation1ValvePos 27;
BA_ "SigType" SG_ 2566755582 EngExhstGsRecirculation1ValvePos 1;
BA_ "SPN" SG_ 2566746110 EngExhstGsRcrcltn1ClerEfficiency 4752;
BA_ "SigType" SG_ 2566746110 EngExhstGsRcrcltn1ClerEfficiency 1;
BA_ "SPN" SG_ 2566746110 EngExhstGsRcrcltn1ClrIntkGsAbsPr 4751;
BA_ "SigType" SG_ 2566746110 EngExhstGsRcrcltn1ClrIntkGsAbsPr 1;
BA_ "SPN" SG_ 2566746110 EngExhstGsRcrcltn1ClerIntakeTemp 4750;
BA_ "SigType" SG_ 2566746110 EngExhstGsRcrcltn1ClerIntakeTemp 1;
BA_ "SPN" SG_ 2566746110 EngExhstGsRcrculation1Valve2Ctrl 3821;
BA_ "SigType" SG_ 2566746110 EngExhstGsRcrculation1Valve2Ctrl 1;
BA_ "SPN" SG_ 2566752510 EngIntkVlvActtionOilPressForCyl4 3627;
BA_ "SigType" SG_ 2566752510 EngIntkVlvActtionOilPressForCyl4 1;
BA_ "SPN" SG_ 2566752510 EngIntkVlvActtionOilPressForCyl3 3626;
BA_ "SigType" SG_ 2566752510 EngIntkVlvActtionOilPressForCyl3 1;
BA_ "SPN" SG_ 2566752510 EngIntkVlvActtionOilPressForCyl2 3625;
BA_ "SigType" SG_ 2566752510 EngIntkVlvActtionOilPressForCyl2 1;
BA_ "SPN" SG_ 2566752510 EngIntkVlvActtionOilPressForCyl1 3624;
BA_ "SigType" SG_ 2566752510 EngIntkVlvActtionOilPressForCyl1 1;
BA_ "SPN" SG_ 2566752254 EngIntkVlvActtionOilPressForCyl8 3631;
BA_ "SigType" SG_ 2566752254 EngIntkVlvActtionOilPressForCyl8 1;
BA_ "SPN" SG_ 2566752254 EngIntkVlvActtionOilPressForCyl7 3630;
BA_ "SigType" SG_ 2566752254 EngIntkVlvActtionOilPressForCyl7 1;
BA_ "SPN" SG_ 2566752254 EngIntkVlvActtionOilPressForCyl6 3629;
BA_ "SigType" SG_ 2566752254 EngIntkVlvActtionOilPressForCyl6 1;
BA_ "SPN" SG_ 2566752254 EngIntkVlvActtionOilPressForCyl5 3628;
BA_ "SigType" SG_ 2566752254 EngIntkVlvActtionOilPressForCyl5 1;
BA_ "SPN" SG_ 2566751998 EngIntkVlvActtonOilPressForCyl12 3635;
BA_ "SigType" SG_ 2566751998 EngIntkVlvActtonOilPressForCyl12 1;
BA_ "SPN" SG_ 2566751998 EngIntkVlvActtonOilPressForCyl11 3634;
BA_ "SigType" SG_ 2566751998 EngIntkVlvActtonOilPressForCyl11 1;
BA_ "SPN" SG_ 2566751998 EngIntkVlvActtonOilPressForCyl10 3633;
BA_ "SigType" SG_ 2566751998 EngIntkVlvActtonOilPressForCyl10 1;
BA_ "SPN" SG_ 2566751998 EngIntkVlvActtionOilPressForCyl9 3632;
BA_ "SigType" SG_ 2566751998 EngIntkVlvActtionOilPressForCyl9 1;
BA_ "SPN" SG_ 2566751742 EngIntkVlvActtonOilPressForCyl16 3639;
BA_ "SigType" SG_ 2566751742 EngIntkVlvActtonOilPressForCyl16 1;
BA_ "SPN" SG_ 2566751742 EngIntkVlvActtonOilPressForCyl15 3638;
BA_ "SigType" SG_ 2566751742 EngIntkVlvActtonOilPressForCyl15 1;
BA_ "SPN" SG_ 2566751742 EngIntkVlvActtonOilPressForCyl14 3637;
BA_ "SigType" SG_ 2566751742 EngIntkVlvActtonOilPressForCyl14 1;
BA_ "SPN" SG_ 2566751742 EngIntkVlvActtonOilPressForCyl13 3636;
BA_ "SigType" SG_ 2566751742 EngIntkVlvActtonOilPressForCyl13 1;
BA_ "SPN" SG_ 2566751486 EngIntkVlvActtonOilPressForCyl20 3643;
BA_ "SigType" SG_ 2566751486 EngIntkVlvActtonOilPressForCyl20 1;
BA_ "SPN" SG_ 2566751486 EngIntkVlvActtonOilPressForCyl19 3642;
BA_ "SigType" SG_ 2566751486 EngIntkVlvActtonOilPressForCyl19 1;
BA_ "SPN" SG_ 2566751486 EngIntkVlvActtonOilPressForCyl18 3641;
BA_ "SigType" SG_ 2566751486 EngIntkVlvActtonOilPressForCyl18 1;
BA_ "SPN" SG_ 2566751486 EngIntkVlvActtonOilPressForCyl17 3640;
BA_ "SigType" SG_ 2566751486 EngIntkVlvActtonOilPressForCyl17 1;
BA_ "SPN" SG_ 2499641854 EGR1CoolerBypassActuatorPostion 3672;
BA_ "SigType" SG_ 2499641854 EGR1CoolerBypassActuatorPostion 1;
BA_ "SPN" SG_ 2566748158 EngSparkPlug4 1297;
BA_ "SigType" SG_ 2566748158 EngSparkPlug4 1;
BA_ "SPN" SG_ 2566748158 EngSparkPlug3 1296;
BA_ "SigType" SG_ 2566748158 EngSparkPlug3 1;
BA_ "SPN" SG_ 2566748158 EngSparkPlug2 1295;
BA_ "SigType" SG_ 2566748158 EngSparkPlug2 1;
BA_ "SPN" SG_ 2566748158 EngSparkPlug1 1294;
BA_ "SigType" SG_ 2566748158 EngSparkPlug1 1;
BA_ "SPN" SG_ 2566747902 EngSparkPlug8 1301;
BA_ "SigType" SG_ 2566747902 EngSparkPlug8 1;
BA_ "SPN" SG_ 2566747902 EngSparkPlug7 1300;
BA_ "SigType" SG_ 2566747902 EngSparkPlug7 1;
BA_ "SPN" SG_ 2566747902 EngSparkPlug6 1299;
BA_ "SigType" SG_ 2566747902 EngSparkPlug6 1;
BA_ "SPN" SG_ 2566747902 EngSparkPlug5 1298;
BA_ "SigType" SG_ 2566747902 EngSparkPlug5 1;
BA_ "SPN" SG_ 2566747646 EngSparkPlug12 1305;
BA_ "SigType" SG_ 2566747646 EngSparkPlug12 1;
BA_ "SPN" SG_ 2566747646 EngSparkPlug11 1304;
BA_ "SigType" SG_ 2566747646 EngSparkPlug11 1;
BA_ "SPN" SG_ 2566747646 EngSparkPlug10 1303;
BA_ "SigType" SG_ 2566747646 EngSparkPlug10 1;
BA_ "SPN" SG_ 2566747646 EngSparkPlug9 1302;
BA_ "SigType" SG_ 2566747646 EngSparkPlug9 1;
BA_ "SPN" SG_ 2566747390 EngSparkPlug16 1309;
BA_ "SigType" SG_ 2566747390 EngSparkPlug16 1;
BA_ "SPN" SG_ 2566747390 EngSparkPlug15 1308;
BA_ "SigType" SG_ 2566747390 EngSparkPlug15 1;
BA_ "SPN" SG_ 2566747390 EngSparkPlug14 1307;
BA_ "SigType" SG_ 2566747390 EngSparkPlug14 1;
BA_ "SPN" SG_ 2566747390 EngSparkPlug13 1306;
BA_ "SigType" SG_ 2566747390 EngSparkPlug13 1;
BA_ "SPN" SG_ 2566747134 EngSparkPlug20 1313;
BA_ "SigType" SG_ 2566747134 EngSparkPlug20 1;
BA_ "SPN" SG_ 2566747134 EngSparkPlug19 1312;
BA_ "SigType" SG_ 2566747134 EngSparkPlug19 1;
BA_ "SPN" SG_ 2566747134 EngSparkPlug18 1311;
BA_ "SigType" SG_ 2566747134 EngSparkPlug18 1;
BA_ "SPN" SG_ 2566747134 EngSparkPlug17 1310;
BA_ "SigType" SG_ 2566747134 EngSparkPlug17 1;
BA_ "SPN" SG_ 2566746878 EngSparkPlug24 1317;
BA_ "SigType" SG_ 2566746878 EngSparkPlug24 1;
BA_ "SPN" SG_ 2566746878 EngSparkPlug23 1316;
BA_ "SigType" SG_ 2566746878 EngSparkPlug23 1;
BA_ "SPN" SG_ 2566746878 EngSparkPlug22 1315;
BA_ "SigType" SG_ 2566746878 EngSparkPlug22 1;
BA_ "SPN" SG_ 2566746878 EngSparkPlug21 1314;
BA_ "SigType" SG_ 2566746878 EngSparkPlug21 1;
BA_ "SPN" SG_ 2561277694 ReqActiveSteerDriverPrefMode 9760;
BA_ "SPN" SG_ 2561277694 CenteringEnableCmd 9752;
BA_ "SigType" SG_ 2561277694 CenteringEnableCmd 5;
BA_ "SPN" SG_ 2561277694 KeepingAssistEnableCmd 9751;
BA_ "SigType" SG_ 2561277694 KeepingAssistEnableCmd 5;
BA_ "SPN" SG_ 2561277694 CurSubRegion 8134;
BA_ "SPN" SG_ 2561277694 CurRegion 8133;
BA_ "SigType" SG_ 2561277694 CurRegion 1;
BA_ "SPN" SG_ 2561277694 LaneDepartureWarningEnableCmd 3564;
BA_ "SigType" SG_ 2561277694 LaneDepartureWarningEnableCmd 5;
BA_ "SPN" SG_ 2633861886 J2012DTCOccurrenceCount 3622;
BA_ "SPN" SG_ 2633861886 J2012DTCStatus 3621;
BA_ "SPN" SG_ 2633861886 J2012DTC 3620;
BA_ "SPN" SG_ 2633861886 NumberOfJ2012DTCs 3619;
BA_ "SigType" SG_ 2633861886 NumberOfJ2012DTCs 1;
BA_ "SPN" SG_ 2565873150 MessageChecksum 3690;
BA_ "SigType" SG_ 2565873150 MessageChecksum 12;
BA_ "SPN" SG_ 2565873150 MessageCounter 3689;
BA_ "SigType" SG_ 2565873150 MessageCounter 11;
BA_ "SPN" SG_ 2565873150 SteerAngleSensorCalibrated 3688;
BA_ "SigType" SG_ 2565873150 SteerAngleSensorCalibrated 5;
BA_ "SPN" SG_ 2565873150 SteerAngleSensorActiveMode 3687;
BA_ "SigType" SG_ 2565873150 SteerAngleSensorActiveMode 5;
BA_ "SPN" SG_ 2565873150 SteerWheelAngleRange 3686;
BA_ "GenSigStartValue" SG_ 2565873150 SteerWheelAngleRange 32127;
BA_ "SigType" SG_ 2565873150 SteerWheelAngleRange 1;
BA_ "SPN" SG_ 2565873150 SteerWheelAngleRangeCounterType 3685;
BA_ "SigType" SG_ 2565873150 SteerWheelAngleRangeCounterType 5;
BA_ "SPN" SG_ 2565873150 SteerWheelAngleRangeCounter 3684;
BA_ "SPN" SG_ 2565873150 SteerWheelAngle 3683;
BA_ "SigType" SG_ 2565873150 SteerWheelAngle 1;
BA_ "SPN" SG_ 2566745854 SysSulfationLvl 7504;
BA_ "SigType" SG_ 2566745854 SysSulfationLvl 1;
BA_ "SPN" SG_ 2566745854 SCROpIndActiveTraveledDist 5463;
BA_ "SigType" SG_ 2566745854 SCROpIndActiveTraveledDist 1;
BA_ "SPN" SG_ 2566745854 ConversionEfficiency 4364;
BA_ "SigType" SG_ 2566745854 ConversionEfficiency 1;
BA_ "SPN" SG_ 2566745854 CommandedDEFConsumption 3828;
BA_ "SigType" SG_ 2566745854 CommandedDEFConsumption 1;
BA_ "SPN" SG_ 2566745854 DEFAvgConsumption 3826;
BA_ "SigType" SG_ 2566745854 DEFAvgConsumption 1;
BA_ "SPN" SG_ 2566751230 MessageChecksum 9172;
BA_ "SPN" SG_ 2566751230 MessageCounter 9171;
BA_ "SPN" SG_ 2566751230 ActualGearRatio 9170;
BA_ "SigType" SG_ 2566751230 ActualGearRatio 1;
BA_ "SPN" SG_ 2566751230 DirStatus 8849;
BA_ "SigType" SG_ 2566751230 DirStatus 4;
BA_ "SPN" SG_ 2566751230 TransferCaseStatus 3645;
BA_ "SPN" SG_ 2566755838 TransOilLevel2MeasurementStatus 5916;
BA_ "SPN" SG_ 2566755838 TransOilLevel2CountdownTimer 5915;
BA_ "SPN" SG_ 2566755838 TransOilLevel2High_Low 5914;
BA_ "SigType" SG_ 2566755838 TransOilLevel2High_Low 1;
BA_ "SPN" SG_ 2566755838 TransOilTemp2 5913;
BA_ "SigType" SG_ 2566755838 TransOilTemp2 1;
BA_ "SPN" SG_ 2566755838 TransOilLifeRemaining 4177;
BA_ "SigType" SG_ 2566755838 TransOilLifeRemaining 1;
BA_ "SPN" SG_ 2566755838 TrnsTorqueConverterOilOutletTemp 3823;
BA_ "SigType" SG_ 2566755838 TrnsTorqueConverterOilOutletTemp 1;
BA_ "SPN" SG_ 2566755838 TransOverheatIndicator 5345;
BA_ "SigType" SG_ 2566755838 TransOverheatIndicator 5;
BA_ "SPN" SG_ 2566755838 TransOilLevelSwitch 3533;
BA_ "SigType" SG_ 2566755838 TransOilLevelSwitch 5;
BA_ "SPN" SG_ 2566755838 TransOilFilterRestrictionSwitch 3359;
BA_ "SigType" SG_ 2566755838 TransOilFilterRestrictionSwitch 5;
BA_ "SPN" SG_ 2566752766 VehicleRoll 3623;
BA_ "GenSigStartValue" SG_ 2566752766 VehicleRoll 14080;
BA_ "SigType" SG_ 2566752766 VehicleRoll 1;
BA_ "SPN" SG_ 2633938942 TotalEngCruiseTime 1017;
BA_ "SigType" SG_ 2633938942 TotalEngCruiseTime 1;
BA_ "SPN" SG_ 2633938942 TotalDriveAverageLoadFactor 1016;
BA_ "SigType" SG_ 2633938942 TotalDriveAverageLoadFactor 1;
BA_ "SPN" SG_ 2633938942 TripDriveAverageLoadFactor 1015;
BA_ "SigType" SG_ 2633938942 TripDriveAverageLoadFactor 1;
BA_ "SPN" SG_ 2633938942 TripAverageEngSpeed 1014;
BA_ "SigType" SG_ 2633938942 TripAverageEngSpeed 1;
BA_ "SPN" SG_ 2633938942 TripMaxEngSpeed 1013;
BA_ "SigType" SG_ 2633938942 TripMaxEngSpeed 1;
BA_ "SPN" SG_ 2566799614 ImplementRearWorkLight 2394;
BA_ "SigType" SG_ 2566799614 ImplementRearWorkLight 4;
BA_ "SPN" SG_ 2566799614 ImplementLeftFacingWorkLight 2400;
BA_ "SigType" SG_ 2566799614 ImplementLeftFacingWorkLight 4;
BA_ "SPN" SG_ 2566799614 ImplementRightForwardWorkLight 2402;
BA_ "SigType" SG_ 2566799614 ImplementRightForwardWorkLight 4;
BA_ "SPN" SG_ 2566799614 ImplementLeftForwardWorkLight 2598;
BA_ "SigType" SG_ 2566799614 ImplementLeftForwardWorkLight 4;
BA_ "SPN" SG_ 2566799614 ImplementRightFacingWorkLight 2407;
BA_ "SigType" SG_ 2566799614 ImplementRightFacingWorkLight 4;
BA_ "SPN" SG_ 2566799614 ImplementOEMOption1Light 2396;
BA_ "SigType" SG_ 2566799614 ImplementOEMOption1Light 4;
BA_ "SPN" SG_ 2566799614 ImplementOEMOption2Light 2398;
BA_ "SigType" SG_ 2566799614 ImplementOEMOption2Light 4;
BA_ "SPN" SG_ 2566799614 TrctorFrontHighMountedWorkLights 2356;
BA_ "SigType" SG_ 2566799614 TrctorFrontHighMountedWorkLights 4;
BA_ "SPN" SG_ 2566799614 TractorFrontLowMountedWorkLights 2354;
BA_ "SigType" SG_ 2566799614 TractorFrontLowMountedWorkLights 4;
BA_ "SPN" SG_ 2566799614 TractorSideHighMountedWorkLights 2366;
BA_ "SigType" SG_ 2566799614 TractorSideHighMountedWorkLights 4;
BA_ "SPN" SG_ 2566799614 TractorSideLowMountedWorkLights 2364;
BA_ "SigType" SG_ 2566799614 TractorSideLowMountedWorkLights 4;
BA_ "SPN" SG_ 2566799614 TractorRearHighMountedWorkLights 2362;
BA_ "SigType" SG_ 2566799614 TractorRearHighMountedWorkLights 4;
BA_ "SPN" SG_ 2566799614 TractorRearLowMountedWorkLights 2360;
BA_ "SigType" SG_ 2566799614 TractorRearLowMountedWorkLights 4;
BA_ "SPN" SG_ 2566799614 TrctorUndersideMountedWorkLights 2358;
BA_ "SigType" SG_ 2566799614 TrctorUndersideMountedWorkLights 4;
BA_ "SPN" SG_ 2566799614 RearFogLights 2390;
BA_ "SigType" SG_ 2566799614 RearFogLights 4;
BA_ "SPN" SG_ 2566799614 TractorMarkerLight 2378;
BA_ "SigType" SG_ 2566799614 TractorMarkerLight 4;
BA_ "SPN" SG_ 2566799614 ImplementMarkerLight 2380;
BA_ "SigType" SG_ 2566799614 ImplementMarkerLight 4;
BA_ "SPN" SG_ 2566799614 TractorClearanceLight 2382;
BA_ "SigType" SG_ 2566799614 TractorClearanceLight 4;
BA_ "SPN" SG_ 2566799614 ImplementClearanceLight 2384;
BA_ "SigType" SG_ 2566799614 ImplementClearanceLight 4;
BA_ "SPN" SG_ 2566799614 LeftStopLight 2372;
BA_ "SigType" SG_ 2566799614 LeftStopLight 4;
BA_ "SPN" SG_ 2566799614 RightStopLight 2374;
BA_ "SigType" SG_ 2566799614 RightStopLight 4;
BA_ "SPN" SG_ 2566799614 CenterStopLight 2376;
BA_ "SigType" SG_ 2566799614 CenterStopLight 4;
BA_ "SPN" SG_ 2566799614 BackUpLightAndAlarmHorn 2392;
BA_ "SigType" SG_ 2566799614 BackUpLightAndAlarmHorn 4;
BA_ "SPN" SG_ 2566799614 LeftTurnSignalLights 2368;
BA_ "SigType" SG_ 2566799614 LeftTurnSignalLights 4;
BA_ "SPN" SG_ 2566799614 RightTurnSignalLights 2370;
BA_ "SigType" SG_ 2566799614 RightTurnSignalLights 4;
BA_ "SPN" SG_ 2566799614 RotatingBeaconLight 2386;
BA_ "SigType" SG_ 2566799614 RotatingBeaconLight 4;
BA_ "SPN" SG_ 2566799614 TractorFrontFogLights 2388;
BA_ "SigType" SG_ 2566799614 TractorFrontFogLights 4;
BA_ "SPN" SG_ 2566799614 HighBeamHeadLightData 2348;
BA_ "SigType" SG_ 2566799614 HighBeamHeadLightData 4;
BA_ "SPN" SG_ 2566799614 LowBeamHeadLightData 2350;
BA_ "SigType" SG_ 2566799614 LowBeamHeadLightData 4;
BA_ "SPN" SG_ 2566799614 AltBeamHeadLightData 2352;
BA_ "SigType" SG_ 2566799614 AltBeamHeadLightData 4;
BA_ "SPN" SG_ 2566799614 RunningLight 2404;
BA_ "SigType" SG_ 2566799614 RunningLight 4;
BA_ "SPN" SG_ 2365473278 ImplementRearWorkLightCmd 2405;
BA_ "SigType" SG_ 2365473278 ImplementRearWorkLightCmd 5;
BA_ "SPN" SG_ 2365473278 ImplementLeftFacingWorkLightCmd 2399;
BA_ "SigType" SG_ 2365473278 ImplementLeftFacingWorkLightCmd 5;
BA_ "SPN" SG_ 2365473278 ImplmentRightForwardWorkLightCmd 2401;
BA_ "SigType" SG_ 2365473278 ImplmentRightForwardWorkLightCmd 5;
BA_ "SPN" SG_ 2365473278 LightingDataRqCmd 2393;
BA_ "SigType" SG_ 2365473278 LightingDataRqCmd 5;
BA_ "SPN" SG_ 2365473278 ImplementLeftForwardWorkLightCmd 2597;
BA_ "SigType" SG_ 2365473278 ImplementLeftForwardWorkLightCmd 5;
BA_ "SPN" SG_ 2365473278 ImplementRightFacingWorkLightCmd 2406;
BA_ "SigType" SG_ 2365473278 ImplementRightFacingWorkLightCmd 5;
BA_ "SPN" SG_ 2365473278 ImplementOEMOption1LightCmd 2395;
BA_ "SigType" SG_ 2365473278 ImplementOEMOption1LightCmd 5;
BA_ "SPN" SG_ 2365473278 ImplementOEMOption2LightCmd 2397;
BA_ "SigType" SG_ 2365473278 ImplementOEMOption2LightCmd 5;
BA_ "SPN" SG_ 2365473278 TrctrFrntHghMountedWorkLightsCmd 2355;
BA_ "SigType" SG_ 2365473278 TrctrFrntHghMountedWorkLightsCmd 5;
BA_ "SPN" SG_ 2365473278 TrctrFrntLowMountedWorkLightsCmd 2353;
BA_ "SigType" SG_ 2365473278 TrctrFrntLowMountedWorkLightsCmd 5;
BA_ "SPN" SG_ 2365473278 TrctrSdeHighMountedWorkLightsCmd 2365;
BA_ "SigType" SG_ 2365473278 TrctrSdeHighMountedWorkLightsCmd 5;
BA_ "SPN" SG_ 2365473278 TrctrSideLowMountedWorkLightsCmd 2363;
BA_ "SigType" SG_ 2365473278 TrctrSideLowMountedWorkLightsCmd 5;
BA_ "SPN" SG_ 2365473278 TrctrRarHighMountedWorkLightsCmd 2361;
BA_ "SigType" SG_ 2365473278 TrctrRarHighMountedWorkLightsCmd 5;
BA_ "SPN" SG_ 2365473278 TrctrRearLowMountedWorkLightsCmd 2359;
BA_ "SigType" SG_ 2365473278 TrctrRearLowMountedWorkLightsCmd 5;
BA_ "SPN" SG_ 2365473278 TrctrUndrsdeMountedWorkLightsCmd 2357;
BA_ "SigType" SG_ 2365473278 TrctrUndrsdeMountedWorkLightsCmd 5;
BA_ "SPN" SG_ 2365473278 RearFogLightCmd 2389;
BA_ "SigType" SG_ 2365473278 RearFogLightCmd 5;
BA_ "SPN" SG_ 2365473278 TractorMarkerLightCmd 2377;
BA_ "SigType" SG_ 2365473278 TractorMarkerLightCmd 5;
BA_ "SPN" SG_ 2365473278 ImplementMarkerLightCmd 2379;
BA_ "SigType" SG_ 2365473278 ImplementMarkerLightCmd 5;
BA_ "SPN" SG_ 2365473278 TractorClearanceLightCmd 2381;
BA_ "SigType" SG_ 2365473278 TractorClearanceLightCmd 5;
BA_ "SPN" SG_ 2365473278 ImplementClearanceLightCmd 2383;
BA_ "SigType" SG_ 2365473278 ImplementClearanceLightCmd 5;
BA_ "SPN" SG_ 2365473278 LeftStopLightCmd 2371;
BA_ "SigType" SG_ 2365473278 LeftStopLightCmd 5;
BA_ "SPN" SG_ 2365473278 RightStopLightCmd 2373;
BA_ "SigType" SG_ 2365473278 RightStopLightCmd 5;
BA_ "SPN" SG_ 2365473278 CenterStopLightCmd 2375;
BA_ "SigType" SG_ 2365473278 CenterStopLightCmd 5;
BA_ "SPN" SG_ 2365473278 BackUpLightAndAlarmHornCmd 2391;
BA_ "SigType" SG_ 2365473278 BackUpLightAndAlarmHornCmd 5;
BA_ "SPN" SG_ 2365473278 LeftTurnSignalLightsCmd 2367;
BA_ "SigType" SG_ 2365473278 LeftTurnSignalLightsCmd 5;
BA_ "SPN" SG_ 2365473278 RightTurnSignalLightsCmd 2369;
BA_ "SigType" SG_ 2365473278 RightTurnSignalLightsCmd 5;
BA_ "SPN" SG_ 2365473278 RotatingBeaconLightCmd 2385;
BA_ "SigType" SG_ 2365473278 RotatingBeaconLightCmd 5;
BA_ "SPN" SG_ 2365473278 TractorFrontFogLightsCmd 2387;
BA_ "SigType" SG_ 2365473278 TractorFrontFogLightsCmd 5;
BA_ "SPN" SG_ 2365473278 HighBeamHeadLightCmd 2347;
BA_ "SigType" SG_ 2365473278 HighBeamHeadLightCmd 5;
BA_ "SPN" SG_ 2365473278 LowBeamHeadLightCmd 2349;
BA_ "SigType" SG_ 2365473278 LowBeamHeadLightCmd 5;
BA_ "SPN" SG_ 2365473278 AltBeamHeadLightCmd 2351;
BA_ "SigType" SG_ 2365473278 AltBeamHeadLightCmd 5;
BA_ "SPN" SG_ 2365473278 RunningLightCmd 2403;
BA_ "SigType" SG_ 2365473278 RunningLightCmd 5;
VAL_ 2365402110 Joystick6Button13PressedStatus 3 "Not Available" 2 "Error Indicator" 1 "Button pressed" 0 "Button not pressed" ;
VAL_ 2365402110 Joystick6Button14PressedStatus 3 "Not Available" 2 "Error Indicator" 1 "Button pressed" 0 "Button not pressed" ;
VAL_ 2365402110 Joystick6Button15PressedStatus 3 "Not Available" 2 "Error Indicator" 1 "Button pressed" 0 "Button not pressed" ;
VAL_ 2365402110 Joystick6Button16PressedStatus 3 "Not Available" 2 "Error Indicator" 1 "Button pressed" 0 "Button not pressed" ;
VAL_ 2365402110 Jystick6GripXAxisDetentPosStatus 3 "Not Available" 2 "Error Indicator" 1 "In the Detent Position" 0 "Not in the Detent Position" ;
VAL_ 2365402110 Jystick6GripYAxisDetentPosStatus 3 "Not Available" 2 "Error Indicator" 1 "In the Detent Position" 0 "Not in the Detent Position" ;
VAL_ 2365402110 Jystick6ThetaAxisDetentPosStatus 3 "Not Available" 2 "Error Indicator" 1 "In the Detent Position" 0 "Not in the Detent Position" ;
VAL_ 2365402110 Jystck6ThtAxsClckwsPstvPosStatus 3 "Not Available" 2 "Error Indicator" 1 "On positive side of Neutral" 0 "Not on Positive side of Neutral" ;
VAL_ 2365402110 Jystck6ThtAxsCntrClckwsNgtvPsStt 3 "Not Available" 2 "Error Indicator" 1 "On negative side of Neutral" 0 "Not on negative side of Neutral" ;
VAL_ 2365402110 Jystck6ThetaAxisNeutralPosStatus 3 "Not Available" 2 "Error Indicator" 1 "In Neutral Position" 0 "Not in Neutral Position" ;
VAL_ 2365402110 Jystck6GrpYAxsLvrFrwrdPstvPsStts 3 "Not Available" 2 "Error Indicator" 1 "On positive side of Neutral" 0 "Not on Positive side of Neutral" ;
VAL_ 2365402110 Jystck6GrpYAxsLvrBckNgtvPsStatus 3 "Not Available" 2 "Error Indicator" 1 "On negative side of Neutral" 0 "Not on negative side of Neutral" ;
VAL_ 2365402110 Jystck6GripYAxisNeutralPosStatus 3 "Not Available" 2 "Error Indicator" 1 "In Neutral Position" 0 "Not in Neutral Position" ;
VAL_ 2365402110 Jystck6GrpXAxsLvrRghtPstvPsSttus 3 "Not Available" 2 "Error Indicator" 1 "On positive side of Neutral" 0 "Not on Positive side of Neutral" ;
VAL_ 2365402110 Jystck6GrpXAxsLvrLftNgtvPsStatus 3 "Not Available" 2 "Error Indicator" 1 "On negative side of Neutral" 0 "Not on negative side of Neutral" ;
VAL_ 2365402110 Jystck6GripXAxisNeutralPosStatus 3 "Not Available" 2 "Error Indicator" 1 "In Neutral Position" 0 "Not in Neutral Position" ;
VAL_ 2365402622 Joystick5Button13PressedStatus 3 "Not Available" 2 "Error Indicator" 1 "Button pressed" 0 "Button not pressed" ;
VAL_ 2365402622 Joystick5Button14PressedStatus 3 "Not Available" 2 "Error Indicator" 1 "Button pressed" 0 "Button not pressed" ;
VAL_ 2365402622 Joystick5Button15PressedStatus 3 "Not Available" 2 "Error Indicator" 1 "Button pressed" 0 "Button not pressed" ;
VAL_ 2365402622 Joystick5Button16PressedStatus 3 "Not Available" 2 "Error Indicator" 1 "Button pressed" 0 "Button not pressed" ;
VAL_ 2365402622 Jystick5GripXAxisDetentPosStatus 3 "Not Available" 2 "Error Indicator" 1 "In the Detent Position" 0 "Not in the Detent Position" ;
VAL_ 2365402622 Jystick5GripYAxisDetentPosStatus 3 "Not Available" 2 "Error Indicator" 1 "In the Detent Position" 0 "Not in the Detent Position" ;
VAL_ 2365402622 Jystick5ThetaAxisDetentPosStatus 3 "Not Available" 2 "Error Indicator" 1 "In the Detent Position" 0 "Not in the Detent Position" ;
VAL_ 2365402622 Jystck5ThtAxsClckwsPstvPosStatus 3 "Not Available" 2 "Error Indicator" 1 "On positive side of Neutral" 0 "Not on Positive side of Neutral" ;
VAL_ 2365402622 Jystck5ThtAxsCntrClckwsNgtvPsStt 3 "Not Available" 2 "Error Indicator" 1 "On negative side of Neutral" 0 "Not on negative side of Neutral" ;
VAL_ 2365402622 Jystck5ThetaAxisNeutralPosStatus 3 "Not Available" 2 "Error Indicator" 1 "In Neutral Position" 0 "Not in Neutral Position" ;
VAL_ 2365402622 Jystck5GrpYAxsLvrFrwrdPstvPsStts 3 "Not Available" 2 "Error Indicator" 1 "On positive side of Neutral" 0 "Not on Positive side of Neutral" ;
VAL_ 2365402622 Jystck5GrpYAxsLvrBckNgtvPsStatus 3 "Not Available" 2 "Error Indicator" 1 "On negative side of Neutral" 0 "Not on negative side of Neutral" ;
VAL_ 2365402622 Jystck5GripYAxisNeutralPosStatus 3 "Not Available" 2 "Error Indicator" 1 "In Neutral Position" 0 "Not in Neutral Position" ;
VAL_ 2365402622 Jystck5GrpXAxsLvrRghtPstvPsSttus 3 "Not Available" 2 "Error Indicator" 1 "On positive side of Neutral" 0 "Not on Positive side of Neutral" ;
VAL_ 2365402622 Jystck5GrpXAxsLvrLftNgtvPsStatus 3 "Not Available" 2 "Error Indicator" 1 "On negative side of Neutral" 0 "Not on negative side of Neutral" ;
VAL_ 2365402622 Jystck5GripXAxisNeutralPosStatus 3 "Not Available" 2 "Error Indicator" 1 "In Neutral Position" 0 "Not in Neutral Position" ;
VAL_ 2365403134 Joystick4Button13PressedStatus 3 "Not Available" 2 "Error Indicator" 1 "Button pressed" 0 "Button not pressed" ;
VAL_ 2365403134 Joystick4Button14PressedStatus 3 "Not Available" 2 "Error Indicator" 1 "Button pressed" 0 "Button not pressed" ;
VAL_ 2365403134 Joystick4Button15PressedStatus 3 "Not Available" 2 "Error Indicator" 1 "Button pressed" 0 "Button not pressed" ;
VAL_ 2365403134 Joystick4Button16PressedStatus 3 "Not Available" 2 "Error Indicator" 1 "Button pressed" 0 "Button not pressed" ;
VAL_ 2365403134 Jystick4GripXAxisDetentPosStatus 3 "Not Available" 2 "Error Indicator" 1 "In the Detent Position" 0 "Not in the Detent Position" ;
VAL_ 2365403134 Jystick4GripYAxisDetentPosStatus 3 "Not Available" 2 "Error Indicator" 1 "In the Detent Position" 0 "Not in the Detent Position" ;
VAL_ 2365403134 Jystick4ThetaAxisDetentPosStatus 3 "Not Available" 2 "Error Indicator" 1 "In the Detent Position" 0 "Not in the Detent Position" ;
VAL_ 2365403134 Jystck4ThtAxsClckwsPstvPosStatus 3 "Not Available" 2 "Error Indicator" 1 "On positive side of Neutral" 0 "Not on Positive side of Neutral" ;
VAL_ 2365403134 Jystck4ThtAxsCntrClckwsNgtvPsStt 3 "Not Available" 2 "Error Indicator" 1 "On negative side of Neutral" 0 "Not on negative side of Neutral" ;
VAL_ 2365403134 Jystck4ThetaAxisNeutralPosStatus 3 "Not Available" 2 "Error Indicator" 1 "In Neutral Position" 0 "Not in Neutral Position" ;
VAL_ 2365403134 Jystck4GrpYAxsLvrFrwrdPstvPsStts 3 "Not Available" 2 "Error Indicator" 1 "On positive side of Neutral" 0 "Not on Positive side of Neutral" ;
VAL_ 2365403134 Jystck4GrpYAxsLvrBckNgtvPsStatus 3 "Not Available" 2 "Error Indicator" 1 "On negative side of Neutral" 0 "Not on negative side of Neutral" ;
VAL_ 2365403134 Jystck4GripYAxisNeutralPosStatus 3 "Not Available" 2 "Error Indicator" 1 "In Neutral Position" 0 "Not in Neutral Position" ;
VAL_ 2365403134 Jystck4GrpXAxsLvrRghtPstvPsSttus 3 "Not Available" 2 "Error Indicator" 1 "On positive side of Neutral" 0 "Not on Positive side of Neutral" ;
VAL_ 2365403134 Jystck4GrpXAxsLvrLftNgtvPsStatus 3 "Not Available" 2 "Error Indicator" 1 "On negative side of Neutral" 0 "Not on negative side of Neutral" ;
VAL_ 2365403134 Jystck4GripXAxisNeutralPosStatus 3 "Not Available" 2 "Error Indicator" 1 "In Neutral Position" 0 "Not in Neutral Position" ;
VAL_ 2365400062 Joystick10Button13PressedStatus 3 "Not Available" 2 "Error Indicator" 1 "Button pressed" 0 "Button not pressed" ;
VAL_ 2365400062 Joystick10Button14PressedStatus 3 "Not Available" 2 "Error Indicator" 1 "Button pressed" 0 "Button not pressed" ;
VAL_ 2365400062 Joystick10Button15PressedStatus 3 "Not Available" 2 "Error Indicator" 1 "Button pressed" 0 "Button not pressed" ;
VAL_ 2365400062 Joystick10Button16PressedStatus 3 "Not Available" 2 "Error Indicator" 1 "Button pressed" 0 "Button not pressed" ;
VAL_ 2365400062 Jystck10GripXAxisDetentPosStatus 3 "Not Available" 2 "Error Indicator" 1 "In the Detent Position" 0 "Not in the Detent Position" ;
VAL_ 2365400062 Jystck10GripYAxisDetentPosStatus 3 "Not Available" 2 "Error Indicator" 1 "In the Detent Position" 0 "Not in the Detent Position" ;
VAL_ 2365400062 Jystck10ThetaAxisDetentPosStatus 3 "Not Available" 2 "Error Indicator" 1 "In the Detent Position" 0 "Not in the Detent Position" ;
VAL_ 2365400062 Jystck10ThtAxsClckwsPstvPsStatus 3 "Not Available" 2 "Error Indicator" 1 "On positive side of Neutral" 0 "Not on Positive side of Neutral" ;
VAL_ 2365400062 Jystck10ThtAxsCntrClckwsNgtvPsSt 3 "Not Available" 2 "Error Indicator" 1 "On negative side of Neutral" 0 "Not on negative side of Neutral" ;
VAL_ 2365400062 Jystck10ThtaAxisNeutralPosStatus 3 "Not Available" 2 "Error Indicator" 1 "In Neutral Position" 0 "Not in Neutral Position" ;
VAL_ 2365400062 Jystck10GrpYAxsLvrFrwrdPstvPsStt 3 "Not Available" 2 "Error Indicator" 1 "On positive side of Neutral" 0 "Not on Positive side of Neutral" ;
VAL_ 2365400062 Jystck10GrpYAxsLvrBckNgtvPsSttus 3 "Not Available" 2 "Error Indicator" 1 "On negative side of Neutral" 0 "Not on negative side of Neutral" ;
VAL_ 2365400062 Jystck10GrpYAxisNeutralPosStatus 3 "Not Available" 2 "Error Indicator" 1 "In Neutral Position" 0 "Not in Neutral Position" ;
VAL_ 2365400062 Jystck10GrpXAxsLvrRghtPstvPsStts 3 "Not Available" 2 "Error Indicator" 1 "On positive side of Neutral" 0 "Not on Positive side of Neutral" ;
VAL_ 2365400062 Jystck10GrpXAxsLvrLftNgtvPsSttus 3 "Not Available" 2 "Error Indicator" 1 "On negative side of Neutral" 0 "Not on negative side of Neutral" ;
VAL_ 2365400062 Jystck10GrpXAxisNeutralPosStatus 3 "Not Available" 2 "Error Indicator" 1 "In Neutral Position" 0 "Not in Neutral Position" ;
VAL_ 2566713598 FuelTankTransferPump 3 "Not available" 2 "Error" 1 "On" 0 "Off" ;
VAL_ 2566749438 ActiveRegenAvailabilityStatus 3 "Not Available" 2 "Reserved" 1 "Ready for initiation" 0 "Not ready for initiation" ;
VAL_ 2566749438 DslPrtcltFltrActvRgnrtnInhbt5629 3 "not available" 2 "reserved for SAE assignment" 1 "inhibited" 0 "not inhibited" ;
VAL_ 2566749438 AFT1DPFCondNotMetForActiveRegen 3 "not available" 2 "reserved for SAE assignment" 1 "active DPF regeneration inhibited" 0 "active DPF regeneration not inhibited" ;
VAL_ 2566749438 HydrocarbonDoserPurgingEnable 3 "Not available" 2 "Purging enabled, urgent" 1 "Purging enabled, less urgent" 0 "Purging not enabled" ;
VAL_ 2566749438 DslPrtcltFltrActvRgnrtnFrcdSttus 7 "not available" 6 "Reserved for SAE Assignment" 5 "Reserved for SAE Assignment" 4 "Reserved for SAE Assignment" 3 "Reserved for SAE Assignment" 2 "Active, Forced by Service Tool" 1 "Active, Forced by Switch" 0 "Not Active" ;
VAL_ 2566749438 ExhaustSystemHighTempLampCmd 7 "not available" 6 "reserved for SAE assignment" 5 "reserved for SAE assignment" 4 "reserved for SAE assignment" 3 "reserved for SAE assignment" 2 "reserved for SAE assignment" 1 "On" 0 "Off" ;
VAL_ 2566749438 DslPrtcltFltrAtmtcActvRgnrtnIntt 3 "not available" 2 "reserved for SAE assignment" 1 "enabled" 0 "not enabled" ;
VAL_ 2566749438 DslPrtcltFltrActvRgnrtnInhbt3717 3 "not available" 2 "reserved for SAE assignment" 1 "inhibited" 0 "not inhibited" ;
VAL_ 2566749438 DslPrtcltFltrActvRgnrtnInhbtdDTE 3 "not available" 2 "reserved for SAE assignment" 1 "inhibited" 0 "not inhibited" ;
VAL_ 2566749438 DslPrtcltFltrActvRgnrtnInhbt3715 3 "not available" 2 "reserved for SAE assignment" 1 "inhibited" 0 "not inhibited" ;
VAL_ 2566749438 DslPrtcltFltrActvRgnrtnInhbtdDTT 3 "not available" 2 "reserved for SAE assignment" 1 "inhibited" 0 "not inhibited" ;
VAL_ 2566749438 DslPrtcltFltrActvRgnrtnInhbt3713 3 "not available" 2 "reserved for SAE assignment" 1 "inhibited" 0 "not inhibited" ;
VAL_ 2566749438 DslPrtcltFltrActvRgnrtnInhbt3712 3 "not available" 2 "reserved for SAE assignment" 1 "inhibited" 0 "not inhibited" ;
VAL_ 2566749438 DslPrtcltFltrActvRgnrtnInhbtdDTL 3 "not available" 2 "reserved for SAE assignment" 1 "inhibited" 0 "not inhibited" ;
VAL_ 2566749438 DslPrtcltFltrActvRgnrtnInhbt3710 3 "not available" 2 "reserved for SAE assignment" 1 "inhibited" 0 "not inhibited" ;
VAL_ 2566749438 DslPrtcltFltrActvRgnrtnInhbtdDTV 3 "not available" 2 "reserved for SAE assignment" 1 "inhibited" 0 "not inhibited" ;
VAL_ 2566749438 DslPrtcltFltrActvRgnrtnInhbtdDTO 3 "not available" 2 "reserved for SAE assignment" 1 "inhibited" 0 "not inhibited" ;
VAL_ 2566749438 DslPrtcltFltrActvRgnrtnInhbtdDTA 3 "not available" 2 "reserved for SAE assignment" 1 "inhibited" 0 "not inhibited" ;
VAL_ 2566749438 DslPrtcltFltrActvRgnrtnInhbtdDTP 3 "not available" 2 "reserved for SAE assignment" 1 "inhibited" 0 "not inhibited" ;
VAL_ 2566749438 DslPrtcltFltrActvRgnrtnInhbtdDTS 3 "not available" 2 "reserved for SAE assignment" 1 "inhibited" 0 "not inhibited" ;
VAL_ 2566749438 DslPrtcltFltrActvRgnrtnInhbtdDTC 3 "not available" 2 "reserved for SAE assignment" 1 "inhibited" 0 "not inhibited" ;
VAL_ 2566749438 DslPrtcltFltrActvRgnrtnInhbtdDTI 3 "not available" 2 "reserved for SAE assignment" 1 "inhibited" 0 "not inhibited" ;
VAL_ 2566749438 DslPrtcltFltrActvRgnrtnInhbtdStt 3 "not available" 2 "reserved for SAE assignment" 1 "inhibited" 0 "not inhibited" ;
VAL_ 2566749438 AFTDPFStatus 7 "not available" 6 "reserved for SAE assignment" 5 "reserved for SAE assignment" 4 "reserved for SAE assignment" 3 "Regeneration needed, highest level" 2 "Regeneration needed, moderate level" 1 "Regeneration needed, lowest level" 0 "Regeneration not needed" ;
VAL_ 2566749438 AFTDPFActiveRegenStatus 3 "not available" 2 "regeneration needed" 1 "active" 0 "not active" ;
VAL_ 2566749438 AFTDPFPassiveRegenStatus 3 "not available" 2 "reserved for SAE assignment" 1 "active" 0 "not active" ;
VAL_ 2566749438 DieselParticulateFilterLampCmd 3 "reserved for SAE assignment" 2 "reserved for SAE assignment" 1 "On, solid" 0 "Off" 7 "not available" 6 "reserved for SAE assignment" 5 "reserved for SAE assignment" 4 "On, fast blink" ;
VAL_ 2566718718 HillHolderLampData 3 "Not Available" 2 "Error" 1 "Lamp activated" 0 "Lamp deactivated" ;
VAL_ 2566718718 VehicleBatteryChargingLampData 3 "Not available" 2 "Error" 1 "Lamp activated" 0 "Lamp deactivated" ;
VAL_ 2566718718 VehicleHVACRecirculationLampData 3 "Not available" 2 "Error" 1 "Lamp activated" 0 "Lamp deactivated" ;
VAL_ 2566718718 VehicleAirPressLowLampData 3 "Not available" 2 "Error" 1 "Lamp activated" 0 "Lamp deactivated" ;
VAL_ 2566718718 VehicleFuelLevelLowLampData 3 "Not available" 2 "Error" 1 "Lamp activated" 0 "Lamp deactivated" ;
VAL_ 2566718718 VehicleBatteryVoltageLowLampData 3 "Not available" 2 "Error" 1 "Lamp activated" 0 "Lamp deactivated" ;
VAL_ 2566718974 EngStopStartEnabledLamp 3 "Not available" 2 "Error" 1 "Lamp activated" 0 "Lamp deactivated" ;
VAL_ 2566718974 EngStopStartAutoStartFailedLamp 3 "Not available" 2 "Error" 1 "Lamp activated" 0 "Lamp deactivated" ;
VAL_ 2566718974 EngStopStartAutoStopActiveLamp 3 "Not available" 2 "Error" 1 "Lamp activated" 0 "Lamp deactivated" ;
VAL_ 2566718974 VhclAcclerationRateLimitLampData 3 "Not available" 2 "Error" 1 "Lamp activated" 0 "Lamp deactivated" ;
VAL_ 2566718974 EngSpeedVeryHighLampData 3 "Not available" 2 "Error" 1 "Lamp Activated" 0 "Lamp Deactivated" ;
VAL_ 2566718974 EngSpeedHighLampData 0 "Lamp Deactivated" 3 "Not available" 2 "Error" 1 "Lamp Activated" ;
VAL_ 2566718974 EngCtrlMdule3ReadyForUseLampData 3 "Not Available" 2 "Error" 1 "Lamp activated" 0 "Lamp deactivated" ;
VAL_ 2566718974 EngCtrlMdule2ReadyForUseLampData 3 "Not Available" 2 "Error" 1 "Lamp activated" 0 "Lamp deactivated" ;
VAL_ 2566718974 EngCtrlMdule1ReadyForUseLampData 3 "Not Available" 2 "Error" 1 "Lamp activated" 0 "Lamp deactivated" ;
VAL_ 2566718974 EngWaitToStartLampData 3 "Not available" 2 "Error" 1 "Lamp actived" 0 "Lamp deactived" ;
VAL_ 2566718974 EngFuelFilterRestrictedLampData 3 "Not available" 2 "Error" 1 "Lamp activated" 0 "Lamp deactivated" ;
VAL_ 2566718974 EngAirFilterRestrictionLampData 3 "Not available" 2 "Error" 1 "Lamp activated" 0 "Lamp deactivated" ;
VAL_ 2566718974 EngIdleManagementActiveLampData 3 "Not available" 2 "Error" 1 "Lamp activated" 0 "Lamp deactivated" ;
VAL_ 2566718974 EngCoolantLevelLowLampData 3 "Not available" 2 "Error" 1 "Lamp activated" 0 "Lamp deactivated" ;
VAL_ 2566718974 EngCoolantTempHighLampData 3 "Not available" 2 "Error" 1 "Lamp activated" 0 "Lamp deactivated" ;
VAL_ 2566718974 EngOilPressLowLampData 3 "Not available" 2 "Error" 1 "Lamp activated" 0 "Lamp deactivated" ;
VAL_ 2566718974 CmprssnBrkEnblSwtchIndctrLmpData 3 "Not available" 2 "Error" 1 "Lamp activated" 0 "Lamp deactivated" ;
VAL_ 2566718974 EngBrakeActiveLampData 3 "Not available" 2 "Error" 1 "Lamp activated" 0 "Lamp deactivated" ;
VAL_ 2566718974 OBDMalfunctionIndicatorLampData 3 "Not available" 2 "Error" 1 "Lamp activated" 0 "Lamp deactivated" ;
VAL_ 2566718974 EngRedStopLampData 3 "Not available" 2 "Error" 1 "Lamp activated" 0 "Lamp deactivated" ;
VAL_ 2566718974 EngAmberWarningLampData 3 "Not available" 2 "Error" 1 "Lamp activated" 0 "Lamp deactivated" ;
VAL_ 2566718974 EngProtectLampData 3 "Not available" 2 "Error" 1 "Lamp activated" 0 "Lamp deactivated" ;
VAL_ 2566719230 HillHolderLampCmd 3 "Not available" 2 "Lamp Flash" 1 "Lamp On" 0 "Lamp Off" ;
VAL_ 2566719230 VehicleBatteryChargingLampCmd 3 "Not available" 2 "Reserved" 1 "Lamp On" 0 "Lamp Off" ;
VAL_ 2566719230 VehicleHVACRecirculationLampCmd 3 "Not available" 2 "Reserved" 1 "Lamp On" 0 "Lamp Off" ;
VAL_ 2566719230 VehicleAirPressLowLampCmd 3 "Not available" 2 "Reserved" 1 "Lamp On" 0 "Lamp Off" ;
VAL_ 2566719230 VehicleFuelLevelLowLampCmd 3 "Not available" 2 "Reserved" 1 "Lamp On" 0 "Lamp Off" ;
VAL_ 2566719230 VehicleBatteryVoltageLowLampCmd 3 "Not available" 2 "Reserved" 1 "Lamp On" 0 "Lamp Off" ;
VAL_ 2560818942 FailureModeIdentifier1 31 "Not available" 19 "Received network data in error" 18 "Below normal (moderately severe)" 17 "Below normal (least severe)" 16 "Above normal (moderately severe)" 15 "Above normal (least severe)" 14 "Special intstructions" 13 "Out of calibration" 12 "Bad intelligent device" 11 "Root cause not known" 10 "Abnormal rate of change" 9 "Abnormal update rate" 8 "Abnormal frequency" 7 "Mechanical system not responding" 6 "Current above normal" 5 "Current below normal" 4 "Voltage below normal" 3 "Voltage above normal" 2 "Data erratic" 1 "Below normal (most severe)" 0 "Above normal (most severe)" ;
VAL_ 2561212158 TextDisplayInstructions 15 "Not applicable" 6 "Blink substring" 5 "Highlight substring" 4 "Overwrite substring" 3 "Overwrite display" 2 "Append at end of display" 1 "Hold display" 0 "Clear display" ;
VAL_ 2566746366 RetractStatusOfRamp5 3 "not available" 2 "error" 1 "ramp extended" 0 "ramp retracted" ;
VAL_ 2566746366 RetractStatusOfRamp4 3 "not available" 2 "error" 1 "ramp extended" 0 "ramp retracted" ;
VAL_ 2566746366 MovementStatusOfRamp5 3 "not available" 2 "error" 1 "ramp being moved" 0 "ramp not being moved" ;
VAL_ 2566746366 MovementStatusOfRamp4 3 "not available" 2 "error" 1 "ramp being moved" 0 "ramp not being moved" ;
VAL_ 2566746366 EnableStatusOfRamp5 3 "not available" 2 "error" 1 "ramp enabled" 0 "ramp disabled" ;
VAL_ 2566746366 EnableStatusOfRamp4 3 "not available" 2 "error" 1 "ramp enabled" 0 "ramp disabled" ;
VAL_ 2566746366 MovementStatusOfRamp3 3 "not available" 2 "error" 1 "ramp being moved" 0 "ramp not being moved" ;
VAL_ 2566746366 EnableStatusOfRamp3 3 "not available" 2 "error" 1 "ramp enabled" 0 "ramp disabled" ;
VAL_ 2566746366 RetractStatusOfRamp3 3 "not available" 2 "error" 1 "ramp extended" 0 "ramp retracted" ;
VAL_ 2566746366 MovementStatusOfRamp2 3 "not available" 2 "error" 1 "ramp being moved" 0 "ramp not being moved" ;
VAL_ 2566746366 EnableStatusOfRamp2 3 "not available" 2 "error" 1 "ramp enabled" 0 "ramp disabled" ;
VAL_ 2566746366 RetractStatusOfRamp2 3 "not available" 2 "error" 1 "ramp extended" 0 "ramp retracted" ;
VAL_ 2566746366 MovementStatusOfRamp1 3 "not available" 2 "error" 1 "ramp being moved" 0 "ramp not being moved" ;
VAL_ 2566746366 EnableStatusOfRamp1 3 "not available" 2 "error" 1 "ramp enabled" 0 "ramp disabled" ;
VAL_ 2566746366 RetractStatusOfRamp1 3 "not available" 2 "error" 1 "ramp extended" 0 "ramp retracted" ;
VAL_ 2566750206 TransIdleGovFuelingInhSupport 3 "Not supported" 2 "Reserved for future SAE use" 1 "Indicates that the engine will respond to a 밫ransmission Idle Governor Fueling Inhibit� command from the Transmission" 0 "Indicates that the engine does not support the 밫ransmission Idle Governor Fueling Inhibit� feature" ;
VAL_ 2561277694 ReqActiveSteerDriverPrefMode 7 "Don't Care/Take No Action" 6 "Error" 5 "Requested Active Steering Mode #6" 4 "Requested Active Steering Mode #5" 3 "Requested Active Steering Mode #4" 2 "Requested Active Steering Mode #3" 1 "Requested Active Steering Mode #2" 0 "Requested Active Steering Mode #1" ;
VAL_ 2561277694 CenteringEnableCmd 3 "Don큧 care" 2 "Reserved" 1 "Enable lane centering" 0 "Disable lane centering" ;
VAL_ 2561277694 KeepingAssistEnableCmd 3 "Don큧 care" 2 "Reserved" 1 "Enable lane keeping assist" 0 "Disable lane keeping assist" ;
VAL_ 2561277694 LaneDepartureWarningEnableCmd 3 "Don큧 care" 2 "Reserved" 1 "Enable Lane Departure Warning" 0 "Disable Lane Departure Warning" ;
VAL_ 2633861886 J2012DTCStatus 1 "DTC is active" 0 "DTC is previously active" ;
VAL_ 2565873150 SteerAngleSensorCalibrated 3 "Not available" 2 "Reserved" 1 "SAS calibrated" 0 "SAS not calibrated" ;
VAL_ 2565873150 SteerAngleSensorActiveMode 3 "Not available" 2 "Reserved" 1 "Normal mode active" 0 "Programming mode active" ;
VAL_ 2565873150 SteerWheelAngleRangeCounterType 3 "signal not available" 2 "not defined" 1 "absolute number of counts" 0 "relative number of counts" ;
VAL_ 2566751230 DirStatus 3 "Not Available" 2 "Error" 1 "Reverse" 0 "Forward" ;
VAL_ 2566751230 TransferCaseStatus 7 "not available" 6 "error" 5 "Transfer Case Shift in Progress or gear not confirmed" 4 "4 wheel low" 3 "2 wheel low" 2 "neutral" 1 "4 wheel high" 0 "2 wheel high" ;
VAL_ 2566755838 TransOilLevel2MeasurementStatus 15 "Not available" 14 "Error" 13 "Conditions not valid, Other" 12 "Not defined" 11 "Not defined" 10 "Not defined" 9 "Conditions not valid, No request for reading" 8 "Conditions not valid, Engine speed too high" 7 "Conditions not valid, Engine speed too low" 6 "Conditions not valid, Vehicle not level" 5 "Conditions not valid, Vehicle moving" 4 "Conditions not valid, Transmission fluid temperature too high" 3 "Conditions not valid, Transmission fluid temperature too low" 2 "Conditions not valid, Transmission in gear" 1 "Conditions not valid, Settling timer still counting down" 0 "Conditions valid for transmission oil level measurement" ;
VAL_ 2566755838 TransOilLevel2CountdownTimer 15 "Not Available" 14 "Error" 13 "Thirteen minutes" 12 "Twelve minutes" 11 "Eleven minutes" 10 "Ten minutes" 9 "Nine minutes" 8 "Eight minutes" 7 "Seven minutes" 6 "Six minutes" 5 "Five minutes" 4 "Four minutes" 3 "Three minutes" 2 "Two minutes" 1 "One minute" 0 "less than 1 minute" ;
VAL_ 2566755838 TransOverheatIndicator 3 "Not available" 2 "Transmission Overheat Indicator is flashing" 1 "Transmission Overheat Indicator is on continuously" 0 "Transmission Overheat Indicator is off" ;
VAL_ 2566755838 TransOilLevelSwitch 3 "Not available" 2 "Error" 1 "Full or not empty" 0 "Empty" ;
VAL_ 2566755838 TransOilFilterRestrictionSwitch 3 "Not available" 2 "Error" 1 "Restriction exists on oil filter" 0 "No restriction" ;
VAL_ 2566799614 ImplementRearWorkLight 3 "Not Available" 2 "Fault Detected" 1 "Activated" 0 "De-activated" ;
VAL_ 2566799614 ImplementLeftFacingWorkLight 3 "Not Available" 2 "Fault Detected" 1 "Activated" 0 "De-activated" ;
VAL_ 2566799614 ImplementRightForwardWorkLight 3 "Not Available" 2 "Fault Detected" 1 "Activated" 0 "De-activated" ;
VAL_ 2566799614 ImplementLeftForwardWorkLight 3 "Not Available" 2 "Fault Detected" 1 "Activate" 0 "De-activate" ;
VAL_ 2566799614 ImplementRightFacingWorkLight 3 "Not Available" 2 "Fault Detected" 1 "Activated" 0 "De-activated" ;
VAL_ 2566799614 ImplementOEMOption1Light 3 "Not Available" 2 "Fault Detected" 1 "Activated" 0 "De-activated" ;
VAL_ 2566799614 ImplementOEMOption2Light 3 "Not Available" 2 "Fault Detected" 1 "Activated" 0 "De-activated" ;
VAL_ 2566799614 TrctorFrontHighMountedWorkLights 3 "Not Available" 2 "Fault Detected" 1 "Activated" 0 "De-activated" ;
VAL_ 2566799614 TractorFrontLowMountedWorkLights 3 "Not Available" 2 "Fault Detected" 1 "Activated" 0 "De-activated" ;
VAL_ 2566799614 TractorSideHighMountedWorkLights 3 "Not Available" 2 "Fault Detected" 1 "Activated" 0 "De-activated" ;
VAL_ 2566799614 TractorSideLowMountedWorkLights 3 "Not Available" 2 "Fault Detected" 1 "Activated" 0 "De-activated" ;
VAL_ 2566799614 TractorRearHighMountedWorkLights 3 "Not Available" 2 "Fault Detected" 1 "Activated" 0 "De-activated" ;
VAL_ 2566799614 TractorRearLowMountedWorkLights 3 "Not Available" 2 "Fault Detected" 1 "Activated" 0 "De-activated" ;
VAL_ 2566799614 TrctorUndersideMountedWorkLights 3 "Not Available" 2 "Fault Detected" 1 "Activated" 0 "De-activated" ;
VAL_ 2566799614 RearFogLights 3 "Not Available" 2 "Fault Detected" 1 "Activated" 0 "De-activated" ;
VAL_ 2566799614 TractorMarkerLight 3 "Not Available" 2 "Fault Detected" 1 "Activated" 0 "De-activated" ;
VAL_ 2566799614 ImplementMarkerLight 3 "Not Available" 2 "Fault Detected" 1 "Activated" 0 "De-activated" ;
VAL_ 2566799614 TractorClearanceLight 3 "Not Available" 2 "Fault Detected" 1 "Activated" 0 "De-activated" ;
VAL_ 2566799614 ImplementClearanceLight 3 "Not Available" 2 "Fault Detected" 1 "Activated" 0 "De-activated" ;
VAL_ 2566799614 LeftStopLight 3 "Not Available" 2 "Fault Detected" 1 "Activated" 0 "De-activated" ;
VAL_ 2566799614 RightStopLight 3 "Not Available" 2 "Fault Detected" 1 "Activated" 0 "De-activated" ;
VAL_ 2566799614 CenterStopLight 3 "Not Available" 2 "Fault Detected" 1 "Activated" 0 "De-activated" ;
VAL_ 2566799614 BackUpLightAndAlarmHorn 3 "Not Available" 2 "Fault Detected" 1 "Activated" 0 "De-activated" ;
VAL_ 2566799614 LeftTurnSignalLights 3 "Not Available" 2 "Fault Detected" 1 "Activated" 0 "De-activated" ;
VAL_ 2566799614 RightTurnSignalLights 3 "Not Available" 2 "Fault Detected" 1 "Activated" 0 "De-activated" ;
VAL_ 2566799614 RotatingBeaconLight 3 "Not Available" 2 "Fault Detected" 1 "Activated" 0 "De-activated" ;
VAL_ 2566799614 TractorFrontFogLights 3 "Not Available" 2 "Fault Detected" 1 "Activated" 0 "De-activated" ;
VAL_ 2566799614 HighBeamHeadLightData 3 "Not Available" 2 "Fault Detected" 1 "Activated" 0 "De-activated" ;
VAL_ 2566799614 LowBeamHeadLightData 3 "Not Available" 2 "Fault Detected" 1 "Activated" 0 "De-activated" ;
VAL_ 2566799614 AltBeamHeadLightData 3 "Not Available" 2 "Fault Detected" 1 "Activated" 0 "De-activated" ;
VAL_ 2566799614 RunningLight 3 "Not Available" 2 "Fault Detected" 1 "Activated" 0 "De-activated" ;
VAL_ 2365473278 ImplementRearWorkLightCmd 3 "Don뭪 Care" 2 "Reserved" 1 "Activate" 0 "De-activate" ;
VAL_ 2365473278 ImplementLeftFacingWorkLightCmd 3 "Don뭪 Care" 2 "Reserved" 1 "Activate" 0 "De-activate" ;
VAL_ 2365473278 ImplmentRightForwardWorkLightCmd 3 "Don뭪 Care" 2 "Reserved" 1 "Activate" 0 "De-activate" ;
VAL_ 2365473278 LightingDataRqCmd 3 "Don뭪 Care" 2 "Reserved" 1 "Activate" 0 "De-activate" ;
VAL_ 2365473278 ImplementLeftForwardWorkLightCmd 3 "Don뭪 Care" 2 "Reserved" 1 "Activate" 0 "De-activate" ;
VAL_ 2365473278 ImplementRightFacingWorkLightCmd 3 "Don뭪 Care" 2 "Reserved" 1 "Activate" 0 "De-activate" ;
VAL_ 2365473278 ImplementOEMOption1LightCmd 3 "Don뭪 Care" 2 "Reserved" 1 "Activate" 0 "De-activate" ;
VAL_ 2365473278 ImplementOEMOption2LightCmd 3 "Don뭪 Care" 2 "Reserved" 1 "Activate" 0 "De-activate" ;
VAL_ 2365473278 TrctrFrntHghMountedWorkLightsCmd 3 "Don뭪 Care" 2 "Reserved" 1 "Activate" 0 "De-activate" ;
VAL_ 2365473278 TrctrFrntLowMountedWorkLightsCmd 3 "Don뭪 Care" 2 "Reserved" 1 "Activate" 0 "De-activate" ;
VAL_ 2365473278 TrctrSdeHighMountedWorkLightsCmd 3 "Don뭪 Care" 2 "Reserved" 1 "Activate" 0 "De-activate" ;
VAL_ 2365473278 TrctrSideLowMountedWorkLightsCmd 3 "Don뭪 Care" 2 "Reserved" 1 "Activate" 0 "De-activate" ;
VAL_ 2365473278 TrctrRarHighMountedWorkLightsCmd 3 "Don뭪 Care" 2 "Reserved" 1 "Activate" 0 "De-activate" ;
VAL_ 2365473278 TrctrRearLowMountedWorkLightsCmd 3 "Don뭪 Care" 2 "Reserved" 1 "Activate" 0 "De-activate" ;
VAL_ 2365473278 TrctrUndrsdeMountedWorkLightsCmd 3 "Don뭪 Care" 2 "Reserved" 1 "Activate" 0 "De-activate" ;
VAL_ 2365473278 RearFogLightCmd 3 "Don뭪 Care" 2 "Reserved" 1 "Activate" 0 "De-activate" ;
VAL_ 2365473278 TractorMarkerLightCmd 3 "Don뭪 Care" 2 "Reserved" 1 "Activate" 0 "De-activate" ;
VAL_ 2365473278 ImplementMarkerLightCmd 2 "Reserved" 3 "Don뭪 Care" 1 "Activate" 0 "De-activate" ;
VAL_ 2365473278 TractorClearanceLightCmd 3 "Don뭪 Care" 2 "Reserved" 1 "Activate" 0 "De-activate" ;
VAL_ 2365473278 ImplementClearanceLightCmd 3 "Don뭪 Care" 2 "Reserved" 1 "Activate" 0 "De-activate" ;
VAL_ 2365473278 LeftStopLightCmd 3 "Don뭪 Care" 2 "Reserved" 1 "Activate" 0 "De-activate" ;
VAL_ 2365473278 RightStopLightCmd 3 "Don뭪 Care" 2 "Reserved" 1 "Activate" 0 "De-activate" ;
VAL_ 2365473278 CenterStopLightCmd 3 "Don뭪 Care" 2 "Reserved" 1 "Activate" 0 "De-activate" ;
VAL_ 2365473278 BackUpLightAndAlarmHornCmd 3 "Don뭪 Care" 2 "Reserved" 1 "Activate" 0 "De-activate" ;
VAL_ 2365473278 LeftTurnSignalLightsCmd 3 "Don뭪 Care" 2 "Reserved" 1 "Activate" 0 "De-activate" ;
VAL_ 2365473278 RightTurnSignalLightsCmd 3 "Don뭪 Care" 2 "Reserved" 1 "Activate" 0 "De-activate" ;
VAL_ 2365473278 RotatingBeaconLightCmd 3 "Don뭪 Care" 2 "Reserved" 1 "Activate" 0 "De-activate" ;
VAL_ 2365473278 TractorFrontFogLightsCmd 3 "Don뭪 Care" 2 "Reserved" 1 "Activate" 0 "De-activate" ;
VAL_ 2365473278 HighBeamHeadLightCmd 3 "Don뭪 Care" 2 "Reserved" 1 "Activate" 0 "De-activate" ;
VAL_ 2365473278 LowBeamHeadLightCmd 3 "Don뭪 Care" 2 "Reserved" 1 "Activate" 0 "De-activate" ;
VAL_ 2365473278 AltBeamHeadLightCmd 3 "Don뭪 Care" 2 "Reserved" 1 "Activate" 0 "De-activate" ;
VAL_ 2365473278 RunningLightCmd 3 "Don뭪 Care" 2 "Reserved" 1 "Activate" 0 "De-activate" ;
